VERSION ""

NS_ :

BS_:

BU_: Vector__XXX

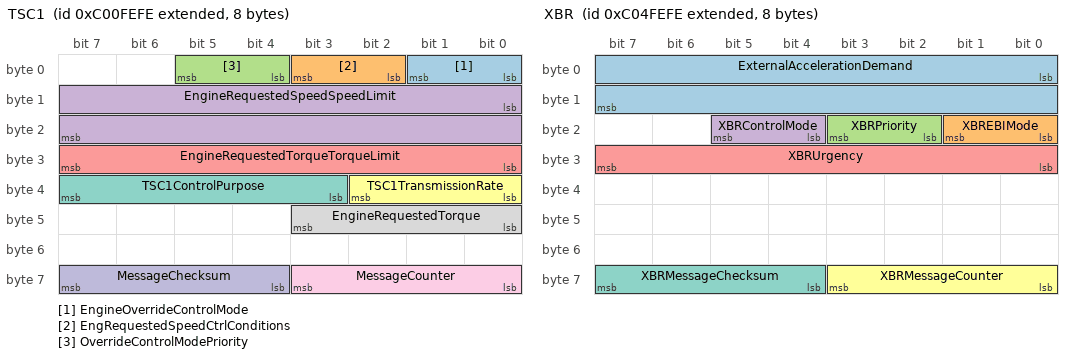
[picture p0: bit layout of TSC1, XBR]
BO_ 2348875518 TSC1: 8 Vector__XXX
SG_ EngineOverrideControlMode : 0|2@1+ (1,0) [0|3] "" Vector__XXX
SG_ EngRequestedSpeedCtrlConditions : 2|2@1+ (1,0) [0|3] "" Vector__XXX
SG_ OverrideControlModePriority : 4|2@1+ (1,0) [0|3] "" Vector__XXX
SG_ EngineRequestedSpeedSpeedLimit : 8|16@1+ (0.125,0) [0|8031.875] "rpm" Vector__XXX
SG_ EngineRequestedTorqueTorqueLimit : 24|8@1+ (1,-125) [-125|125] "%" Vector__XXX
SG_ TSC1TransmissionRate : 32|3@1+ (1,0) [0|7] "" Vector__XXX
SG_ TSC1ControlPurpose : 35|5@1+ (1,0) [0|31] "" Vector__XXX
SG_ EngineRequestedTorque : 40|4@1+ (0.125,0) [0|0.875] "%" Vector__XXX
SG_ MessageCounter : 56|4@1+ (1,0) [0|15] "" Vector__XXX
SG_ MessageChecksum : 60|4@1+ (1,0) [0|15] "" Vector__XXX

BO_ 2348941054 TC1: 8 Vector__XXX
SG_ TransmissionGearShiftInhbtRq : 0|2@1+ (1,0) [0|3] "" Vector__XXX
SG_ TrnsmTrqCnvLockupDisableRq : 2|2@1+ (1,0) [0|3] "" Vector__XXX
SG_ DisengageDrivelineRequest : 4|2@1+ (1,0) [0|3] "" Vector__XXX
SG_ TrnsmReverseGearShftInhbtRq : 6|2@1+ (1,0) [0|3] "" Vector__XXX
SG_ RequestedPercentClutchSlip : 8|8@1+ (0.4,0) [0|100] "%" Vector__XXX
SG_ TransmissionRequestedGear : 16|8@1+ (1,-125) [-125|125] "" Vector__XXX
SG_ DisengiffLockRequestFrontAxl1 : 24|2@1+ (1,0) [0|3] "" Vector__XXX
SG_ DisengiffLockRequestFrontAxl2 : 26|2@1+ (1,0) [0|3] "" Vector__XXX
SG_ DisengageDiffLockRequestRearAxl1 : 28|2@1+ (1,0) [0|3] "" Vector__XXX
SG_ DisengageDiffLockRequestRearAxl2 : 30|2@1+ (1,0) [0|3] "" Vector__XXX
SG_ DisengageDiffLockRequestCentral : 32|2@1+ (1,0) [0|3] "" Vector__XXX
SG_ DisengiffLockRequestCentralFront : 34|2@1+ (1,0) [0|3] "" Vector__XXX
SG_ DisengiffLockRequestCentralRear : 36|2@1+ (1,0) [0|3] "" Vector__XXX
SG_ TransmissionLoadRedInhbtRequest : 38|2@1+ (1,0) [0|3] "" Vector__XXX
SG_ TransmissionMode1 : 40|2@1+ (1,0) [0|3] "" Vector__XXX
SG_ TransmissionMode2 : 42|2@1+ (1,0) [0|3] "" Vector__XXX
SG_ TransmissionMode3 : 44|2@1+ (1,0) [0|3] "" Vector__XXX
SG_ TransmissionMode4 : 46|2@1+ (1,0) [0|3] "" Vector__XXX
SG_ TransmissionAutoNeutralRequest : 48|2@1+ (1,0) [0|3] "" Vector__XXX
SG_ TransmissionRequestedLaunchGear : 50|4@1+ (1,0) [0|15] "" Vector__XXX
SG_ TrnsmShftSlctorDisplayMdeSw : 54|2@1+ (1,0) [0|3] "" Vector__XXX
SG_ TransmissionMode5 : 56|2@1+ (1,0) [0|3] "" Vector__XXX
SG_ TransmissionMode6 : 58|2@1+ (1,0) [0|3] "" Vector__XXX
SG_ TransmissionMode7 : 60|2@1+ (1,0) [0|3] "" Vector__XXX
SG_ TransmissionMode8 : 62|2@1+ (1,0) [0|3] "" Vector__XXX

BO_ 2349137662 XBR: 8 Vector__XXX
SG_ ExternalAccelerationDemand : 0|16@1+ (0.00048828125,-15.687) [-15.687|15.687] "m/s^2" Vector__XXX
SG_ XBREBIMode : 16|2@1+ (1,0) [0|3] "" Vector__XXX
SG_ XBRPriority : 18|2@1+ (1,0) [0|3] "" Vector__XXX
SG_ XBRControlMode : 20|2@1+ (1,0) [0|3] "" Vector__XXX
SG_ XBRUrgency : 24|8@1+ (0.4,0) [0|100] "%" Vector__XXX
SG_ XBRMessageCounter : 56|4@1+ (1,0) [0|15] "" Vector__XXX
SG_ XBRMessageChecksum : 60|4@1+ (1,0) [0|15] "" Vector__XXX

BO_ 2550660862 GPV4: 8 Vector__XXX
SG_ ValveLoadSensePressure : 0|16@1+ (5,0) [0|321275] "kPa" Vector__XXX
SG_ ValvePilotPressure : 16|8@1+ (16,0) [0|4000] "kPa" Vector__XXX
SG_ ValveAssemblyLoadSensePressure : 24|16@1+ (5,0) [0|321275] "kPa" Vector__XXX
SG_ ValveAssemblySupplyPressure : 40|16@1+ (5,0) [0|321275] "kPa" Vector__XXX

BO_ 2349399806 AUXIO5: 8 Vector__XXX
SG_ AuxiliaryIOChannel6 : 0|16@1+ (1,0) [0|64255] "" Vector__XXX
SG_ AuxiliaryIOChannel5 : 16|16@1+ (1,0) [0|64255] "" Vector__XXX
SG_ AuxiliaryIOChannel4 : 32|16@1+ (1,0) [0|64255] "" Vector__XXX
SG_ AuxiliaryIOChannel3 : 48|16@1+ (1,0) [0|64255] "" Vector__XXX

BO_ 2349465342 SRASI: 8 Vector__XXX
SG_ StaticRollAngle : 0|8@1+ (1,-125) [-125|125] "deg" Vector__XXX
SG_ StaticRollAngleStatus : 8|3@1+ (1,0) [0|7] "" Vector__XXX

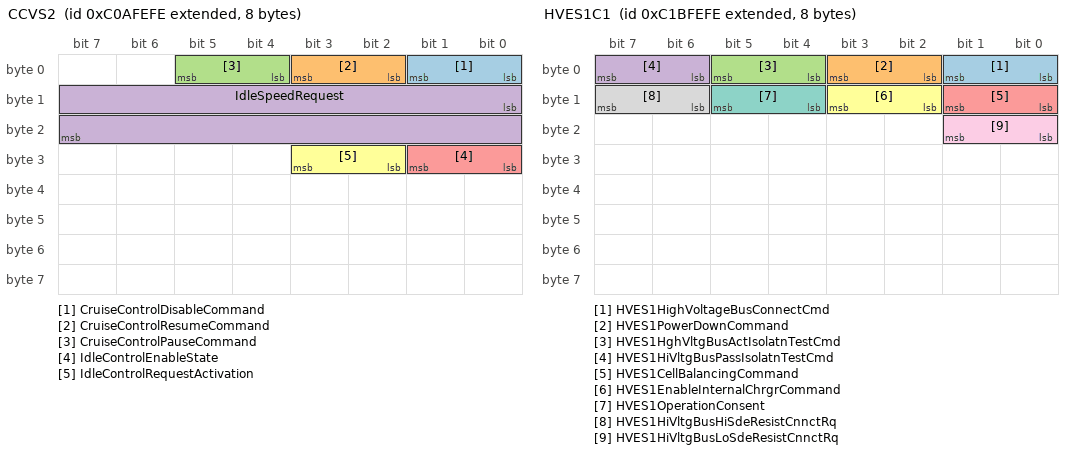
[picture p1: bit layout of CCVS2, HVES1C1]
BO_ 2349530878 CCVS2: 8 Vector__XXX
SG_ CruiseControlDisableCommand : 0|2@1+ (1,0) [0|3] "" Vector__XXX
SG_ CruiseControlResumeCommand : 2|2@1+ (1,0) [0|3] "" Vector__XXX
SG_ CruiseControlPauseCommand : 4|2@1+ (1,0) [0|3] "" Vector__XXX
SG_ IdleSpeedRequest : 8|16@1+ (0.125,0) [0|8031.875] "rpm" Vector__XXX
SG_ IdleControlEnableState : 24|2@1+ (1,0) [0|3] "" Vector__XXX
SG_ IdleControlRequestActivation : 26|2@1+ (1,0) [0|3] "" Vector__XXX

BO_ 2349596414 AEBS2: 8 Vector__XXX
SG_ DrvrActtnDmndAdvEmrgncyBrkngSys : 0|2@1+ (1,0) [0|3] "" Vector__XXX
SG_ AEBS2MessageCounter : 56|4@1+ (1,0) [0|15] "" Vector__XXX
SG_ AEBS2MessageChecksum : 60|4@1+ (1,0) [0|15] "" Vector__XXX

BO_ 2550988542 EEC16: 8 Vector__XXX
SG_ AcceleratorPedalPosition3 : 0|8@1+ (0.4,0) [0|100] "%" Vector__XXX
SG_ ReadyForClutchEngagementStatus : 8|2@1+ (1,0) [0|3] "" Vector__XXX
SG_ EngineClutchEngageRequestStatus : 10|2@1+ (1,0) [0|3] "" Vector__XXX

BO_ 2349727486 TC2: 8 Vector__XXX
SG_ TransmissionMode9 : 0|2@1+ (1,0) [0|3] "" Vector__XXX
SG_ TransmissionMode10 : 2|2@1+ (1,0) [0|3] "" Vector__XXX

BO_ 2350644990 HVES1C1: 8 Vector__XXX
SG_ HVES1HighVoltageBusConnectCmd : 0|2@1+ (1,0) [0|3] "" Vector__XXX
SG_ HVES1PowerDownCommand : 2|2@1+ (1,0) [0|3] "" Vector__XXX
SG_ HVES1HghVltgBusActIsolatnTestCmd : 4|2@1+ (1,0) [0|3] "" Vector__XXX
SG_ HVES1HiVltgBusPassIsolatnTestCmd : 6|2@1+ (1,0) [0|3] "" Vector__XXX
SG_ HVES1CellBalancingCommand : 8|2@1+ (1,0) [0|3] "" Vector__XXX
SG_ HVES1EnableInternalChrgrCommand : 10|2@1+ (1,0) [0|3] "" Vector__XXX
SG_ HVES1OperationConsent : 12|2@1+ (1,0) [0|3] "" Vector__XXX
SG_ HVES1HiVltgBusHiSdeResistCnnctRq : 14|2@1+ (1,0) [0|3] "" Vector__XXX
SG_ HVES1HiVltgBusLoSdeResistCnnctRq : 16|2@1+ (1,0) [0|3] "" Vector__XXX

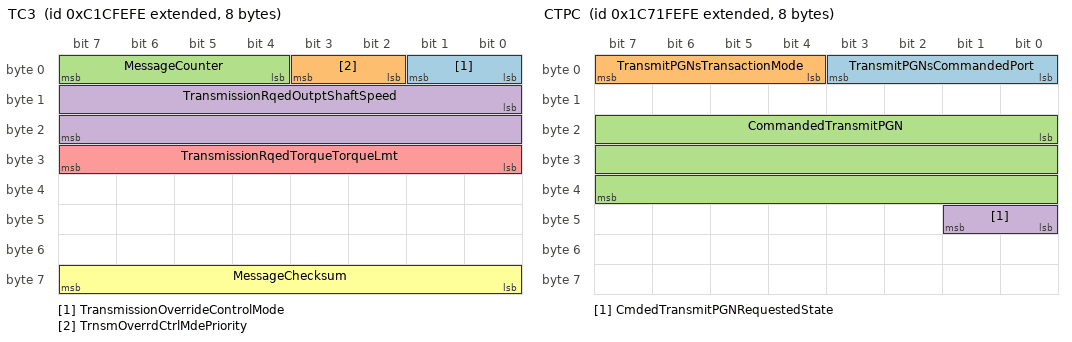
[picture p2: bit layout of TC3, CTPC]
BO_ 2350710526 TC3: 8 Vector__XXX
SG_ TransmissionOverrideControlMode : 0|2@1+ (1,0) [0|3] "" Vector__XXX
SG_ TrnsmOverrdCtrlMdePriority : 2|2@1+ (1,0) [0|3] "" Vector__XXX
SG_ MessageCounter : 4|4@1+ (1,0) [0|15] "" Vector__XXX
SG_ TransmissionRqedOutptShaftSpeed : 8|16@1+ (0.25,-8031.75) [-8031.75|8032] "rpm" Vector__XXX
SG_ TransmissionRqedTorqueTorqueLmt : 24|8@1+ (1,-125) [-125|125] "%" Vector__XXX
SG_ MessageChecksum : 56|8@1+ (1,0) [0|255] "" Vector__XXX

BO_ 2350776062 EIC: 8 Vector__XXX
SG_ EngineTimingAdvance : 0|16@1+ (0.0078125,-200) [-200|301.99] "deg" Vector__XXX

BO_ 2350841598 ALTC: 8 Vector__XXX
SG_ AlternatorSetpointVoltageCommand : 0|16@1+ (0.001,0) [0|64.255] "V" Vector__XXX
SG_ AltrntrExcitationMaximumCurrLmt : 16|8@1+ (0.25,0) [0|62.5] "A" Vector__XXX
SG_ AlternatorTorqueRampTimeCommand : 24|8@1+ (0.1,0) [0|25] "s" Vector__XXX
SG_ AltrntrTorqueRampMaximumSpeedCmd : 32|8@1+ (32,0) [0|8000] "rpm" Vector__XXX

BO_ 2557345534 WSPT1: 19 Vector__XXX
SG_ WellStimuPmpGearBxOilPrsLoTrshld : 0|16@1+ (0.1,0) [0|6425.5] "kPa" Vector__XXX
SG_ WellStimuPmpGearBxOilPrsHiTrshld : 16|16@1+ (0.1,0) [0|6425.5] "kPa" Vector__XXX
SG_ WellStimuPmpGearBxOilTmpLoTrshld : 32|8@1+ (1,-40) [-40|210] "deg C" Vector__XXX
SG_ WellStimuPmpGearBxOilTmpHiTrshld : 40|8@1+ (1,-40) [-40|210] "deg C" Vector__XXX
SG_ WellStimuPmpSuctionPrsLoTrshld : 48|16@1+ (0.1,-3212.7) [-3212.7|3212.8] "kPa" Vector__XXX
SG_ WellStimuPmpSuctionPrsHiTrshld : 64|16@1+ (0.1,-3212.7) [-3212.7|3212.8] "kPa" Vector__XXX
SG_ WellStimuPmpDisChrgPrsHiTrshld : 80|16@1+ (5,0) [0|321275] "kPa" Vector__XXX
SG_ WellStimultnPmpCrankSpdLowTrshld : 96|16@1+ (0.125,0) [0|8031.875] "rpm" Vector__XXX
SG_ WellStimultnPmpCrankSpdHghTrshld : 112|16@1+ (0.125,0) [0|8031.875] "rpm" Vector__XXX
SG_ WellStimultnPmpRodLoadHghTrshld : 128|16@1+ (5,0) [0|321275] "kN" Vector__XXX
SG_ WellStimuPmpPlungerFiringOrder : 144|4@1+ (1,0) [0|15] "" Vector__XXX

BO_ 2624519934 CRSC: 8 Vector__XXX
SG_ ReceiveSPNsCommandedPort : 0|4@1+ (1,0) [0|15] "" Vector__XXX
SG_ ReceiveSPNsTransactionMode : 4|4@1+ (1,0) [0|15] "" Vector__XXX
SG_ CommandedReceiveSPN : 16|19@1+ (1,0) [0|524287] "" Vector__XXX
SG_ CmdedReceiveSPNRequestedState : 32|2@1+ (1,0) [0|3] "" Vector__XXX
SG_ CommandedReceiveSPNSourceAddress : 40|8@1+ (1,0) [0|255] "" Vector__XXX

BO_ 2624716542 CTPC: 8 Vector__XXX
SG_ TransmitPGNsCommandedPort : 0|4@1+ (1,0) [0|15] "" Vector__XXX
SG_ TransmitPGNsTransactionMode : 4|4@1+ (1,0) [0|15] "" Vector__XXX
SG_ CommandedTransmitPGN : 16|24@1+ (1,0) [0|16777215] "" Vector__XXX
SG_ CmdedTransmitPGNRequestedState : 40|2@1+ (1,0) [0|3] "" Vector__XXX

BO_ 2557673214 ODMCC: 37 Vector__XXX
SG_ OilDebrisMontConfIdntfctionNo : 0|8@1+ (1,0) [0|250] "" Vector__XXX
SG_ OilDebrisMonitorFerrsBin1CntCmd : 8|24@1+ (1,0) [0|16449535] "" Vector__XXX
SG_ OilDebrisMonitorFerrsBin2CntCmd : 32|24@1+ (1,0) [0|16449535] "" Vector__XXX
SG_ OilDebrisMonitorFerrsBin3CntCmd : 56|24@1+ (1,0) [0|16449535] "" Vector__XXX
SG_ OilDebrisMonitorFerrsBin4CntCmd : 80|24@1+ (1,0) [0|16449535] "" Vector__XXX
SG_ OilDebrisMonitorFerrsBin5CntCmd : 104|24@1+ (1,0) [0|16449535] "" Vector__XXX
SG_ OilDebrisMonitorFerrsBin6CntCmd : 128|24@1+ (1,0) [0|16449535] "" Vector__XXX
SG_ OilDebrisMontNonFerrsBin1CntCmd : 152|24@1+ (1,0) [0|16449535] "" Vector__XXX
SG_ OilDebrisMontNonFerrsBin2CntCmd : 176|24@1+ (1,0) [0|16449535] "" Vector__XXX
SG_ OilDebrisMontNonFerrsBin3CntCmd : 200|24@1+ (1,0) [0|16449535] "" Vector__XXX
SG_ OilDebrisMontNonFerrsBin4CntCmd : 224|24@1+ (1,0) [0|16449535] "" Vector__XXX
SG_ OilDebrisMontNonFerrsBin5CntCmd : 248|24@1+ (1,0) [0|16449535] "" Vector__XXX
SG_ OilDebrisMontNonFerrsBin6CntCmd : 272|24@1+ (1,0) [0|16449535] "" Vector__XXX

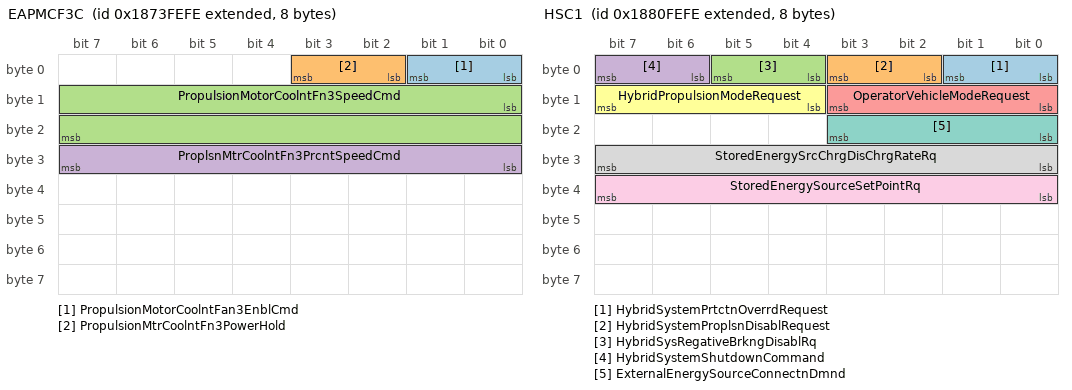
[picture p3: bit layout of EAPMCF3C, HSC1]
BO_ 2557738750 EAPMCF3C: 8 Vector__XXX
SG_ PropulsionMotorCoolntFan3EnblCmd : 0|2@1+ (1,0) [0|3] "" Vector__XXX
SG_ PropulsionMtrCoolntFn3PowerHold : 2|2@1+ (1,0) [0|3] "" Vector__XXX
SG_ PropulsionMotorCoolntFn3SpeedCmd : 8|16@1+ (0.5,0) [0|32127.5] "rpm" Vector__XXX
SG_ ProplsnMtrCoolntFn3PrcntSpeedCmd : 24|8@1+ (0.5,0) [0|125] "%" Vector__XXX

BO_ 2557804286 EAPMCF2C: 8 Vector__XXX
SG_ PropulsionMotorCoolntFan2EnblCmd : 0|2@1+ (1,0) [0|3] "" Vector__XXX
SG_ PropulsionMtrCoolntFn2PowerHold : 2|2@1+ (1,0) [0|3] "" Vector__XXX
SG_ PropulsionMotorCoolntFn2SpeedCmd : 8|16@1+ (0.5,0) [0|32127.5] "rpm" Vector__XXX
SG_ ProplsnMtrCoolntFn2PrcntSpeedCmd : 24|8@1+ (0.5,0) [0|125] "%" Vector__XXX

BO_ 2557869822 EAPMCF1C: 8 Vector__XXX
SG_ PropulsionMotorCoolntFan1EnblCmd : 0|2@1+ (1,0) [0|3] "" Vector__XXX
SG_ PropulsionMtrCoolntFn1PowerHold : 2|2@1+ (1,0) [0|3] "" Vector__XXX
SG_ PropulsionMotorCoolntFn1SpeedCmd : 8|16@1+ (0.5,0) [0|32127.5] "rpm" Vector__XXX
SG_ ProplsnMtrCoolntFn1PrcntSpeedCmd : 24|8@1+ (0.5,0) [0|125] "%" Vector__XXX

BO_ 2557935358 EAPECF3C: 8 Vector__XXX
SG_ PowerElctrncsCoolntFan3EnableCmd : 0|2@1+ (1,0) [0|3] "" Vector__XXX
SG_ PowerElctrncsCoolntFan3PowerHold : 2|2@1+ (1,0) [0|3] "" Vector__XXX
SG_ PowerElctrncsCoolntFan3SpeedCmd : 8|16@1+ (0.5,0) [0|32127.5] "rpm" Vector__XXX
SG_ PwrElctrncsCoolntFn3PrcntSpdCmd : 24|8@1+ (0.5,0) [0|125] "%" Vector__XXX

BO_ 2558000894 EAPECF2C: 8 Vector__XXX
SG_ PowerElctrncsCoolntFan2EnableCmd : 0|2@1+ (1,0) [0|3] "" Vector__XXX
SG_ PowerElctrncsCoolntFan2PowerHold : 2|2@1+ (1,0) [0|3] "" Vector__XXX
SG_ PowerElctrncsCoolntFan2SpeedCmd : 8|16@1+ (0.5,0) [0|32127.5] "rpm" Vector__XXX
SG_ PwrElctrncsCoolntFn2PrcntSpdCmd : 24|8@1+ (0.5,0) [0|125] "%" Vector__XXX

BO_ 2558066430 EAPECF1C: 8 Vector__XXX
SG_ PowerElctrncsCoolntFan1EnableCmd : 0|2@1+ (1,0) [0|3] "" Vector__XXX
SG_ PowerElctrncsCoolntFan1PowerHold : 2|2@1+ (1,0) [0|3] "" Vector__XXX
SG_ PowerElctrncsCoolntFan1SpeedCmd : 8|16@1+ (0.5,0) [0|32127.5] "rpm" Vector__XXX
SG_ PwrElctrncsCoolntFn1PrcntSpdCmd : 24|8@1+ (0.5,0) [0|125] "%" Vector__XXX

BO_ 2558131966 EAPMOPC: 8 Vector__XXX
SG_ PropulsionMotorOilPumpEnableCmd : 0|2@1+ (1,0) [0|3] "" Vector__XXX
SG_ PropulsionMotorOilPumpPowerHold : 2|2@1+ (1,0) [0|3] "" Vector__XXX
SG_ PropulsionMotorOilPumpSpeedCmd : 8|16@1+ (0.5,0) [0|32127.5] "rpm" Vector__XXX
SG_ ProplsnMtrOilPumpPrcntSpeedCmd : 24|8@1+ (0.5,0) [0|125] "%" Vector__XXX

BO_ 2558197502 EAPMCPC: 8 Vector__XXX
SG_ PropulsionMotorCoolntPumpEnblCmd : 0|2@1+ (1,0) [0|3] "" Vector__XXX
SG_ PropulsionMtrCoolntPumpPowerHold : 2|2@1+ (1,0) [0|3] "" Vector__XXX
SG_ PropulsionMtrCoolntPumpSpeedCmd : 8|16@1+ (0.5,0) [0|32127.5] "rpm" Vector__XXX
SG_ ProplsnMtrCoolntPmpPrcntSpeedCmd : 24|8@1+ (0.5,0) [0|125] "%" Vector__XXX

BO_ 2558263038 EAPECPC: 8 Vector__XXX
SG_ PowerElctrncsCoolntPumpEnableCmd : 0|2@1+ (1,0) [0|3] "" Vector__XXX
SG_ PowerElctrncsCoolntPumpPowerHold : 2|2@1+ (1,0) [0|3] "" Vector__XXX
SG_ PowerElctrncsCoolntPumpSpeedCmd : 8|16@1+ (0.5,0) [0|32127.5] "rpm" Vector__XXX
SG_ PwrElctrncsCoolntPmpPrcntSpdCmd : 24|8@1+ (0.5,0) [0|125] "%" Vector__XXX

BO_ 2558394110 EAMC: 8 Vector__XXX
SG_ ElectrifiedAccssryMotorEnableCmd : 0|2@1+ (1,0) [0|3] "" Vector__XXX
SG_ ElectrifiedAccssryMotorPowerHold : 2|2@1+ (1,0) [0|3] "" Vector__XXX
SG_ ElectrifiedAccssryMotorSpeedCmd : 8|16@1+ (0.5,0) [0|32127.5] "rpm" Vector__XXX
SG_ ElectrfdAccssryMtrPrcntSpeedCmd : 24|8@1+ (0.5,0) [0|125] "%" Vector__XXX
SG_ ElectrifiedAccssryMotorInstance1 : 32|1@1+ (1,0) [0|1] "" Vector__XXX
SG_ ElectrifiedAccssryMotorInstance2 : 33|1@1+ (1,0) [0|1] "" Vector__XXX
SG_ ElectrifiedAccssryMotorInstance3 : 34|1@1+ (1,0) [0|1] "" Vector__XXX
SG_ ElectrifiedAccssryMotorInstance4 : 35|1@1+ (1,0) [0|1] "" Vector__XXX
SG_ ElectrifiedAccssryMotorInstance5 : 36|1@1+ (1,0) [0|1] "" Vector__XXX
SG_ ElectrifiedAccssryMotorInstance6 : 37|1@1+ (1,0) [0|1] "" Vector__XXX
SG_ ElectrifiedAccssryMotorInstance7 : 38|1@1+ (1,0) [0|1] "" Vector__XXX
SG_ ElectrifiedAccssryMotorInstance8 : 39|1@1+ (1,0) [0|1] "" Vector__XXX
SG_ ElectrifiedAccssryMotorInstance9 : 40|1@1+ (1,0) [0|1] "" Vector__XXX
SG_ ElectrfdAccssryMotorInstance10 : 41|1@1+ (1,0) [0|1] "" Vector__XXX
SG_ ElectrfdAccssryMotorInstance11 : 42|1@1+ (1,0) [0|1] "" Vector__XXX
SG_ ElectrfdAccssryMotorInstance12 : 43|1@1+ (1,0) [0|1] "" Vector__XXX
SG_ ElectrfdAccssryMotorInstance13 : 44|1@1+ (1,0) [0|1] "" Vector__XXX
SG_ ElectrfdAccssryMotorInstance14 : 45|1@1+ (1,0) [0|1] "" Vector__XXX
SG_ ElectrfdAccssryMotorInstance15 : 46|1@1+ (1,0) [0|1] "" Vector__XXX

BO_ 2558459646 ESRRBR: 8 Vector__XXX
SG_ RequestedEngSpeedAccltnRateLimit : 0|16@1+ (1,0) [0|64255] "rpm/s" Vector__XXX
SG_ RqedEngSpeedDecelerationRateLmt : 16|16@1+ (1,0) [0|64255] "rpm/s" Vector__XXX

BO_ 2558525182 TSIC: 200 Vector__XXX
SG_ NumberOfTireSensors : 0|8@1+ (1,0) [0|250] "" Vector__XXX
SG_ TireNumber : 0|8@1+ (1,0) [0|250] "" Vector__XXX
SG_ TireLocation : 0|8@1+ (1,0) [0|255] "" Vector__XXX
SG_ TireSensorIdentificationNumber : 7|1600@0+ (1,0) [0|0] "ASCII" Vector__XXX

BO_ 2558590718 HSC1: 8 Vector__XXX
SG_ HybridSystemPrtctnOverrdRequest : 0|2@1+ (1,0) [0|3] "" Vector__XXX
SG_ HybridSystemProplsnDisablRequest : 2|2@1+ (1,0) [0|3] "" Vector__XXX
SG_ HybridSysRegativeBrkngDisablRq : 4|2@1+ (1,0) [0|3] "" Vector__XXX
SG_ HybridSystemShutdownCommand : 6|2@1+ (1,0) [0|3] "" Vector__XXX
SG_ OperatorVehicleModeRequest : 8|4@1+ (1,0) [0|15] "" Vector__XXX
SG_ HybridPropulsionModeRequest : 12|4@1+ (1,0) [0|15] "" Vector__XXX
SG_ ExternalEnergySourceConnectnDmnd : 16|4@1+ (1,0) [0|15] "" Vector__XXX
SG_ StoredEnergySrcChrgDisChrgRateRq : 24|8@1+ (0.4,0) [0|100] "%" Vector__XXX
SG_ StoredEnergySourceSetPointRq : 32|8@1+ (0.4,0) [0|100] "%" Vector__XXX

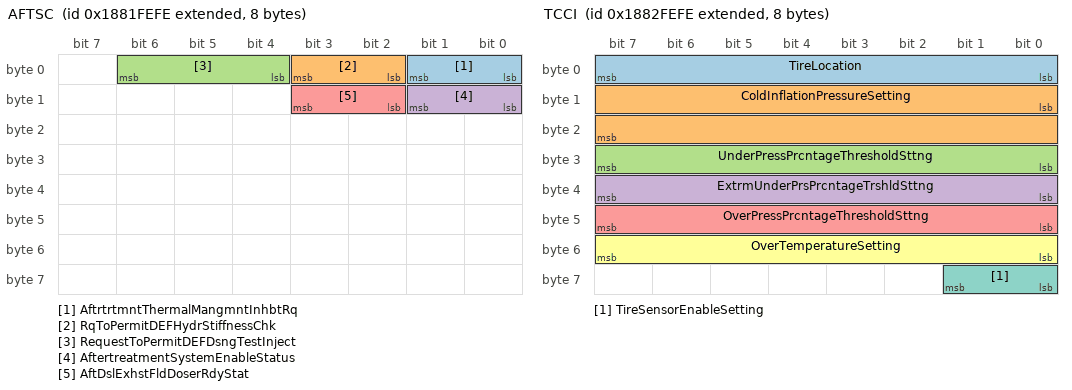
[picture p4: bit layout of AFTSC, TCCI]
BO_ 2558656254 AFTSC: 8 Vector__XXX
SG_ AftrtrtmntThermalMangmntInhbtRq : 0|2@1+ (1,0) [0|3] "" Vector__XXX
SG_ RqToPermitDEFHydrStiffnessChk : 2|2@1+ (1,0) [0|3] "" Vector__XXX
SG_ RequestToPermitDEFDsngTestInject : 4|3@1+ (1,0) [0|7] "" Vector__XXX
SG_ AftertreatmentSystemEnableStatus : 8|2@1+ (1,0) [0|3] "" Vector__XXX
SG_ AftDslExhstFldDoserRdyStat : 10|2@1+ (1,0) [0|3] "" Vector__XXX

BO_ 2558721790 TCCI: 8 Vector__XXX
SG_ TireLocation : 0|8@1+ (1,0) [0|255] "" Vector__XXX
SG_ ColdInflationPressureSetting : 8|16@1+ (1,0) [0|64255] "kPa" Vector__XXX
SG_ UnderPressPrcntageThresholdSttng : 24|8@1+ (0.5,0) [0|125] "%" Vector__XXX
SG_ ExtrmUnderPrsPrcntageTrshldSttng : 32|8@1+ (0.5,0) [0|125] "%" Vector__XXX
SG_ OverPressPrcntageThresholdSttng : 40|8@1+ (0.5,0) [0|125] "%" Vector__XXX
SG_ OverTemperatureSetting : 48|8@1+ (1,-40) [-40|210] "deg C" Vector__XXX
SG_ TireSensorEnableSetting : 56|2@1+ (1,0) [0|3] "" Vector__XXX

BO_ 2558787326 PCIC: 8 Vector__XXX
SG_ PayloadClbrtnSetPointCommand : 0|4@1+ (1,0) [0|15] "" Vector__XXX
SG_ PayloadClbrtnCommandedWeight : 8|16@1+ (2,0) [0|128510] "kg" Vector__XXX
SG_ PayloadCorrectionFactorCommand : 24|8@1+ (1,-125) [-125|125] "%" Vector__XXX

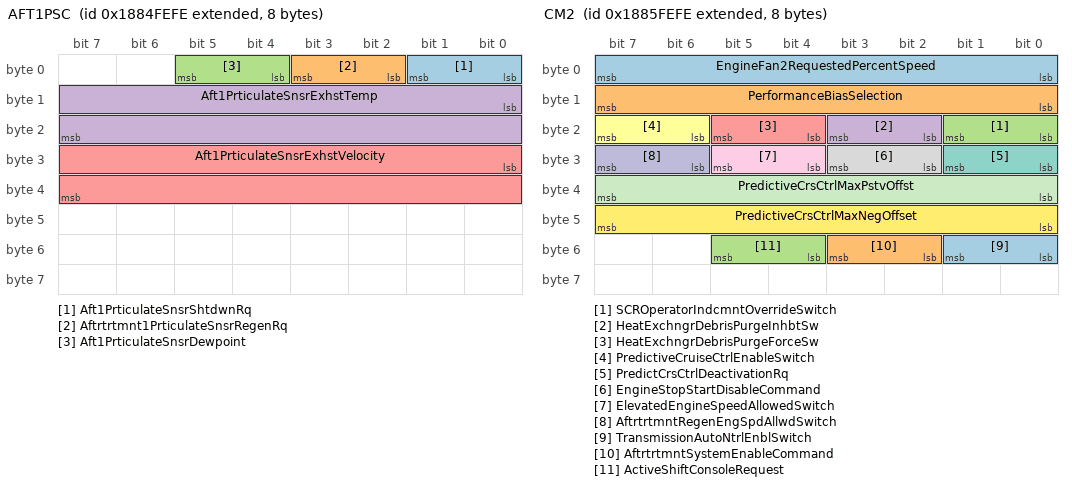
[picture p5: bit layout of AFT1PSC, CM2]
BO_ 2558852862 AFT1PSC: 8 Vector__XXX
SG_ Aft1PrticulateSnsrShtdwnRq : 0|2@1+ (1,0) [0|3] "" Vector__XXX
SG_ Aftrtrtmnt1PrticulateSnsrRegenRq : 2|2@1+ (1,0) [0|3] "" Vector__XXX
SG_ Aft1PrticulateSnsrDewpoint : 4|2@1+ (1,0) [0|3] "" Vector__XXX
SG_ Aft1PrticulateSnsrExhstTemp : 8|16@1+ (0.03125,-273) [-273|1734.96875] "deg C" Vector__XXX
SG_ Aft1PrticulateSnsrExhstVelocity : 24|16@1+ (0.00390625,0) [0|250.996] "km/h" Vector__XXX

BO_ 2558918398 CM2: 8 Vector__XXX
SG_ EngineFan2RequestedPercentSpeed : 0|8@1+ (0.4,0) [0|100] "%" Vector__XXX
SG_ PerformanceBiasSelection : 8|8@1+ (0.4,0) [0|100] "%" Vector__XXX
SG_ SCROperatorIndcmntOverrideSwitch : 16|2@1+ (1,0) [0|3] "" Vector__XXX
SG_ HeatExchngrDebrisPurgeInhbtSw : 18|2@1+ (1,0) [0|3] "" Vector__XXX
SG_ HeatExchngrDebrisPurgeForceSw : 20|2@1+ (1,0) [0|3] "" Vector__XXX
SG_ PredictiveCruiseCtrlEnableSwitch : 22|2@1+ (1,0) [0|3] "" Vector__XXX
SG_ PredictCrsCtrlDeactivationRq : 24|2@1+ (1,0) [0|3] "" Vector__XXX
SG_ EngineStopStartDisableCommand : 26|2@1+ (1,0) [0|3] "" Vector__XXX
SG_ ElevatedEngineSpeedAllowedSwitch : 28|2@1+ (1,0) [0|3] "" Vector__XXX
SG_ AftrtrtmntRegenEngSpdAllwdSwitch : 30|2@1+ (1,0) [0|3] "" Vector__XXX
SG_ PredictiveCrsCtrlMaxPstvOffst : 32|8@1+ (0.125,0) [0|31.25] "km/h" Vector__XXX
SG_ PredictiveCrsCtrlMaxNegOffset : 40|8@1+ (0.125,-31.25) [-31.25|0] "km/h" Vector__XXX
SG_ TransmissionAutoNtrlEnblSwitch : 48|2@1+ (1,0) [0|3] "" Vector__XXX
SG_ AftrtrtmntSystemEnableCommand : 50|2@1+ (1,0) [0|3] "" Vector__XXX
SG_ ActiveShiftConsoleRequest : 52|2@1+ (1,0) [0|3] "" Vector__XXX

BO_ 2558983934 SPOC: 8 Vector__XXX
SG_ SwitchedPowerOutput4Command : 0|2@1+ (1,0) [0|3] "" Vector__XXX
SG_ SwitchedPowerOutput3Command : 2|2@1+ (1,0) [0|3] "" Vector__XXX
SG_ SwitchedPowerOutput2Command : 4|2@1+ (1,0) [0|3] "" Vector__XXX
SG_ SwitchedPowerOutput1Command : 6|2@1+ (1,0) [0|3] "" Vector__XXX
SG_ SwitchedPowerOutput8Command : 8|2@1+ (1,0) [0|3] "" Vector__XXX
SG_ SwitchedPowerOutput7Command : 10|2@1+ (1,0) [0|3] "" Vector__XXX
SG_ SwitchedPowerOutput6Command : 12|2@1+ (1,0) [0|3] "" Vector__XXX
SG_ SwitchedPowerOutput5Command : 14|2@1+ (1,0) [0|3] "" Vector__XXX
SG_ SwitchedPowerOutput12Command : 16|2@1+ (1,0) [0|3] "" Vector__XXX
SG_ SwitchedPowerOutput11Command : 18|2@1+ (1,0) [0|3] "" Vector__XXX
SG_ SwitchedPowerOutput10Command : 20|2@1+ (1,0) [0|3] "" Vector__XXX
SG_ SwitchedPowerOutput9Command : 22|2@1+ (1,0) [0|3] "" Vector__XXX
SG_ SwitchedPowerOutput16Command : 24|2@1+ (1,0) [0|3] "" Vector__XXX
SG_ SwitchedPowerOutput15Command : 26|2@1+ (1,0) [0|3] "" Vector__XXX
SG_ SwitchedPowerOutput14Command : 28|2@1+ (1,0) [0|3] "" Vector__XXX
SG_ SwitchedPowerOutput13Command : 30|2@1+ (1,0) [0|3] "" Vector__XXX
SG_ SwitchedPowerOutput20Command : 32|2@1+ (1,0) [0|3] "" Vector__XXX
SG_ SwitchedPowerOutput19Command : 34|2@1+ (1,0) [0|3] "" Vector__XXX
SG_ SwitchedPowerOutput18Command : 36|2@1+ (1,0) [0|3] "" Vector__XXX
SG_ SwitchedPowerOutput17Command : 38|2@1+ (1,0) [0|3] "" Vector__XXX
SG_ SwitchedPowerOutput24Command : 40|2@1+ (1,0) [0|3] "" Vector__XXX
SG_ SwitchedPowerOutput23Command : 42|2@1+ (1,0) [0|3] "" Vector__XXX
SG_ SwitchedPowerOutput22Command : 44|2@1+ (1,0) [0|3] "" Vector__XXX
SG_ SwitchedPowerOutput21Command : 46|2@1+ (1,0) [0|3] "" Vector__XXX
SG_ SwitchedPowerOutput28Command : 48|2@1+ (1,0) [0|3] "" Vector__XXX
SG_ SwitchedPowerOutput27Command : 50|2@1+ (1,0) [0|3] "" Vector__XXX
SG_ SwitchedPowerOutput26Command : 52|2@1+ (1,0) [0|3] "" Vector__XXX
SG_ SwitchedPowerOutput25Command : 54|2@1+ (1,0) [0|3] "" Vector__XXX
SG_ SwitchedPowerOutput32Command : 56|2@1+ (1,0) [0|3] "" Vector__XXX
SG_ SwitchedPowerOutput31Command : 58|2@1+ (1,0) [0|3] "" Vector__XXX
SG_ SwitchedPowerOutput30Command : 60|2@1+ (1,0) [0|3] "" Vector__XXX
SG_ SwitchedPowerOutput29Command : 62|2@1+ (1,0) [0|3] "" Vector__XXX

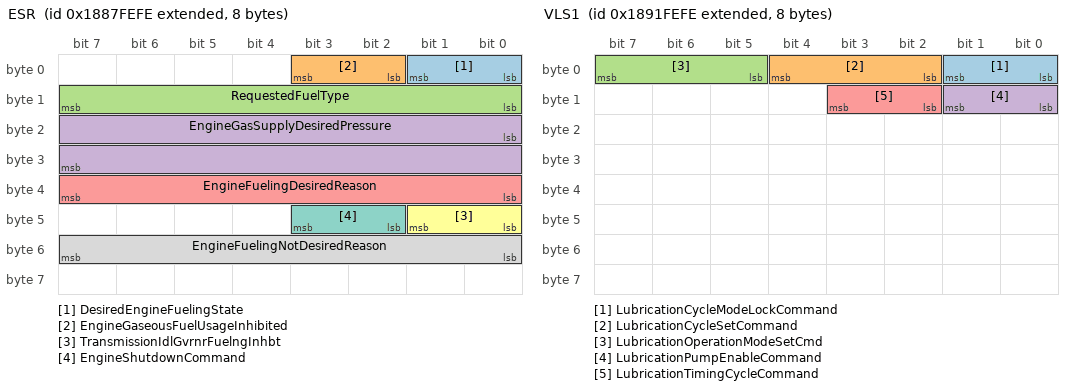
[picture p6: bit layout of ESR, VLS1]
BO_ 2559049470 ESR: 8 Vector__XXX
SG_ DesiredEngineFuelingState : 0|2@1+ (1,0) [0|3] "" Vector__XXX
SG_ EngineGaseousFuelUsageInhibited : 2|2@1+ (1,0) [0|3] "" Vector__XXX
SG_ RequestedFuelType : 8|8@1+ (1,0) [0|255] "" Vector__XXX
SG_ EngineGasSupplyDesiredPressure : 16|16@1+ (0.5,0) [0|32127.5] "kPa" Vector__XXX
SG_ EngineFuelingDesiredReason : 32|8@1+ (1,0) [0|255] "" Vector__XXX
SG_ TransmissionIdlGvrnrFuelngInhbt : 40|2@1+ (1,0) [0|3] "" Vector__XXX
SG_ EngineShutdownCommand : 42|2@1+ (1,0) [0|3] "" Vector__XXX
SG_ EngineFuelingNotDesiredReason : 48|8@1+ (1,0) [0|255] "" Vector__XXX

BO_ 2559115006 RBR: 8 Vector__XXX
SG_ UniqueBeaconMessageIdentifierNo : 0|16@1+ (1,0) [0|64255] "" Vector__XXX
SG_ RadioBeaconDirection : 22|2@1+ (1,0) [0|3] "" Vector__XXX
SG_ TransmitterID2 : 24|24@1+ (1,0) [0|16449635] "" Vector__XXX
SG_ WirelessSignalStrength2 : 48|8@1+ (0.5,-125) [-125|0] "dBm" Vector__XXX

BO_ 2559311614 CCP_DTO: 0 Vector__XXX

BO_ 2559377150 CCP_CRO: 0 Vector__XXX

BO_ 2559573758 ECC: 8 Vector__XXX
SG_ CoolntLvlEngPrtctnShtdwnOvrrdCmd : 0|2@1+ (1,0) [0|3] "" Vector__XXX

BO_ 2559639294 SFC: 8 Vector__XXX
SG_ SupplementalFanEnableCommand : 0|2@1+ (1,0) [0|3] "" Vector__XXX
SG_ SupplementalFanDirectionCommand : 2|2@1+ (1,0) [0|3] "" Vector__XXX
SG_ SupplementalFanSpeedCommand : 8|16@1+ (0.5,0) [0|32127.5] "rpm" Vector__XXX
SG_ SupplementalFanPowerHold : 24|2@1+ (1,0) [0|3] "" Vector__XXX

BO_ 2559704830 VLS1: 8 Vector__XXX
SG_ LubricationCycleModeLockCommand : 0|2@1+ (1,0) [0|3] "" Vector__XXX
SG_ LubricationCycleSetCommand : 2|3@1+ (1,0) [0|7] "" Vector__XXX
SG_ LubricationOperationModeSetCmd : 5|3@1+ (1,0) [0|7] "" Vector__XXX
SG_ LubricationPumpEnableCommand : 8|2@1+ (1,0) [0|3] "" Vector__XXX
SG_ LubricationTimingCycleCommand : 10|2@1+ (1,0) [0|3] "" Vector__XXX

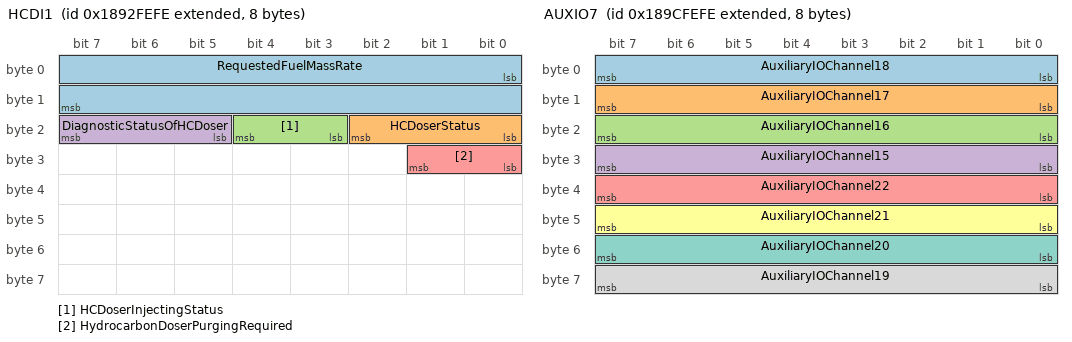
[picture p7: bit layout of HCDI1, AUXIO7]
BO_ 2559770366 HCDI1: 8 Vector__XXX
SG_ RequestedFuelMassRate : 0|16@1+ (0.05,0) [0|3212.75] "g/m" Vector__XXX
SG_ HCDoserStatus : 16|3@1+ (1,0) [0|7] "" Vector__XXX
SG_ HCDoserInjectingStatus : 19|2@1+ (1,0) [0|3] "" Vector__XXX
SG_ DiagnosticStatusOfHCDoser : 21|3@1+ (1,0) [0|7] "" Vector__XXX
SG_ HydrocarbonDoserPurgingRequired : 24|2@1+ (1,0) [0|3] "" Vector__XXX

BO_ 2559835902 NM: 8 Vector__XXX
SG_ NAMEChecksumErrorCode : 0|8@1+ (1,0) [0|255] "" Vector__XXX
SG_ ManufacturerCodeQualifierFlag : 8|1@1+ (1,0) [0|1] "" Vector__XXX
SG_ ECUInstanceQualifierFlag : 9|1@1+ (1,0) [0|1] "" Vector__XXX
SG_ FunctionInstanceQualifierFlag : 10|1@1+ (1,0) [0|1] "" Vector__XXX
SG_ FunctionQualifierFlag : 11|1@1+ (1,0) [0|1] "" Vector__XXX
SG_ VehicleSystemQualifierFlag : 12|1@1+ (1,0) [0|1] "" Vector__XXX
SG_ VehicleSystemInstanceQulfrFlg : 13|1@1+ (1,0) [0|1] "" Vector__XXX
SG_ IndustryGroupQualifierFlag : 14|1@1+ (1,0) [0|1] "" Vector__XXX
SG_ ArbtrryAddrCapableQualifierFlag : 15|1@1+ (1,0) [0|1] "" Vector__XXX
SG_ NMControlModeIndicator : 16|4@1+ (1,0) [0|15] "" Vector__XXX
SG_ CommandedManufacturerCode : 21|11@1+ (1,0) [0|2047] "" Vector__XXX
SG_ CommandedECUInstance : 32|3@1+ (1,0) [0|7] "" Vector__XXX
SG_ CommandedFunctionInstance : 35|5@1+ (1,0) [0|31] "" Vector__XXX
SG_ CommandedFunction : 40|8@1+ (1,0) [0|255] "" Vector__XXX
SG_ CommandedVehicleSystem : 49|7@1+ (1,0) [0|127] "" Vector__XXX
SG_ CommandedVehicleSystemInstance : 56|4@1+ (1,0) [0|15] "" Vector__XXX
SG_ CommandedIndustryGroup : 60|3@1+ (1,0) [0|7] "" Vector__XXX
SG_ CommandedArbitraryAddressCapable : 63|1@1+ (1,0) [0|1] "" Vector__XXX

BO_ 2559901438 AT1DPFSSC: 8 Vector__XXX
SG_ Aft1DslPFSootMeanClbrtnOffst : 0|16@1+ (0.0025,0) [0|160.6375] "%" Vector__XXX
SG_ Aft1DslPFSootStdDviatClbrtnOffst : 16|16@1+ (0.0025,0) [0|160.6375] "%" Vector__XXX

BO_ 2559966974 AT2DPFSSC: 8 Vector__XXX
SG_ Aft2DslPFSootMeanClbrtnOffst : 0|16@1+ (0.0025,0) [0|160.6375] "%" Vector__XXX
SG_ Aft2DslPFSootStdDviatClbrtnOffst : 16|16@1+ (0.0025,0) [0|160.6375] "%" Vector__XXX

BO_ 2560032510 LVDSOM: 8 Vector__XXX
SG_ LowVoltageDiscnnctDsrdOprtngMde : 0|4@1+ (1,0) [0|15] "" Vector__XXX

BO_ 2560098046 NCS: 8 Vector__XXX
SG_ CabNoiseControlStatus : 0|2@1+ (1,0) [0|3] "" Vector__XXX
SG_ CabNoiseControlTuningStatus : 2|4@1+ (1,0) [0|15] "" Vector__XXX

BO_ 2560163582 NC1: 8 Vector__XXX
SG_ CabNoiseControlCommand : 0|2@1+ (1,0) [0|3] "" Vector__XXX
SG_ CabNoiseControlTuningCommand : 2|3@1+ (1,0) [0|7] "" Vector__XXX

BO_ 2358902526 JLCM: 8 Vector__XXX
SG_ Joystick1Lamp1Command : 0|2@1+ (1,0) [0|3] "" Vector__XXX
SG_ Joystick1Lamp2Command : 2|2@1+ (1,0) [0|3] "" Vector__XXX
SG_ Joystick1Lamp3Command : 4|2@1+ (1,0) [0|3] "" Vector__XXX
SG_ Joystick1Lamp4Command : 6|2@1+ (1,0) [0|3] "" Vector__XXX
SG_ Joystick1Lamp5Command : 8|2@1+ (1,0) [0|3] "" Vector__XXX
SG_ Joystick1Lamp6Command : 10|2@1+ (1,0) [0|3] "" Vector__XXX
SG_ Joystick1Lamp7Command : 12|2@1+ (1,0) [0|3] "" Vector__XXX
SG_ Joystick1Lamp8Command : 14|2@1+ (1,0) [0|3] "" Vector__XXX
SG_ Joystick1Lamp9Command : 16|2@1+ (1,0) [0|3] "" Vector__XXX
SG_ Joystick1Lamp10Command : 18|2@1+ (1,0) [0|3] "" Vector__XXX
SG_ Joystick2Lamp1Command : 20|2@1+ (1,0) [0|3] "" Vector__XXX
SG_ Joystick2Lamp2Command : 22|2@1+ (1,0) [0|3] "" Vector__XXX
SG_ Joystick2Lamp3Command : 24|2@1+ (1,0) [0|3] "" Vector__XXX
SG_ Joystick2Lamp4Command : 26|2@1+ (1,0) [0|3] "" Vector__XXX
SG_ Joystick2Lamp5Command : 28|2@1+ (1,0) [0|3] "" Vector__XXX
SG_ Joystick2Lamp6Command : 30|2@1+ (1,0) [0|3] "" Vector__XXX
SG_ Joystick2Lamp7Command : 32|2@1+ (1,0) [0|3] "" Vector__XXX
SG_ Joystick2Lamp8Command : 34|2@1+ (1,0) [0|3] "" Vector__XXX
SG_ Joystick2Lamp9Command : 36|2@1+ (1,0) [0|3] "" Vector__XXX
SG_ Joystick2Lamp10Command : 38|2@1+ (1,0) [0|3] "" Vector__XXX
SG_ Joystick3Lamp1Command : 40|2@1+ (1,0) [0|3] "" Vector__XXX
SG_ Joystick3Lamp2Command : 42|2@1+ (1,0) [0|3] "" Vector__XXX
SG_ Joystick3Lamp3Command : 44|2@1+ (1,0) [0|3] "" Vector__XXX
SG_ Joystick3Lamp4Command : 46|2@1+ (1,0) [0|3] "" Vector__XXX
SG_ Joystick3Lamp5Command : 48|2@1+ (1,0) [0|3] "" Vector__XXX
SG_ Joystick3Lamp6Command : 50|2@1+ (1,0) [0|3] "" Vector__XXX
SG_ Joystick3Lamp7Command : 52|2@1+ (1,0) [0|3] "" Vector__XXX
SG_ Joystick3Lamp8Command : 54|2@1+ (1,0) [0|3] "" Vector__XXX
SG_ Joystick3Lamp9Command : 56|2@1+ (1,0) [0|3] "" Vector__XXX
SG_ Joystick3Lamp10Command : 58|2@1+ (1,0) [0|3] "" Vector__XXX

BO_ 2560360190 PMI: 8 Vector__XXX
SG_ DataDictionaryManufacturerCode : 0|11@1+ (1,0) [0|2047] "" Vector__XXX
SG_ DataDictionaryMethod : 11|21@1+ (1,0) [0|2097151] "" Vector__XXX

BO_ 2560425726 AUXIO7: 8 Vector__XXX
SG_ AuxiliaryIOChannel18 : 0|8@1+ (1,0) [0|250] "" Vector__XXX
SG_ AuxiliaryIOChannel17 : 8|8@1+ (1,0) [0|250] "" Vector__XXX
SG_ AuxiliaryIOChannel16 : 16|8@1+ (1,0) [0|250] "" Vector__XXX
SG_ AuxiliaryIOChannel15 : 24|8@1+ (1,0) [0|250] "" Vector__XXX
SG_ AuxiliaryIOChannel22 : 32|8@1+ (1,0) [0|250] "" Vector__XXX
SG_ AuxiliaryIOChannel21 : 40|8@1+ (1,0) [0|250] "" Vector__XXX
SG_ AuxiliaryIOChannel20 : 48|8@1+ (1,0) [0|250] "" Vector__XXX
SG_ AuxiliaryIOChannel19 : 56|8@1+ (1,0) [0|250] "" Vector__XXX

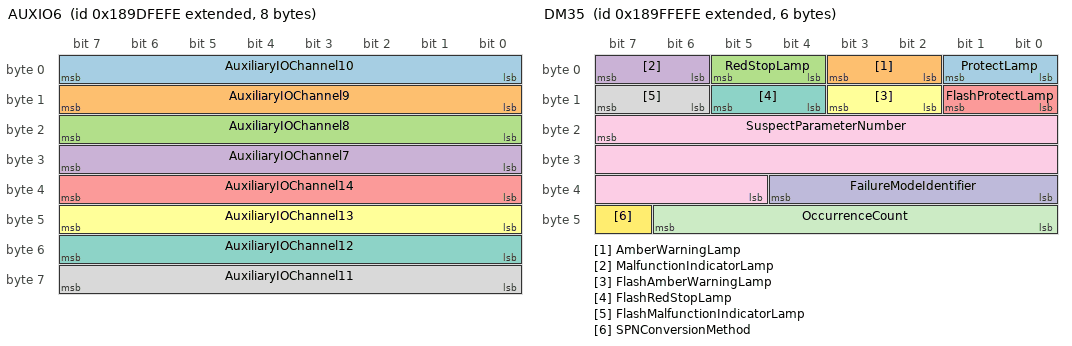
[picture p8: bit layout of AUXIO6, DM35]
BO_ 2560491262 AUXIO6: 8 Vector__XXX
SG_ AuxiliaryIOChannel10 : 0|8@1+ (1,0) [0|250] "" Vector__XXX
SG_ AuxiliaryIOChannel9 : 8|8@1+ (1,0) [0|250] "" Vector__XXX
SG_ AuxiliaryIOChannel8 : 16|8@1+ (1,0) [0|250] "" Vector__XXX
SG_ AuxiliaryIOChannel7 : 24|8@1+ (1,0) [0|250] "" Vector__XXX
SG_ AuxiliaryIOChannel14 : 32|8@1+ (1,0) [0|250] "" Vector__XXX
SG_ AuxiliaryIOChannel13 : 40|8@1+ (1,0) [0|250] "" Vector__XXX
SG_ AuxiliaryIOChannel12 : 48|8@1+ (1,0) [0|250] "" Vector__XXX
SG_ AuxiliaryIOChannel11 : 56|8@1+ (1,0) [0|250] "" Vector__XXX

BO_ 2560556798 DM29: 8 Vector__XXX
SG_ PendingDTCs : 0|8@1+ (1,0) [0|250] "" Vector__XXX
SG_ AllPendingDTCs : 8|8@1+ (1,0) [0|250] "" Vector__XXX
SG_ MILOnDTCs : 16|8@1+ (1,0) [0|250] "" Vector__XXX
SG_ PreviouslyMILOnDTCs : 24|8@1+ (1,0) [0|250] "" Vector__XXX
SG_ PermanentDTCs : 32|8@1+ (1,0) [0|250] "" Vector__XXX

BO_ 2560622334 DM35: 6 Vector__XXX
SG_ ProtectLamp : 0|2@1+ (1,0) [0|3] "" Vector__XXX
SG_ AmberWarningLamp : 2|2@1+ (1,0) [0|3] "" Vector__XXX
SG_ RedStopLamp : 4|2@1+ (1,0) [0|3] "" Vector__XXX
SG_ MalfunctionIndicatorLamp : 6|2@1+ (1,0) [0|3] "" Vector__XXX
SG_ FlashProtectLamp : 8|2@1+ (1,0) [0|3] "" Vector__XXX
SG_ FlashAmberWarningLamp : 10|2@1+ (1,0) [0|3] "" Vector__XXX
SG_ FlashRedStopLamp : 12|2@1+ (1,0) [0|3] "" Vector__XXX
SG_ FlashMalfunctionIndicatorLamp : 14|2@1+ (1,0) [0|3] "" Vector__XXX
SG_ SuspectParameterNumber : 23|19@0+ (1,0) [0|524287] "" Vector__XXX
SG_ FailureModeIdentifier : 32|5@1+ (1,0) [0|31] "" Vector__XXX
SG_ OccurrenceCount : 40|7@1+ (1,0) [0|127] "" Vector__XXX
SG_ SPNConversionMethod : 47|1@1+ (1,0) [0|1] "" Vector__XXX

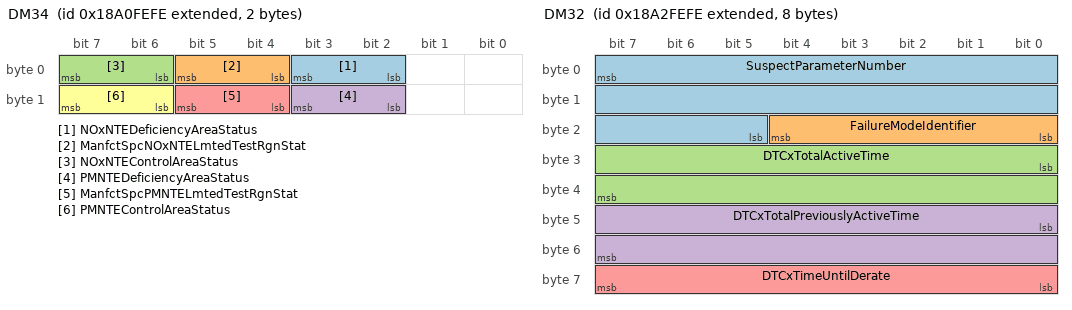
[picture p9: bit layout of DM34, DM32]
BO_ 2560687870 DM34: 2 Vector__XXX
SG_ NOxNTEDeficiencyAreaStatus : 2|2@1+ (1,0) [0|3] "" Vector__XXX
SG_ ManfctSpcNOxNTELmtedTestRgnStat : 4|2@1+ (1,0) [0|3] "" Vector__XXX
SG_ NOxNTEControlAreaStatus : 6|2@1+ (1,0) [0|3] "" Vector__XXX
SG_ PMNTEDeficiencyAreaStatus : 10|2@1+ (1,0) [0|3] "" Vector__XXX
SG_ ManfctSpcPMNTELmtedTestRgnStat : 12|2@1+ (1,0) [0|3] "" Vector__XXX
SG_ PMNTEControlAreaStatus : 14|2@1+ (1,0) [0|3] "" Vector__XXX

BO_ 2560753406 DM33: 9 Vector__XXX
SG_ EIAECDNumber : 0|8@1+ (1,0) [0|251] "" Vector__XXX
SG_ EIAECDEngineHoursTimer1 : 8|32@1+ (1,0) [0|4211081215] "" Vector__XXX
SG_ EIAECDEngineHoursTimer2 : 40|32@1+ (1,0) [0|4211081215] "" Vector__XXX

BO_ 2560818942 DM32: 8 Vector__XXX
SG_ SuspectParameterNumber : 7|19@0+ (1,0) [0|524287] "" Vector__XXX
SG_ FailureModeIdentifier : 16|5@1+ (1,0) [0|31] "" Vector__XXX
SG_ DTCxTotalActiveTime : 24|16@1+ (1,0) [0|12851] "" Vector__XXX
SG_ DTCxTotalPreviouslyActiveTime : 40|16@1+ (1,0) [0|12851] "" Vector__XXX
SG_ DTCxTimeUntilDerate : 56|8@1+ (1,0) [0|62.5] "" Vector__XXX

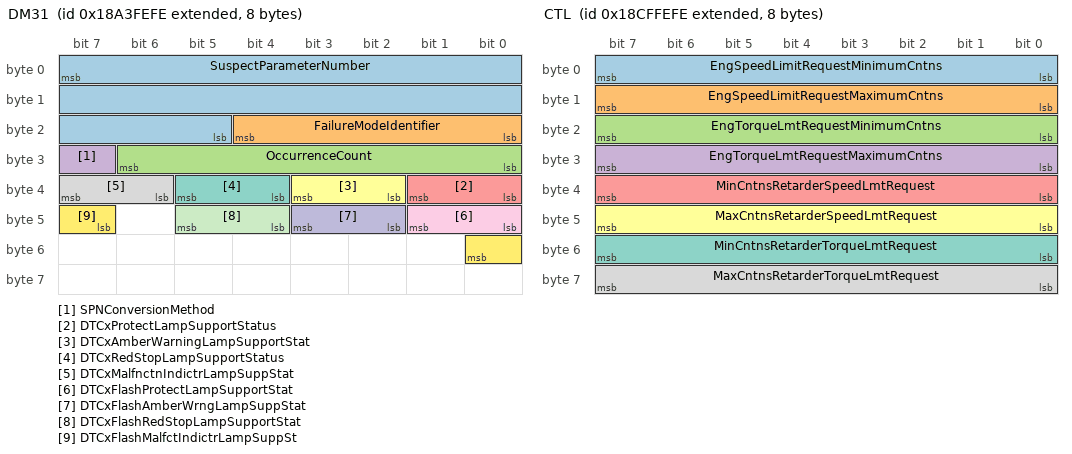
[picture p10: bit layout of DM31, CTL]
BO_ 2560884478 DM31: 8 Vector__XXX
SG_ SuspectParameterNumber : 7|19@0+ (1,0) [0|524287] "" Vector__XXX
SG_ FailureModeIdentifier : 16|5@1+ (1,0) [0|31] "" Vector__XXX
SG_ OccurrenceCount : 24|7@1+ (1,0) [0|127] "" Vector__XXX
SG_ SPNConversionMethod : 31|1@1+ (1,0) [0|1] "" Vector__XXX
SG_ DTCxProtectLampSupportStatus : 32|2@1+ (1,0) [0|3] "" Vector__XXX
SG_ DTCxAmberWarningLampSupportStat : 34|2@1+ (1,0) [0|3] "" Vector__XXX
SG_ DTCxRedStopLampSupportStatus : 36|2@1+ (1,0) [0|3] "" Vector__XXX
SG_ DTCxMalfnctnIndictrLampSuppStat : 38|2@1+ (1,0) [0|3] "" Vector__XXX
SG_ DTCxFlashProtectLampSupportStat : 40|2@1+ (1,0) [0|3] "" Vector__XXX
SG_ DTCxFlashAmberWrngLampSuppStat : 42|2@1+ (1,0) [0|3] "" Vector__XXX
SG_ DTCxFlashRedStopLampSupportStat : 44|2@1+ (1,0) [0|3] "" Vector__XXX
SG_ DTCxFlashMalfctIndictrLampSuppSt : 47|2@1+ (1,0) [0|3] "" Vector__XXX

BO_ 2560950014 DM30: 12 Vector__XXX
SG_ TestIdentifier : 0|8@1+ (1,0) [0|255] "" Vector__XXX
SG_ SuspectParameterNumber : 15|19@0+ (1,0) [0|524287] "" Vector__XXX
SG_ FailureModeIdentifier : 24|5@1+ (1,0) [0|31] "" Vector__XXX
SG_ SLOTIdentifier : 32|16@1+ (1,0) [0|64255] "" Vector__XXX
SG_ TestValue : 48|16@1+ (1,0) [0|64255] "" Vector__XXX
SG_ TestLimitMaximum : 64|16@1+ (1,0) [0|64255] "" Vector__XXX
SG_ TestLimitMinimum : 80|16@1+ (1,0) [0|64255] "" Vector__XXX

BO_ 2561015550 AUXIO4: 8 Vector__XXX
SG_ AuxiliaryIO84 : 0|2@1+ (1,0) [0|3] "" Vector__XXX
SG_ AuxiliaryIO83 : 2|2@1+ (1,0) [0|3] "" Vector__XXX
SG_ AuxiliaryIO82 : 4|2@1+ (1,0) [0|3] "" Vector__XXX
SG_ AuxiliaryIO81 : 6|2@1+ (1,0) [0|3] "" Vector__XXX
SG_ AuxiliaryIO88 : 8|2@1+ (1,0) [0|3] "" Vector__XXX
SG_ AuxiliaryIO87 : 10|2@1+ (1,0) [0|3] "" Vector__XXX
SG_ AuxiliaryIO86 : 12|2@1+ (1,0) [0|3] "" Vector__XXX
SG_ AuxiliaryIO85 : 14|2@1+ (1,0) [0|3] "" Vector__XXX
SG_ AuxiliaryIO92 : 16|2@1+ (1,0) [0|3] "" Vector__XXX
SG_ AuxiliaryIO91 : 18|2@1+ (1,0) [0|3] "" Vector__XXX
SG_ AuxiliaryIO90 : 20|2@1+ (1,0) [0|3] "" Vector__XXX
SG_ AuxiliaryIO89 : 22|2@1+ (1,0) [0|3] "" Vector__XXX
SG_ AuxiliaryIO96 : 24|2@1+ (1,0) [0|3] "" Vector__XXX
SG_ AuxiliaryIO95 : 26|2@1+ (1,0) [0|3] "" Vector__XXX
SG_ AuxiliaryIO94 : 28|2@1+ (1,0) [0|3] "" Vector__XXX
SG_ AuxiliaryIO93 : 30|2@1+ (1,0) [0|3] "" Vector__XXX
SG_ AuxiliaryIO100 : 32|2@1+ (1,0) [0|3] "" Vector__XXX
SG_ AuxiliaryIO99 : 34|2@1+ (1,0) [0|3] "" Vector__XXX
SG_ AuxiliaryIO98 : 36|2@1+ (1,0) [0|3] "" Vector__XXX
SG_ AuxiliaryIO97 : 38|2@1+ (1,0) [0|3] "" Vector__XXX
SG_ AuxiliaryIO104 : 40|2@1+ (1,0) [0|3] "" Vector__XXX
SG_ AuxiliaryIO103 : 42|2@1+ (1,0) [0|3] "" Vector__XXX
SG_ AuxiliaryIO102 : 44|2@1+ (1,0) [0|3] "" Vector__XXX
SG_ AuxiliaryIO101 : 46|2@1+ (1,0) [0|3] "" Vector__XXX
SG_ AuxiliaryIO108 : 48|2@1+ (1,0) [0|3] "" Vector__XXX
SG_ AuxiliaryIO107 : 50|2@1+ (1,0) [0|3] "" Vector__XXX
SG_ AuxiliaryIO106 : 52|2@1+ (1,0) [0|3] "" Vector__XXX
SG_ AuxiliaryIO105 : 54|2@1+ (1,0) [0|3] "" Vector__XXX
SG_ AuxiliaryIO112 : 56|2@1+ (1,0) [0|3] "" Vector__XXX
SG_ AuxiliaryIO111 : 58|2@1+ (1,0) [0|3] "" Vector__XXX
SG_ AuxiliaryIO110 : 60|2@1+ (1,0) [0|3] "" Vector__XXX
SG_ AuxiliaryIO109 : 62|2@1+ (1,0) [0|3] "" Vector__XXX

BO_ 2561081086 AUXIO3: 8 Vector__XXX
SG_ AuxiliaryIO52 : 0|2@1+ (1,0) [0|3] "" Vector__XXX
SG_ AuxiliaryIO51 : 2|2@1+ (1,0) [0|3] "" Vector__XXX
SG_ AuxiliaryIO50 : 4|2@1+ (1,0) [0|3] "" Vector__XXX
SG_ AuxiliaryIO49 : 6|2@1+ (1,0) [0|3] "" Vector__XXX
SG_ AuxiliaryIO56 : 8|2@1+ (1,0) [0|3] "" Vector__XXX
SG_ AuxiliaryIO55 : 10|2@1+ (1,0) [0|3] "" Vector__XXX
SG_ AuxiliaryIO54 : 12|2@1+ (1,0) [0|3] "" Vector__XXX
SG_ AuxiliaryIO53 : 14|2@1+ (1,0) [0|3] "" Vector__XXX
SG_ AuxiliaryIO60 : 16|2@1+ (1,0) [0|3] "" Vector__XXX
SG_ AuxiliaryIO59 : 18|2@1+ (1,0) [0|3] "" Vector__XXX
SG_ AuxiliaryIO58 : 20|2@1+ (1,0) [0|3] "" Vector__XXX
SG_ AuxiliaryIO57 : 22|2@1+ (1,0) [0|3] "" Vector__XXX
SG_ AuxiliaryIO64 : 24|2@1+ (1,0) [0|3] "" Vector__XXX
SG_ AuxiliaryIO63 : 26|2@1+ (1,0) [0|3] "" Vector__XXX
SG_ AuxiliaryIO62 : 28|2@1+ (1,0) [0|3] "" Vector__XXX
SG_ AuxiliaryIO61 : 30|2@1+ (1,0) [0|3] "" Vector__XXX
SG_ AuxiliaryIO68 : 32|2@1+ (1,0) [0|3] "" Vector__XXX
SG_ AuxiliaryIO67 : 34|2@1+ (1,0) [0|3] "" Vector__XXX
SG_ AuxiliaryIO66 : 36|2@1+ (1,0) [0|3] "" Vector__XXX
SG_ AuxiliaryIO65 : 38|2@1+ (1,0) [0|3] "" Vector__XXX
SG_ AuxiliaryIO72 : 40|2@1+ (1,0) [0|3] "" Vector__XXX
SG_ AuxiliaryIO71 : 42|2@1+ (1,0) [0|3] "" Vector__XXX
SG_ AuxiliaryIO70 : 44|2@1+ (1,0) [0|3] "" Vector__XXX
SG_ AuxiliaryIO69 : 46|2@1+ (1,0) [0|3] "" Vector__XXX
SG_ AuxiliaryIO76 : 48|2@1+ (1,0) [0|3] "" Vector__XXX
SG_ AuxiliaryIO75 : 50|2@1+ (1,0) [0|3] "" Vector__XXX
SG_ AuxiliaryIO74 : 52|2@1+ (1,0) [0|3] "" Vector__XXX
SG_ AuxiliaryIO73 : 54|2@1+ (1,0) [0|3] "" Vector__XXX
SG_ AuxiliaryIO80 : 56|2@1+ (1,0) [0|3] "" Vector__XXX
SG_ AuxiliaryIO79 : 58|2@1+ (1,0) [0|3] "" Vector__XXX
SG_ AuxiliaryIO78 : 60|2@1+ (1,0) [0|3] "" Vector__XXX
SG_ AuxiliaryIO77 : 62|2@1+ (1,0) [0|3] "" Vector__XXX

BO_ 2561146622 AUXIO2: 8 Vector__XXX
SG_ AuxiliaryIO20 : 0|2@1+ (1,0) [0|3] "" Vector__XXX
SG_ AuxiliaryIO19 : 2|2@1+ (1,0) [0|3] "" Vector__XXX
SG_ AuxiliaryIO18 : 4|2@1+ (1,0) [0|3] "" Vector__XXX
SG_ AuxiliaryIO17 : 6|2@1+ (1,0) [0|3] "" Vector__XXX
SG_ AuxiliaryIO24 : 8|2@1+ (1,0) [0|3] "" Vector__XXX
SG_ AuxiliaryIO23 : 10|2@1+ (1,0) [0|3] "" Vector__XXX
SG_ AuxiliaryIO22 : 12|2@1+ (1,0) [0|3] "" Vector__XXX
SG_ AuxiliaryIO21 : 14|2@1+ (1,0) [0|3] "" Vector__XXX
SG_ AuxiliaryIO28 : 16|2@1+ (1,0) [0|3] "" Vector__XXX
SG_ AuxiliaryIO27 : 18|2@1+ (1,0) [0|3] "" Vector__XXX
SG_ AuxiliaryIO26 : 20|2@1+ (1,0) [0|3] "" Vector__XXX
SG_ AuxiliaryIO25 : 22|2@1+ (1,0) [0|3] "" Vector__XXX
SG_ AuxiliaryIO32 : 24|2@1+ (1,0) [0|3] "" Vector__XXX
SG_ AuxiliaryIO31 : 26|2@1+ (1,0) [0|3] "" Vector__XXX
SG_ AuxiliaryIO30 : 28|2@1+ (1,0) [0|3] "" Vector__XXX
SG_ AuxiliaryIO29 : 30|2@1+ (1,0) [0|3] "" Vector__XXX
SG_ AuxiliaryIO36 : 32|2@1+ (1,0) [0|3] "" Vector__XXX
SG_ AuxiliaryIO35 : 34|2@1+ (1,0) [0|3] "" Vector__XXX
SG_ AuxiliaryIO34 : 36|2@1+ (1,0) [0|3] "" Vector__XXX
SG_ AuxiliaryIO33 : 38|2@1+ (1,0) [0|3] "" Vector__XXX
SG_ AuxiliaryIO40 : 40|2@1+ (1,0) [0|3] "" Vector__XXX
SG_ AuxiliaryIO39 : 42|2@1+ (1,0) [0|3] "" Vector__XXX
SG_ AuxiliaryIO38 : 44|2@1+ (1,0) [0|3] "" Vector__XXX
SG_ AuxiliaryIO37 : 46|2@1+ (1,0) [0|3] "" Vector__XXX
SG_ AuxiliaryIO44 : 48|2@1+ (1,0) [0|3] "" Vector__XXX
SG_ AuxiliaryIO43 : 50|2@1+ (1,0) [0|3] "" Vector__XXX
SG_ AuxiliaryIO42 : 52|2@1+ (1,0) [0|3] "" Vector__XXX
SG_ AuxiliaryIO41 : 54|2@1+ (1,0) [0|3] "" Vector__XXX
SG_ AuxiliaryIO48 : 56|2@1+ (1,0) [0|3] "" Vector__XXX
SG_ AuxiliaryIO47 : 58|2@1+ (1,0) [0|3] "" Vector__XXX
SG_ AuxiliaryIO46 : 60|2@1+ (1,0) [0|3] "" Vector__XXX
SG_ AuxiliaryIO45 : 62|2@1+ (1,0) [0|3] "" Vector__XXX

BO_ 2561212158 DISP1: 203 Vector__XXX
SG_ TextDisplayInstructions : 0|4@1+ (1,0) [0|15] "" Vector__XXX
SG_ TextDisplayIndex : 16|8@1+ (1,0) [0|250] "" Vector__XXX
SG_ TextDisplayCharacter : 31|1600@0+ (1,0) [0|0] "ASCII" Vector__XXX

BO_ 2561277694 FLIC: 8 Vector__XXX
SG_ LaneDepartureWarningEnableCmd : 0|2@1+ (1,0) [0|3] "" Vector__XXX
SG_ CurrentRegion : 15|16@0+ (1,0) [0|0] "ASCII" Vector__XXX
SG_ CurrentSubRegion : 31|24@0+ (1,0) [0|0] "ASCII" Vector__XXX

BO_ 2561408766 FSC: 0 Vector__XXX

BO_ 2561605374 TPRS: 8 Vector__XXX
SG_ TireLocation : 0|8@1+ (1,0) [0|255] "" Vector__XXX
SG_ ReferenceTirePressureSetting : 8|8@1+ (8,0) [0|2000] "kPa" Vector__XXX

BO_ 2561670910 PLM: 0 Vector__XXX

BO_ 2561736446 CIM: 0 Vector__XXX

BO_ 2561801982 PCM1: 0 Vector__XXX

BO_ 2561867518 PCM2: 0 Vector__XXX

BO_ 2561933054 PCM3: 0 Vector__XXX

BO_ 2561998590 PCM4: 0 Vector__XXX

BO_ 2562064126 PCM5: 0 Vector__XXX

BO_ 2562129662 PCM6: 0 Vector__XXX

BO_ 2562195198 PCM7: 0 Vector__XXX

BO_ 2562260734 PCM8: 0 Vector__XXX

BO_ 2562326270 PCM9: 0 Vector__XXX

BO_ 2562391806 PCM10: 0 Vector__XXX

BO_ 2562457342 PCM11: 0 Vector__XXX

BO_ 2562522878 PCM12: 0 Vector__XXX

BO_ 2562588414 PCM13: 0 Vector__XXX

BO_ 2562653950 PCM14: 0 Vector__XXX

BO_ 2562719486 PCM15: 0 Vector__XXX

BO_ 2562785022 PCM16: 0 Vector__XXX

BO_ 2562850558 DM21: 8 Vector__XXX
SG_ DistTravelledWhileMILIsActvtd : 0|16@1+ (1,0) [0|64255] "km" Vector__XXX
SG_ DistSinceDiagTroubleCodesClred : 16|16@1+ (1,0) [0|64255] "km" Vector__XXX
SG_ MinutesAccmltdWhileMILActivated : 32|16@1+ (1,0) [0|64255] "min" Vector__XXX
SG_ TimeSinceDiagTroubleCodesClred : 48|16@1+ (1,0) [0|64255] "min" Vector__XXX

BO_ 2562916094 DM20: 11 Vector__XXX
SG_ EngineIgnitionCycleCounter : 0|16@1+ (1,0) [0|65535] "" Vector__XXX
SG_ OBDMonitoringConditionsEnCntred : 16|16@1+ (1,0) [0|65535] "" Vector__XXX
SG_ SPNOfApplicableSystemMonitor : 39|19@0+ (1,0) [0|524287] "" Vector__XXX
SG_ ApplicableSystemMonitorNumerator : 56|16@1+ (1,0) [0|65535] "" Vector__XXX
SG_ ApplicableSysMonitorDenominator : 72|16@1+ (1,0) [0|65535] "" Vector__XXX

BO_ 2562981630 DM22: 8 Vector__XXX
SG_ DM22CtrlBytIndivDTCClrRstCtrlByt : 0|8@1+ (1,0) [0|255] "" Vector__XXX
SG_ DM22CtrlBytSpcIndictrIndivDTCClr : 8|8@1+ (1,0) [0|255] "" Vector__XXX
SG_ DM22SPN : 47|19@0+ (1,0) [0|524287] "" Vector__XXX
SG_ DM22FMI : 56|5@1+ (1,0) [0|31] "" Vector__XXX

BO_ 2563374846 RQST2: 8 Vector__XXX
SG_ ParameterGroupNumber : 0|24@1+ (1,0) [0|16777215] "" Vector__XXX
SG_ UseTransferMode : 24|2@1+ (1,0) [0|3] "" Vector__XXX

BO_ 2563440382 XFER: 1785 Vector__XXX
SG_ PGNOfRequestedInformation : 0|24@1+ (1,0) [0|16777215] "" Vector__XXX
SG_ LengthOfDataForTheReportedPGN : 24|8@1+ (1,0) [0|255] "" Vector__XXX
SG_ ControllerApplicationIdentity : 32|32@1+ (1,0) [0|4294967295] "" Vector__XXX

BO_ 2563636990 KWP4: 0 Vector__XXX

BO_ 2563702526 KWP3: 0 Vector__XXX

BO_ 2563768062 CTL: 8 Vector__XXX
SG_ EngSpeedLimitRequestMinimumCntns : 0|8@1+ (32,0) [0|8000] "rpm" Vector__XXX
SG_ EngSpeedLimitRequestMaximumCntns : 8|8@1+ (32,0) [0|8000] "rpm" Vector__XXX
SG_ EngTorqueLmtRequestMinimumCntns : 16|8@1+ (1,-125) [-125|125] "%" Vector__XXX
SG_ EngTorqueLmtRequestMaximumCntns : 24|8@1+ (1,-125) [-125|125] "%" Vector__XXX
SG_ MinCntnsRetarderSpeedLmtRequest : 32|8@1+ (32,0) [0|8000] "rpm" Vector__XXX
SG_ MaxCntnsRetarderSpeedLmtRequest : 40|8@1+ (32,0) [0|8000] "rpm" Vector__XXX
SG_ MinCntnsRetarderTorqueLmtRequest : 48|8@1+ (1,-125) [-125|125] "%" Vector__XXX
SG_ MaxCntnsRetarderTorqueLmtRequest : 56|8@1+ (1,-125) [-125|125] "%" Vector__XXX

BO_ 2563833598 CL: 8 Vector__XXX
SG_ IlluminationBrightnessPercent : 0|8@1+ (0.4,0) [0|100] "%" Vector__XXX
SG_ SwBcklghtIllmntnBRghtnessPrcnt : 8|8@1+ (0.4,0) [0|100] "%" Vector__XXX
SG_ SwIndiIllmntnBRghtnessPrcnt : 16|8@1+ (0.4,0) [0|100] "%" Vector__XXX

BO_ 2362572542 ASC6: 8 Vector__XXX
SG_ LevelPresetFrontAxleLeft : 0|16@1+ (0.1,-3200) [-3200|3225.5] "mm" Vector__XXX
SG_ LevelPresetFrontAxleRight : 16|16@1+ (0.1,-3200) [-3200|3225.5] "mm" Vector__XXX
SG_ LevelPresetRearAxleLeft : 32|16@1+ (0.1,-3200) [-3200|3225.5] "mm" Vector__XXX
SG_ LevelPresetRearAxleRight : 48|16@1+ (0.1,-3200) [-3200|3225.5] "mm" Vector__XXX

BO_ 2362638078 ASC2: 8 Vector__XXX
SG_ AutomaticTractionHelp : 0|2@1+ (1,0) [0|3] "" Vector__XXX
SG_ KneelingRequestLeftSide : 2|2@1+ (1,0) [0|3] "" Vector__XXX
SG_ KneelingRequestRightSide : 4|2@1+ (1,0) [0|3] "" Vector__XXX
SG_ KneelingControlModeRequest : 6|2@1+ (1,0) [0|3] "" Vector__XXX
SG_ NominalLevelRequestFrontAxle : 8|4@1+ (1,0) [0|15] "" Vector__XXX
SG_ NominalLevelRequestRearAxle : 12|4@1+ (1,0) [0|15] "" Vector__XXX
SG_ LevelControlModeRequest : 16|4@1+ (1,0) [0|15] "" Vector__XXX
SG_ LiftAxle1PositionCommand : 20|2@1+ (1,0) [0|3] "" Vector__XXX
SG_ LiftAxle2PositionCommand : 22|2@1+ (1,0) [0|3] "" Vector__XXX
SG_ DamperStiffnessRequestFrontAxle : 24|8@1+ (0.4,0) [0|100] "%" Vector__XXX
SG_ DamperStiffnessRequestRearAxle : 32|8@1+ (0.4,0) [0|100] "%" Vector__XXX
SG_ DamperStiffnessRequestLiftTagAxl : 40|8@1+ (0.4,0) [0|100] "%" Vector__XXX
SG_ KneelingCommandFrontAxle : 48|2@1+ (1,0) [0|3] "" Vector__XXX
SG_ KneelingCommandRearAxle : 50|2@1+ (1,0) [0|3] "" Vector__XXX
SG_ ProhibitAirSuspensionControl : 52|2@1+ (1,0) [0|3] "" Vector__XXX
SG_ AllowLevelControlDuringBrkngCmd : 54|2@1+ (1,0) [0|3] "" Vector__XXX
SG_ SpeedDependentLevelCtrlRequest : 56|2@1+ (1,0) [0|3] "" Vector__XXX
SG_ ProhibitAutoAirSuspensionControl : 58|2@1+ (1,0) [0|3] "" Vector__XXX
SG_ MemoryLevelRequest : 60|4@1+ (1,0) [0|15] "" Vector__XXX

BO_ 2564030206 DM19: 20 Vector__XXX
SG_ CalibrationVerificationNumber : 0|32@1+ (1,0) [0|4294967295] "" Vector__XXX
SG_ CalibrationIdentification : 39|128@0+ (1,0) [0|0] "ASCII" Vector__XXX

BO_ 2564095742 DM18: 3 Vector__XXX
SG_ SecurityEntityLength : 7|12@0+ (1,0) [0|4095] "" Vector__XXX
SG_ SecurityEntityType : 8|4@1+ (1,0) [0|15] "" Vector__XXX
SG_ DataSecurityParameter : 16|8@1+ (1,0) [0|255] "" Vector__XXX

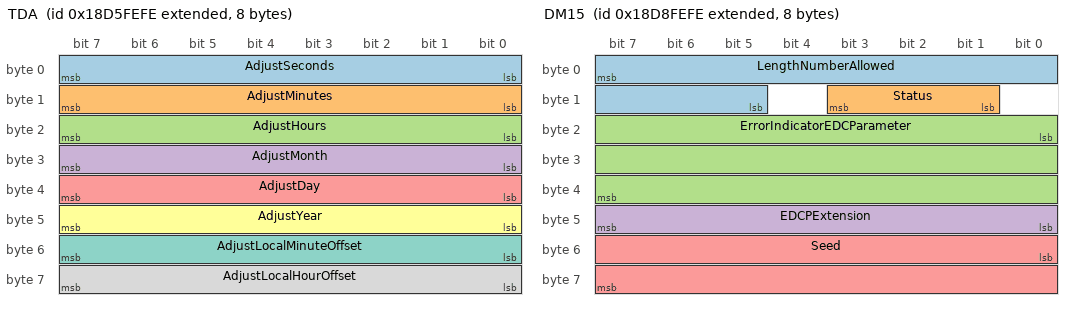
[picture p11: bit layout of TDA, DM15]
BO_ 2564161278 TDA: 8 Vector__XXX
SG_ AdjustSeconds : 0|8@1+ (0.25,0) [0|62.5] "s" Vector__XXX
SG_ AdjustMinutes : 8|8@1+ (1,0) [0|250] "min" Vector__XXX
SG_ AdjustHours : 16|8@1+ (1,0) [0|250] "h" Vector__XXX
SG_ AdjustMonth : 24|8@1+ (1,0) [0|250] "Months" Vector__XXX
SG_ AdjustDay : 32|8@1+ (0.25,0) [0|62.5] "Days" Vector__XXX
SG_ AdjustYear : 40|8@1+ (1,1985) [1985|2235] "Years" Vector__XXX
SG_ AdjustLocalMinuteOffset : 48|8@1+ (1,-125) [-125|125] "min" Vector__XXX
SG_ AdjustLocalHourOffset : 56|8@1+ (1,-125) [-125|125] "h" Vector__XXX

BO_ 2564226814 DM17: 1785 Vector__XXX

BO_ 2564292350 DM16: 1785 Vector__XXX
SG_ NoOfOccurrencesOfRawBinaryDat : 0|8@1+ (1,0) [0|255] "" Vector__XXX

BO_ 2564357886 DM15: 8 Vector__XXX
SG_ LengthNumberAllowed : 7|11@0+ (1,0) [0|2047] "" Vector__XXX
SG_ Status : 9|3@1+ (1,0) [0|7] "" Vector__XXX
SG_ ErrorIndicatorEDCParameter : 16|24@1+ (1,0) [0|16777215] "" Vector__XXX
SG_ EDCPExtension : 40|8@1+ (1,0) [0|255] "" Vector__XXX
SG_ Seed : 48|16@1+ (1,0) [0|65535] "" Vector__XXX

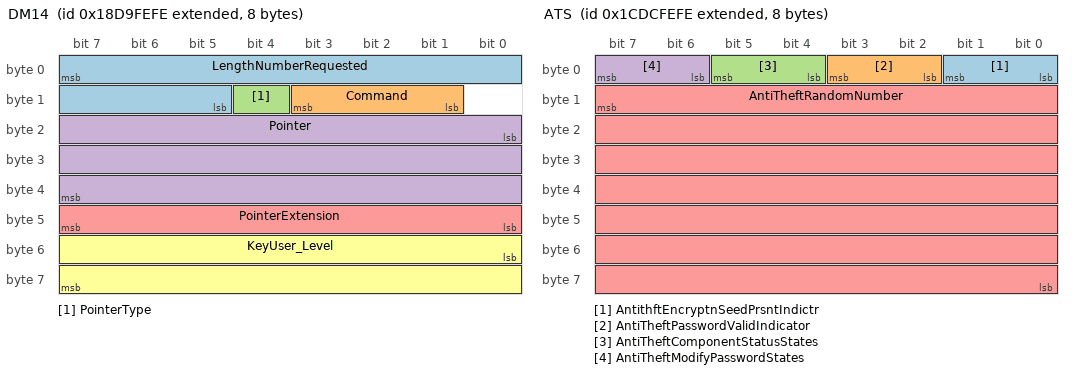
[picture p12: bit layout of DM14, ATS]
BO_ 2564423422 DM14: 8 Vector__XXX
SG_ LengthNumberRequested : 7|11@0+ (1,0) [0|2047] "" Vector__XXX
SG_ Command : 9|3@1+ (1,0) [0|7] "" Vector__XXX
SG_ PointerType : 12|1@1+ (1,0) [0|1] "" Vector__XXX
SG_ Pointer : 16|24@1+ (1,0) [0|16777215] "" Vector__XXX
SG_ PointerExtension : 40|8@1+ (1,0) [0|255] "" Vector__XXX
SG_ KeyUser_Level : 48|16@1+ (1,0) [0|65535] "" Vector__XXX

BO_ 2564488958 KWP2: 0 Vector__XXX

BO_ 2564554494 KWP1: 0 Vector__XXX

BO_ 2631728894 ATS: 8 Vector__XXX
SG_ AntithftEncryptnSeedPrsntIndictr : 0|2@1+ (1,0) [0|3] "" Vector__XXX
SG_ AntiTheftPasswordValidIndicator : 2|2@1+ (1,0) [0|3] "" Vector__XXX
SG_ AntiTheftComponentStatusStates : 4|2@1+ (1,0) [0|3] "" Vector__XXX
SG_ AntiTheftModifyPasswordStates : 6|2@1+ (1,0) [0|3] "" Vector__XXX
SG_ AntiTheftRandomNumber : 15|56@0+ (1,0) [0|0] "ASCII" Vector__XXX

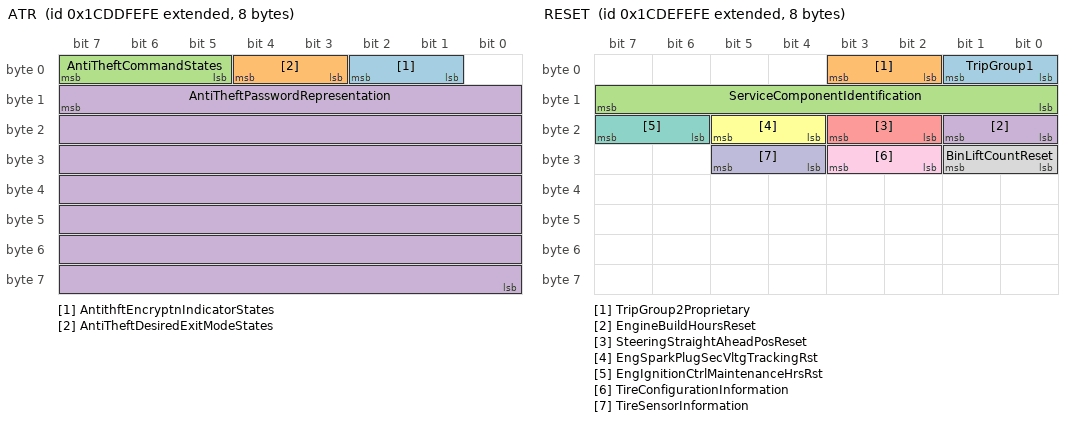
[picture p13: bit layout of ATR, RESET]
BO_ 2631794430 ATR: 8 Vector__XXX
SG_ AntithftEncryptnIndicatorStates : 1|2@1+ (1,0) [0|3] "" Vector__XXX
SG_ AntiTheftDesiredExitModeStates : 3|2@1+ (1,0) [0|3] "" Vector__XXX
SG_ AntiTheftCommandStates : 5|3@1+ (1,0) [0|7] "" Vector__XXX
SG_ AntiTheftPasswordRepresentation : 15|56@0+ (1,0) [0|0] "ASCII" Vector__XXX

BO_ 2631859966 RESET: 8 Vector__XXX
SG_ TripGroup1 : 0|2@1+ (1,0) [0|3] "" Vector__XXX
SG_ TripGroup2Proprietary : 2|2@1+ (1,0) [0|3] "" Vector__XXX
SG_ ServiceComponentIdentification : 8|8@1+ (1,0) [0|250] "" Vector__XXX
SG_ EngineBuildHoursReset : 16|2@1+ (1,0) [0|3] "" Vector__XXX
SG_ SteeringStraightAheadPosReset : 18|2@1+ (1,0) [0|3] "" Vector__XXX
SG_ EngSparkPlugSecVltgTrackingRst : 20|2@1+ (1,0) [0|3] "" Vector__XXX
SG_ EngIgnitionCtrlMaintenanceHrsRst : 22|2@1+ (1,0) [0|3] "" Vector__XXX
SG_ BinLiftCountReset : 24|2@1+ (1,0) [0|3] "" Vector__XXX
SG_ TireConfigurationInformation : 26|2@1+ (1,0) [0|3] "" Vector__XXX
SG_ TireSensorInformation : 28|2@1+ (1,0) [0|3] "" Vector__XXX

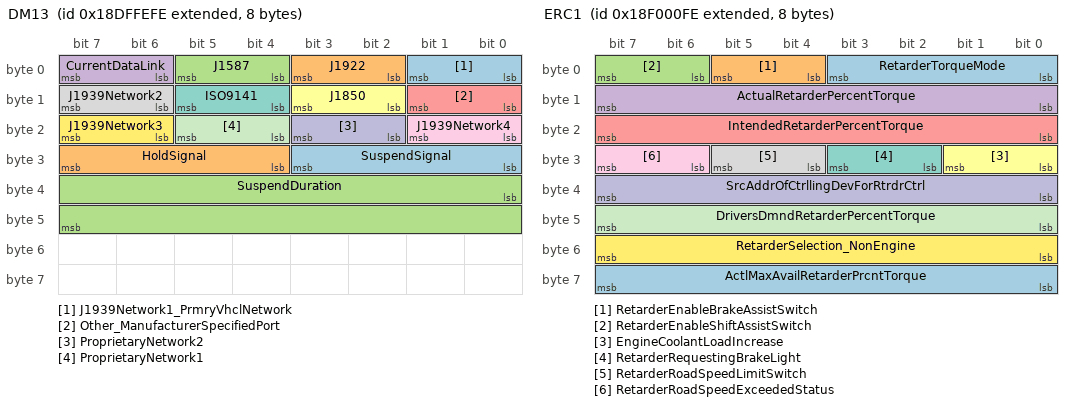
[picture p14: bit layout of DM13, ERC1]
BO_ 2564816638 DM13: 8 Vector__XXX
SG_ J1939Network1_PrmryVhclNetwork : 0|2@1+ (1,0) [0|3] "" Vector__XXX
SG_ J1922 : 2|2@1+ (1,0) [0|3] "" Vector__XXX
SG_ J1587 : 4|2@1+ (1,0) [0|3] "" Vector__XXX
SG_ CurrentDataLink : 6|2@1+ (1,0) [0|3] "" Vector__XXX
SG_ Other_ManufacturerSpecifiedPort : 8|2@1+ (1,0) [0|3] "" Vector__XXX
SG_ J1850 : 10|2@1+ (1,0) [0|3] "" Vector__XXX
SG_ ISO9141 : 12|2@1+ (1,0) [0|3] "" Vector__XXX
SG_ J1939Network2 : 14|2@1+ (1,0) [0|3] "" Vector__XXX
SG_ J1939Network4 : 16|2@1+ (1,0) [0|3] "" Vector__XXX
SG_ ProprietaryNetwork2 : 18|2@1+ (1,0) [0|3] "" Vector__XXX
SG_ ProprietaryNetwork1 : 20|2@1+ (1,0) [0|3] "" Vector__XXX
SG_ J1939Network3 : 22|2@1+ (1,0) [0|3] "" Vector__XXX
SG_ SuspendSignal : 24|4@1+ (1,0) [0|15] "" Vector__XXX
SG_ HoldSignal : 28|4@1+ (1,0) [0|15] "" Vector__XXX
SG_ SuspendDuration : 32|16@1+ (1,0) [0|64255] "s" Vector__XXX

BO_ 2564882174 CM1: 8 Vector__XXX
SG_ EngineFan1RequestedPercentSpeed : 0|8@1+ (0.4,0) [0|100] "%" Vector__XXX
SG_ CabInteriorTemperatureCommand : 8|16@1+ (0.03125,-273) [-273|1734.96875] "deg C" Vector__XXX
SG_ AuxHeaterCoolantPumpRequest : 24|2@1+ (1,0) [0|3] "" Vector__XXX
SG_ BatteryMainSwitchHoldRequest : 26|2@1+ (1,0) [0|3] "" Vector__XXX
SG_ OperatorSeatDirectionSwitch : 28|2@1+ (1,0) [0|3] "" Vector__XXX
SG_ SeatBeltSwitch : 30|2@1+ (1,0) [0|3] "" Vector__XXX
SG_ ParkBrakeCommand : 32|2@1+ (1,0) [0|3] "" Vector__XXX
SG_ VehicleLmtngSpdGvrnrDecrementSw : 34|2@1+ (1,0) [0|3] "" Vector__XXX
SG_ VehicleLmtngSpdGvrnrIncrementSw : 36|2@1+ (1,0) [0|3] "" Vector__XXX
SG_ VehicleLmtngSpeedGvrnrEnblSwitch : 38|2@1+ (1,0) [0|3] "" Vector__XXX
SG_ AftrtrtmntRegenInhbtSwitch : 40|2@1+ (1,0) [0|3] "" Vector__XXX
SG_ AftrtrtmntRegenForceSwitch : 42|2@1+ (1,0) [0|3] "" Vector__XXX
SG_ AutoGearShiftingEnableSwitch : 44|2@1+ (1,0) [0|3] "" Vector__XXX
SG_ EngineAutomaticStartEnableSwitch : 46|2@1+ (1,0) [0|3] "" Vector__XXX
SG_ AuxiliaryHeaterModeRequest : 48|4@1+ (1,0) [0|15] "" Vector__XXX
SG_ RequestEngineZoneHeating : 52|2@1+ (1,0) [0|3] "" Vector__XXX
SG_ RequestCabZoneHeating : 54|2@1+ (1,0) [0|3] "" Vector__XXX
SG_ SelectedMaximumVehicleSpeedLimit : 56|8@1+ (1,0) [0|250] "" Vector__XXX

BO_ 2565078782 DM07: 8 Vector__XXX
SG_ TestIdentifier : 0|8@1+ (1,0) [0|255] "" Vector__XXX
SG_ SPNIdentifyingComponentSystem : 15|19@0+ (1,0) [0|524287] "" Vector__XXX
SG_ FMIIdentifyingComponentSyspcTest : 24|5@1+ (1,0) [0|31] "" Vector__XXX

BO_ 2565406462 ACKM: 8 Vector__XXX
SG_ ACKM_Mux M : 0|8@1+ (1,0) [0|0] "" Vector__XXX
SG_ GroupFunctionValue0 m0 : 8|8@1+ (1,0) [0|255] "" Vector__XXX
SG_ ParameterGroupNumber0 m0 : 40|24@1+ (1,0) [0|16777215] "" Vector__XXX
SG_ GroupFunctionValue1 m1 : 8|8@1+ (1,0) [0|255] "" Vector__XXX
SG_ ParameterGroupNumber1 m1 : 40|24@1+ (1,0) [0|16777215] "" Vector__XXX
SG_ GroupFunctionValue2 m2 : 8|8@1+ (1,0) [0|255] "" Vector__XXX
SG_ ParameterGroupNumber2 m2 : 40|24@1+ (1,0) [0|16777215] "" Vector__XXX
SG_ GroupFunctionValue3 m3 : 8|8@1+ (1,0) [0|255] "" Vector__XXX
SG_ ParameterGroupNumber3 m3 : 40|24@1+ (1,0) [0|16777215] "" Vector__XXX

BO_ 2565537534 RQST: 3 Vector__XXX
SG_ ParameterGroupNumber : 0|24@1+ (1,0) [0|16777215] "" Vector__XXX

BO_ 2565603070 TPDT: 8 Vector__XXX
SG_ SequenceNumber : 0|8@1+ (1,0) [0|255] "" Vector__XXX
SG_ PacketizedData : 8|56@1+ (1,0) [0|0] "" Vector__XXX

BO_ 2565668606 TPCM: 8 Vector__XXX
SG_ TPCM_Mux M : 0|8@1+ (1,0) [0|0] "" Vector__XXX
SG_ TotalMessageSize16 m16 : 8|16@1+ (1,0) [0|64255] "" Vector__XXX
SG_ TotalNumberOfPackets16 m16 : 24|8@1+ (1,0) [0|255] "" Vector__XXX
SG_ MaximumNumberOfPackets m16 : 32|8@1+ (1,0) [0|255] "" Vector__XXX
SG_ PGNOfThePacketedMessage16 m16 : 40|24@1+ (1,0) [0|16777215] "" Vector__XXX
SG_ NumberOfPacketsThatCanBeSent m17 : 8|8@1+ (1,0) [0|255] "" Vector__XXX
SG_ NextPacketNumberToBeSent m17 : 16|8@1+ (1,0) [0|255] "" Vector__XXX
SG_ PGNOfThePacketedMessage17 m17 : 40|24@1+ (1,0) [0|16777215] "" Vector__XXX
SG_ TotalMessageSize19 m19 : 8|16@1+ (1,0) [0|64255] "" Vector__XXX
SG_ TotalNumberOfPackets19 m19 : 24|8@1+ (1,0) [0|255] "" Vector__XXX
SG_ PGNOfThePacketedMessage19 m19 : 40|24@1+ (1,0) [0|16777215] "" Vector__XXX
SG_ TotalMessageSize32 m32 : 8|16@1+ (1,0) [0|64255] "" Vector__XXX
SG_ TotalNumberOfPackets32 m32 : 24|8@1+ (1,0) [0|255] "" Vector__XXX
SG_ PGNOfThePacketedMessage32 m32 : 40|24@1+ (1,0) [0|16777215] "" Vector__XXX
SG_ ConnectionAbortReason m255 : 8|8@1+ (1,0) [0|255] "" Vector__XXX
SG_ ParameterGrpNoOfPacketedMessage m255 : 40|24@1+ (1,0) [0|16777215] "" Vector__XXX

BO_ 2565734142 Nxx: 0 Vector__XXX

BO_ 2565799678 ACM: 8 Vector__XXX
SG_ NAMEOfControllerApplication : 0|64@1+ (1,0) [0|1.84467440737096E019] "" Vector__XXX

BO_ 2565865214 PropA: 1785 Vector__XXX

BO_ 2565865726 ERC1: 8 Vector__XXX
SG_ RetarderTorqueMode : 0|4@1+ (1,0) [0|15] "" Vector__XXX
SG_ RetarderEnableBrakeAssistSwitch : 4|2@1+ (1,0) [0|3] "" Vector__XXX
SG_ RetarderEnableShiftAssistSwitch : 6|2@1+ (1,0) [0|3] "" Vector__XXX
SG_ ActualRetarderPercentTorque : 8|8@1+ (1,-125) [-125|125] "%" Vector__XXX
SG_ IntendedRetarderPercentTorque : 16|8@1+ (1,-125) [-125|125] "%" Vector__XXX
SG_ EngineCoolantLoadIncrease : 24|2@1+ (1,0) [0|3] "" Vector__XXX
SG_ RetarderRequestingBrakeLight : 26|2@1+ (1,0) [0|3] "" Vector__XXX
SG_ RetarderRoadSpeedLimitSwitch : 28|2@1+ (1,0) [0|3] "" Vector__XXX
SG_ RetarderRoadSpeedExceededStatus : 30|2@1+ (1,0) [0|3] "" Vector__XXX
SG_ SrcAddrOfCtrllingDevForRtrdrCtrl : 32|8@1+ (1,0) [0|255] "" Vector__XXX
SG_ DriversDmndRetarderPercentTorque : 40|8@1+ (1,-125) [-125|125] "%" Vector__XXX
SG_ RetarderSelection_NonEngine : 48|8@1+ (0.4,0) [0|100] "%" Vector__XXX
SG_ ActlMaxAvailRetarderPrcntTorque : 56|8@1+ (1,-125) [-125|125] "%" Vector__XXX

BO_ 2565865982 EBC1: 8 Vector__XXX
SG_ ASREngineControlActive : 0|2@1+ (1,0) [0|3] "" Vector__XXX
SG_ ASRBrakeControlActive : 2|2@1+ (1,0) [0|3] "" Vector__XXX
SG_ AntiLockBrakingActive : 4|2@1+ (1,0) [0|3] "" Vector__XXX
SG_ EBSBrakeSwitch : 6|2@1+ (1,0) [0|3] "" Vector__XXX
SG_ BrakePedalPosition : 8|8@1+ (0.4,0) [0|100] "%" Vector__XXX
SG_ ABSOffRoadSwitch : 16|2@1+ (1,0) [0|3] "" Vector__XXX
SG_ ASROffRoadSwitch : 18|2@1+ (1,0) [0|3] "" Vector__XXX
SG_ ASRHillHolderSwitch : 20|2@1+ (1,0) [0|3] "" Vector__XXX
SG_ TractionControlOverrideSwitch : 22|2@1+ (1,0) [0|3] "" Vector__XXX
SG_ AcceleratorInterlockSwitch : 24|2@1+ (1,0) [0|3] "" Vector__XXX
SG_ EngineDerateSwitch : 26|2@1+ (1,0) [0|3] "" Vector__XXX
SG_ EngineAuxiliaryShutdownSwitch : 28|2@1+ (1,0) [0|3] "" Vector__XXX
SG_ RemoteAcceleratorEnableSwitch : 30|2@1+ (1,0) [0|3] "" Vector__XXX
SG_ EngineRetarderSelection : 32|8@1+ (0.4,0) [0|100] "%" Vector__XXX
SG_ ABSFullyOperational : 40|2@1+ (1,0) [0|3] "" Vector__XXX
SG_ EBSRedWarningSignal : 42|2@1+ (1,0) [0|3] "" Vector__XXX
SG_ ABSEBSAmberWarningSignal : 44|2@1+ (1,0) [0|3] "" Vector__XXX
SG_ ATCASRInformationSignal : 46|2@1+ (1,0) [0|3] "" Vector__XXX
SG_ SrcAddrOfCtrllingDevForBrkCtrl : 48|8@1+ (1,0) [0|255] "" Vector__XXX
SG_ RailroadModeSwitch : 56|2@1+ (1,0) [0|3] "" Vector__XXX
SG_ HaltBrakeSwitch : 58|2@1+ (1,0) [0|3] "" Vector__XXX
SG_ TrailerABSStatus : 60|2@1+ (1,0) [0|3] "" Vector__XXX
SG_ TractorMntdTrailerABSWarningSig : 62|2@1+ (1,0) [0|3] "" Vector__XXX

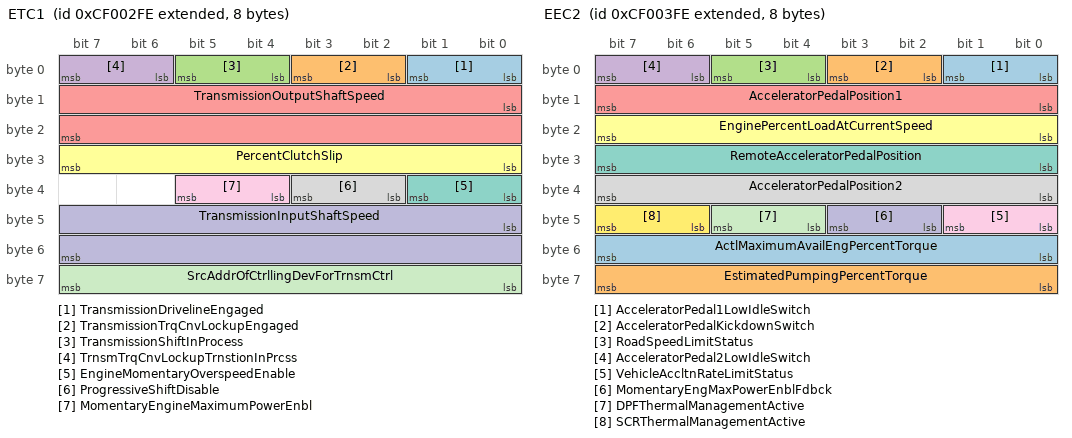
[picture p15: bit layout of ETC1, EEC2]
BO_ 2364539646 ETC1: 8 Vector__XXX
SG_ TransmissionDrivelineEngaged : 0|2@1+ (1,0) [0|3] "" Vector__XXX
SG_ TransmissionTrqCnvLockupEngaged : 2|2@1+ (1,0) [0|3] "" Vector__XXX
SG_ TransmissionShiftInProcess : 4|2@1+ (1,0) [0|3] "" Vector__XXX
SG_ TrnsmTrqCnvLockupTrnstionInPrcss : 6|2@1+ (1,0) [0|3] "" Vector__XXX
SG_ TransmissionOutputShaftSpeed : 8|16@1+ (0.125,0) [0|8031.875] "rpm" Vector__XXX
SG_ PercentClutchSlip : 24|8@1+ (0.4,0) [0|100] "%" Vector__XXX
SG_ EngineMomentaryOverspeedEnable : 32|2@1+ (1,0) [0|3] "" Vector__XXX
SG_ ProgressiveShiftDisable : 34|2@1+ (1,0) [0|3] "" Vector__XXX
SG_ MomentaryEngineMaximumPowerEnbl : 36|2@1+ (1,0) [0|3] "" Vector__XXX
SG_ TransmissionInputShaftSpeed : 40|16@1+ (0.125,0) [0|8031.875] "rpm" Vector__XXX
SG_ SrcAddrOfCtrllingDevForTrnsmCtrl : 56|8@1+ (1,0) [0|255] "" Vector__XXX

BO_ 2364539902 EEC2: 8 Vector__XXX
SG_ AcceleratorPedal1LowIdleSwitch : 0|2@1+ (1,0) [0|3] "" Vector__XXX
SG_ AcceleratorPedalKickdownSwitch : 2|2@1+ (1,0) [0|3] "" Vector__XXX
SG_ RoadSpeedLimitStatus : 4|2@1+ (1,0) [0|3] "" Vector__XXX
SG_ AcceleratorPedal2LowIdleSwitch : 6|2@1+ (1,0) [0|3] "" Vector__XXX
SG_ AcceleratorPedalPosition1 : 8|8@1+ (0.4,0) [0|100] "%" Vector__XXX
SG_ EnginePercentLoadAtCurrentSpeed : 16|8@1+ (1,0) [0|250] "%" Vector__XXX
SG_ RemoteAcceleratorPedalPosition : 24|8@1+ (0.4,0) [0|100] "%" Vector__XXX
SG_ AcceleratorPedalPosition2 : 32|8@1+ (0.4,0) [0|100] "%" Vector__XXX
SG_ VehicleAccltnRateLimitStatus : 40|2@1+ (1,0) [0|3] "" Vector__XXX
SG_ MomentaryEngMaxPowerEnblFdbck : 42|2@1+ (1,0) [0|3] "" Vector__XXX
SG_ DPFThermalManagementActive : 44|2@1+ (1,0) [0|3] "" Vector__XXX
SG_ SCRThermalManagementActive : 46|2@1+ (1,0) [0|3] "" Vector__XXX
SG_ ActlMaximumAvailEngPercentTorque : 48|8@1+ (0.4,0) [0|100] "%" Vector__XXX
SG_ EstimatedPumpingPercentTorque : 56|8@1+ (1,-125) [-125|125] "%" Vector__XXX

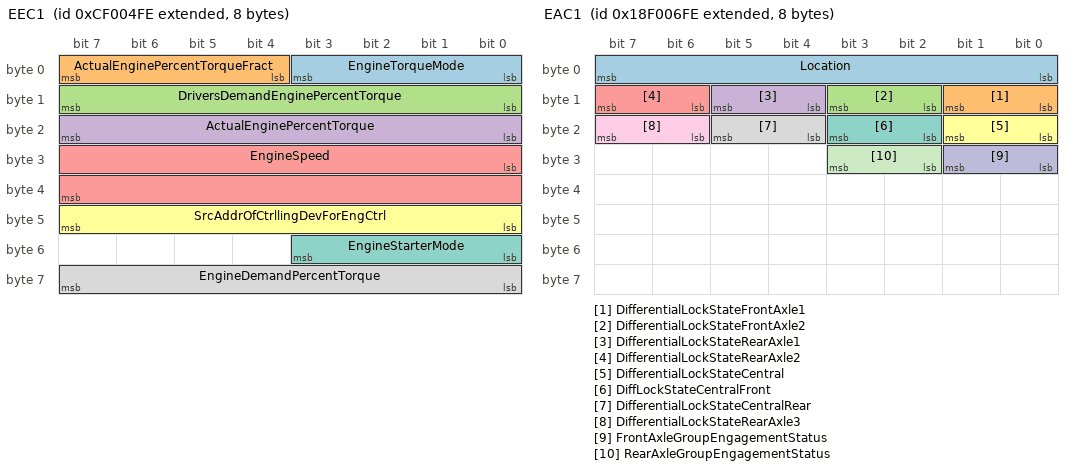
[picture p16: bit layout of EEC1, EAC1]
BO_ 2364540158 EEC1: 8 Vector__XXX
SG_ EngineTorqueMode : 0|4@1+ (1,0) [0|15] "" Vector__XXX
SG_ ActualEnginePercentTorqueFract : 4|4@1+ (0.125,0) [0|0.875] "%" Vector__XXX
SG_ DriversDemandEnginePercentTorque : 8|8@1+ (1,-125) [-125|125] "%" Vector__XXX
SG_ ActualEnginePercentTorque : 16|8@1+ (1,-125) [-125|125] "%" Vector__XXX
SG_ EngineSpeed : 24|16@1+ (0.125,0) [0|8031.875] "rpm" Vector__XXX
SG_ SrcAddrOfCtrllingDevForEngCtrl : 40|8@1+ (1,0) [0|255] "" Vector__XXX
SG_ EngineStarterMode : 48|4@1+ (1,0) [0|15] "" Vector__XXX
SG_ EngineDemandPercentTorque : 56|8@1+ (1,-125) [-125|125] "%" Vector__XXX

BO_ 2565867006 ETC2: 8 Vector__XXX
SG_ TransmissionSelectedGear : 0|8@1+ (1,-125) [-125|125] "" Vector__XXX
SG_ TransmissionActualGearRatio : 8|16@1+ (0.001,0) [0|64.255] "" Vector__XXX
SG_ TransmissionCurrentGear : 24|8@1+ (1,-125) [-125|125] "" Vector__XXX
SG_ TransmissionRequestedRange : 39|16@0+ (1,0) [0|0] "ASCII" Vector__XXX
SG_ TransmissionCurrentRange : 55|16@0+ (1,0) [0|0] "ASCII" Vector__XXX

BO_ 2565867262 EAC1: 8 Vector__XXX
SG_ Location : 0|8@1+ (1,0) [0|255] "" Vector__XXX
SG_ DifferentialLockStateFrontAxle1 : 8|2@1+ (1,0) [0|3] "" Vector__XXX
SG_ DifferentialLockStateFrontAxle2 : 10|2@1+ (1,0) [0|3] "" Vector__XXX
SG_ DifferentialLockStateRearAxle1 : 12|2@1+ (1,0) [0|3] "" Vector__XXX
SG_ DifferentialLockStateRearAxle2 : 14|2@1+ (1,0) [0|3] "" Vector__XXX
SG_ DifferentialLockStateCentral : 16|2@1+ (1,0) [0|3] "" Vector__XXX
SG_ DiffLockStateCentralFront : 18|2@1+ (1,0) [0|3] "" Vector__XXX
SG_ DifferentialLockStateCentralRear : 20|2@1+ (1,0) [0|3] "" Vector__XXX
SG_ DifferentialLockStateRearAxle3 : 22|2@1+ (1,0) [0|3] "" Vector__XXX
SG_ FrontAxleGroupEngagementStatus : 24|2@1+ (1,0) [0|3] "" Vector__XXX
SG_ RearAxleGroupEngagementStatus : 26|2@1+ (1,0) [0|3] "" Vector__XXX

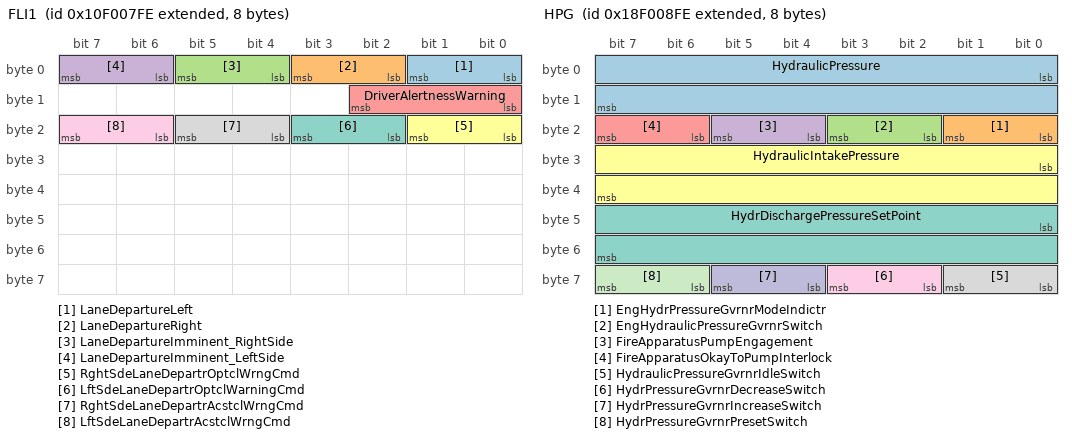
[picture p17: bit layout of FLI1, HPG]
BO_ 2431649790 FLI1: 8 Vector__XXX
SG_ LaneDepartureLeft : 0|2@1+ (1,0) [0|3] "" Vector__XXX
SG_ LaneDepartureRight : 2|2@1+ (1,0) [0|3] "" Vector__XXX
SG_ LaneDepartureImminent_RightSide : 4|2@1+ (1,0) [0|3] "" Vector__XXX
SG_ LaneDepartureImminent_LeftSide : 6|2@1+ (1,0) [0|3] "" Vector__XXX
SG_ DriverAlertnessWarning : 8|3@1+ (1,0) [0|7] "" Vector__XXX
SG_ RghtSdeLaneDepartrOptclWrngCmd : 16|2@1+ (1,0) [0|3] "" Vector__XXX
SG_ LftSdeLaneDepartrOptclWarningCmd : 18|2@1+ (1,0) [0|3] "" Vector__XXX
SG_ RghtSdeLaneDepartrAcstclWrngCmd : 20|2@1+ (1,0) [0|3] "" Vector__XXX
SG_ LftSdeLaneDepartrAcstclWrngCmd : 22|2@1+ (1,0) [0|3] "" Vector__XXX

BO_ 2565867774 HPG: 8 Vector__XXX
SG_ HydraulicPressure : 0|16@1+ (2,0) [0|128510] "kPa" Vector__XXX
SG_ EngHydrPressureGvrnrModeIndictr : 16|2@1+ (1,0) [0|3] "" Vector__XXX
SG_ EngHydraulicPressureGvrnrSwitch : 18|2@1+ (1,0) [0|3] "" Vector__XXX
SG_ FireApparatusPumpEngagement : 20|2@1+ (1,0) [0|3] "" Vector__XXX
SG_ FireApparatusOkayToPumpInterlock : 22|2@1+ (1,0) [0|3] "" Vector__XXX
SG_ HydraulicIntakePressure : 24|16@1+ (0.0001220703125,-1) [-1|6.84362793] "MPa" Vector__XXX
SG_ HydrDischargePressureSetPoint : 40|16@1+ (2,0) [0|128510] "kPa" Vector__XXX
SG_ HydraulicPressureGvrnrIdleSwitch : 56|2@1+ (1,0) [0|3] "" Vector__XXX
SG_ HydrPressureGvrnrDecreaseSwitch : 58|2@1+ (1,0) [0|3] "" Vector__XXX
SG_ HydrPressureGvrnrIncreaseSwitch : 60|2@1+ (1,0) [0|3] "" Vector__XXX
SG_ HydrPressureGvrnrPresetSwitch : 62|2@1+ (1,0) [0|3] "" Vector__XXX

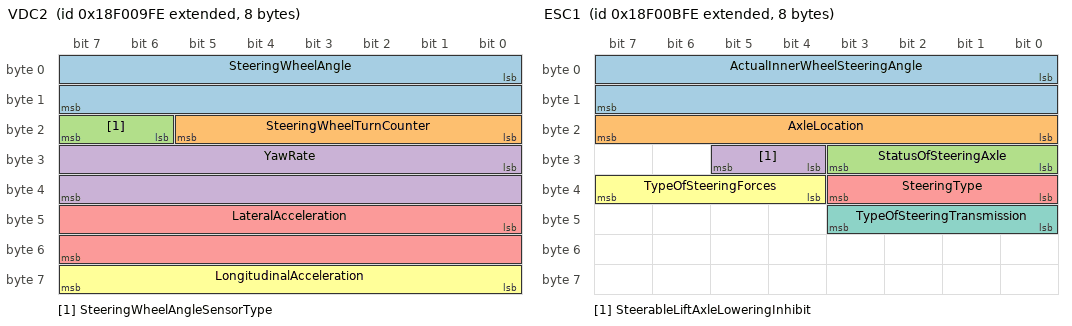
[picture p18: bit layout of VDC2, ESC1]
BO_ 2565868030 VDC2: 8 Vector__XXX
SG_ SteeringWheelAngle : 0|16@1+ (0.0009765625,-31.374) [-31.374|31.374] "rad" Vector__XXX
SG_ SteeringWheelTurnCounter : 16|6@1+ (1,-32) [-32|29] "" Vector__XXX
SG_ SteeringWheelAngleSensorType : 22|2@1+ (1,0) [0|3] "" Vector__XXX
SG_ YawRate : 24|16@1+ (0.0001220703125,-3.92) [-3.92|3.92] "rad/s" Vector__XXX
SG_ LateralAcceleration : 40|16@1+ (0.00048828125,-15.687) [-15.687|15.687] "m/s^2" Vector__XXX
SG_ LongitudinalAcceleration : 56|8@1+ (0.1,-12.5) [-12.5|12.5] "m/s^2" Vector__XXX

BO_ 2364541694 EGF1: 8 Vector__XXX
SG_ EngExhstGasRecirc1MassFlwRate : 0|16@1+ (0.05,0) [0|3212.75] "kg/h" Vector__XXX
SG_ EngineIntakeAirMassFlowRate : 16|16@1+ (0.05,0) [0|3212.75] "kg/h" Vector__XXX
SG_ EngExhstGasRecirc2MassFlwRate : 32|16@1+ (0.05,0) [0|3212.75] "kg/h" Vector__XXX

BO_ 2565868542 ESC1: 8 Vector__XXX
SG_ ActualInnerWheelSteeringAngle : 0|16@1+ (0.00390625,-125) [-125|125] "deg" Vector__XXX
SG_ AxleLocation : 16|8@1+ (1,0) [0|255] "" Vector__XXX
SG_ StatusOfSteeringAxle : 24|4@1+ (1,0) [0|15] "" Vector__XXX
SG_ SteerableLiftAxleLoweringInhibit : 28|2@1+ (1,0) [0|3] "" Vector__XXX
SG_ SteeringType : 32|4@1+ (1,0) [0|15] "" Vector__XXX
SG_ TypeOfSteeringForces : 36|4@1+ (1,0) [0|15] "" Vector__XXX
SG_ TypeOfSteeringTransmission : 40|4@1+ (1,0) [0|15] "" Vector__XXX

BO_ 2364542206 ETC8: 8 Vector__XXX
SG_ TransmissionTorqueConverterRatio : 0|16@1+ (0.001,0) [0|64.255] "" Vector__XXX
SG_ TransmissionCltchCnvInputSpeed : 16|16@1+ (0.125,0) [0|8031.875] "rpm" Vector__XXX

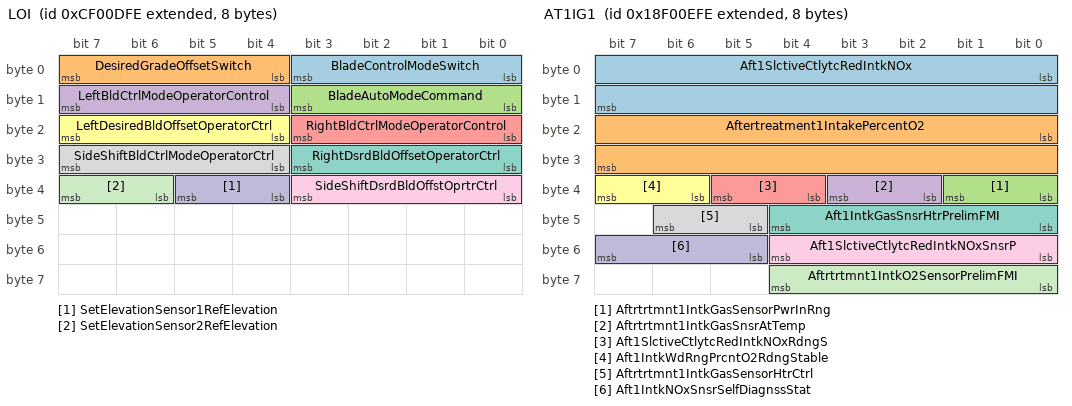
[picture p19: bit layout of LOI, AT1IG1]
BO_ 2364542462 LOI: 8 Vector__XXX
SG_ BladeControlModeSwitch : 0|4@1+ (1,0) [0|15] "" Vector__XXX
SG_ DesiredGradeOffsetSwitch : 4|4@1+ (1,0) [0|15] "" Vector__XXX
SG_ BladeAutoModeCommand : 8|4@1+ (1,0) [0|15] "" Vector__XXX
SG_ LeftBldCtrlModeOperatorControl : 12|4@1+ (1,0) [0|15] "" Vector__XXX
SG_ RightBldCtrlModeOperatorControl : 16|4@1+ (1,0) [0|15] "" Vector__XXX
SG_ LeftDesiredBldOffsetOperatorCtrl : 20|4@1+ (1,0) [0|15] "" Vector__XXX
SG_ RightDsrdBldOffsetOperatorCtrl : 24|4@1+ (1,0) [0|15] "" Vector__XXX
SG_ SideShiftBldCtrlModeOperatorCtrl : 28|4@1+ (1,0) [0|15] "" Vector__XXX
SG_ SideShiftDsrdBldOffstOprtrCtrl : 32|4@1+ (1,0) [0|15] "" Vector__XXX
SG_ SetElevationSensor1RefElevation : 36|2@1+ (1,0) [0|3] "" Vector__XXX
SG_ SetElevationSensor2RefElevation : 38|2@1+ (1,0) [0|3] "" Vector__XXX

BO_ 2565869310 AT1IG1: 8 Vector__XXX
SG_ Aft1SlctiveCtlytcRedIntkNOx : 0|16@1+ (0.05,-200) [-200|3012.75] "ppm" Vector__XXX
SG_ Aftertreatment1IntakePercentO2 : 16|16@1+ (0.000514,-12) [-12|21.02707] "%" Vector__XXX
SG_ Aftrtrtmnt1IntkGasSensorPwrInRng : 32|2@1+ (1,0) [0|3] "" Vector__XXX
SG_ Aftrtrtmnt1IntkGasSnsrAtTemp : 34|2@1+ (1,0) [0|3] "" Vector__XXX
SG_ Aft1SlctiveCtlytcRedIntkNOxRdngS : 36|2@1+ (1,0) [0|3] "" Vector__XXX
SG_ Aft1IntkWdRngPrcntO2RdngStable : 38|2@1+ (1,0) [0|3] "" Vector__XXX
SG_ Aft1IntkGasSnsrHtrPrelimFMI : 40|5@1+ (1,0) [0|31] "" Vector__XXX
SG_ Aftrtrtmnt1IntkGasSensorHtrCtrl : 45|2@1+ (1,0) [0|3] "" Vector__XXX
SG_ Aft1SlctiveCtlytcRedIntkNOxSnsrP : 48|5@1+ (1,0) [0|31] "" Vector__XXX
SG_ Aft1IntkNOxSnsrSelfDiagnssStat : 53|3@1+ (1,0) [0|7] "" Vector__XXX
SG_ Aftrtrtmnt1IntkO2SensorPrelimFMI : 56|5@1+ (1,0) [0|31] "" Vector__XXX

CM_ BO_ 2348875518 "Torque/Speed Control 1";
CM_ BO_ 2348941054 "Transmission Control 1";
CM_ BO_ 2349137662 "External Brake Request";
CM_ BO_ 2550660862 "General Purpose Valve Pressure";
CM_ BO_ 2349399806 "Auxiliary Input/Output Status 5";
CM_ BO_ 2349465342 "Static Roll Angle Sensor Information";
CM_ BO_ 2349530878 "Cruise Control / Vehicle Speed 2";
CM_ BO_ 2349596414 "Advanced Emergency Braking System 2";
CM_ BO_ 2550988542 "Electronic Engine Controller 16";
CM_ BO_ 2349727486 "Transmission Control 2";
CM_ BO_ 2350644990 "High Voltage Energy Storage 1 Control 1";
CM_ BO_ 2350710526 "Transmission Control 3";
CM_ BO_ 2350776062 "Engine Ignition Controller";
CM_ BO_ 2350841598 "Alternator Control";
CM_ BO_ 2557345534 "Well Stimulation Pump System Configuration Command";
CM_ BO_ 2624519934 "Configurable Receive SPNs Command";
CM_ BO_ 2624716542 "Configurable Transmit PGNs Command";
CM_ BO_ 2557673214 "Oil Debris Monitor Configuration Command";
CM_ BO_ 2557738750 "Electrified Accessory Propulsion Motor Coolant Fan 3 Command";
CM_ BO_ 2557804286 "Electrified Accessory Propulsion Motor Coolant Fan 2 Command";
CM_ BO_ 2557869822 "Electrified Accessory Propulsion Motor Coolant Fan 1 Command";
CM_ BO_ 2557935358 "Electrified Accessory Power Electronics Coolant Fan 3 Command";
CM_ BO_ 2558000894 "Electrified Accessory Power Electronics Coolant Fan 2 Command";
CM_ BO_ 2558066430 "Electrified Accessory Power Electronics Coolant Fan 1 Command";
CM_ BO_ 2558131966 "Electrified Accessory Propulsion Motor Oil Pump Command";
CM_ BO_ 2558197502 "Electrified Accessory Propulsion Motor Coolant Pump Command";
CM_ BO_ 2558263038 "Electrified Accessory Power Electronics Coolant Pump Command";
CM_ BO_ 2558394110 "Electrified Accessory Motor Command";
CM_ BO_ 2558459646 "Engine Speed Ramp Rate Boundary Request";
CM_ BO_ 2558525182 "Tire Sensor Identification Command";
CM_ BO_ 2558590718 "Hybrid System Control 1";
CM_ BO_ 2558656254 "Aftertreatment System Control";
CM_ BO_ 2558721790 "Tire Configuration Command Information";
CM_ BO_ 2558787326 "Payload Calibration Information Command";
CM_ BO_ 2558852862 "Aftertreatment 1 Particulate Sensor Control";
CM_ BO_ 2558918398 "Cab Message 2";
CM_ BO_ 2558983934 "Switched Power Outputs Command";
CM_ BO_ 2559049470 "Engine State Requests";
CM_ BO_ 2559115006 "Radio Beacon Request";
CM_ BO_ 2559311614 "CCP Data Transmission Object";
CM_ BO_ 2559377150 "CCP Command Receive Object";
CM_ BO_ 2559573758 "Engine Configuration Commands";
CM_ BO_ 2559639294 "Supplemental Fan Command";
CM_ BO_ 2559704830 "Vehicle/Chassis Lubrication System 1";
CM_ BO_ 2559770366 "Aftertreatment 1 Hydrocarbon Doser Information 1";
CM_ BO_ 2559835902 "NAME Management Message";
CM_ BO_ 2559901438 "Aftertreatment 1 Diesel Particulate Filter Soot Sensor Calibration";
CM_ BO_ 2559966974 "Aftertreatment 2 Diesel Particulate Filter Soot Sensor Calibration";
CM_ BO_ 2560032510 "Low Voltage Disconnect Set Operating Mode";
CM_ BO_ 2560098046 "Noise Control Status";
CM_ BO_ 2560163582 "Noise Control 1";
CM_ BO_ 2358902526 "Joystick Lamp Command Message";
CM_ BO_ 2560360190 "Proprietary Method Identification";
CM_ BO_ 2560425726 "Auxiliary Input/Output Status 7";
CM_ BO_ 2560491262 "Auxiliary Input/Output Status 6";
CM_ BO_ 2560556798 "DTC Counts";
CM_ BO_ 2560622334 "Immediate Fault Status";
CM_ BO_ 2560687870 "NTE Status";
CM_ BO_ 2560753406 "Emission Increasing Auxiliary Emission Control Device Active Time";
CM_ BO_ 2560818942 "Regulated Exhaust Emission Level Exceedance";
CM_ BO_ 2560884478 "DTC To Lamp Association";
CM_ BO_ 2560950014 "Scaled Test Results";
CM_ BO_ 2561015550 "Auxiliary Input/Output Status 4";
CM_ BO_ 2561081086 "Auxiliary Input/Output Status 3";
CM_ BO_ 2561146622 "Auxiliary Input/Output Status 2";
CM_ BO_ 2561212158 "Text Display";
CM_ BO_ 2561277694 "Forward Lane Image Command";
CM_ BO_ 2561408766 "File Server to Client (ECU) message";
CM_ BO_ 2561605374 "Tire Pressure Reference Setting";
CM_ BO_ 2561670910 "Parameter Locate Message";
CM_ BO_ 2561736446 "Configuration Identification Message";
CM_ BO_ 2561801982 "Proprietarily Configurable Message #1";
CM_ BO_ 2561867518 "Proprietarily Configurable Message #2";
CM_ BO_ 2561933054 "Proprietarily Configurable Message #3";
CM_ BO_ 2561998590 "Proprietarily Configurable Message #4";
CM_ BO_ 2562064126 "Proprietarily Configurable Message #5";
CM_ BO_ 2562129662 "Proprietarily Configurable Message #6";
CM_ BO_ 2562195198 "Proprietarily Configurable Message #7";
CM_ BO_ 2562260734 "Proprietarily Configurable Message #8";
CM_ BO_ 2562326270 "Proprietarily Configurable Message #9";
CM_ BO_ 2562391806 "Proprietarily Configurable Message #10";
CM_ BO_ 2562457342 "Proprietarily Configurable Message #11";
CM_ BO_ 2562522878 "Proprietarily Configurable Message #12";
CM_ BO_ 2562588414 "Proprietarily Configurable Message #13";
CM_ BO_ 2562653950 "Proprietarily Configurable Message #14";
CM_ BO_ 2562719486 "Proprietarily Configurable Message #15";
CM_ BO_ 2562785022 "Proprietarily Configurable Message #16";
CM_ BO_ 2562850558 "Diagnostic Readiness 2";
CM_ BO_ 2562916094 "Monitor Performance Ratio";
CM_ BO_ 2562981630 "Individual Clear/Reset Of Active And Previously Active DTC";
CM_ BO_ 2563374846 "Request 2";
CM_ BO_ 2563440382 "Transfer";
CM_ BO_ 2563636990 "Reserved for ISO 15765";
CM_ BO_ 2563702526 "Reserved for ISO 15765";
CM_ BO_ 2563768062 "Continuous Torque & Speed Limit Request";
CM_ BO_ 2563833598 "Cab Illumination Message";
CM_ BO_ 2362572542 "Air Suspension Control 6";
CM_ BO_ 2362638078 "Air Suspension Control 2";
CM_ BO_ 2564030206 "Calibration Information";
CM_ BO_ 2564095742 "Data Security";
CM_ BO_ 2564161278 "Time/Date Adjust";
CM_ BO_ 2564226814 "Boot Load Data";
CM_ BO_ 2564292350 "Binary Data Transfer";
CM_ BO_ 2564357886 "Memory Access Response";
CM_ BO_ 2564423422 "Memory Access Request";
CM_ BO_ 2564488958 "Reserved for ISO 15765";
CM_ BO_ 2564554494 "Reserved for ISO 15765";
CM_ BO_ 2631728894 "Anti-theft Status";
CM_ BO_ 2631794430 "Anti-theft Request";
CM_ BO_ 2631859966 "Reset";
CM_ BO_ 2564816638 "Stop Start Broadcast";
CM_ BO_ 2564882174 "Cab Message 1";
CM_ BO_ 2565078782 "Command Non-continuously Monitored Test";
CM_ BO_ 2565406462 "Acknowledgment Message";
CM_ SG_ 2565406462 ACKM_Mux "Positive Acknowledgement";
CM_ BO_ 2565537534 "Request";
CM_ BO_ 2565603070 "Transport Protocol - Data Transfer";
CM_ BO_ 2565668606 "Transport Protocol - Connection Management";
CM_ SG_ 2565668606 TPCM_Mux "Request to Send";
CM_ BO_ 2565734142 "Network Layer";
CM_ BO_ 2565799678 "Address Claimed";
CM_ BO_ 2565865214 "Proprietary A";
CM_ BO_ 2565865726 "Electronic Retarder Controller 1";
CM_ BO_ 2565865982 "Electronic Brake Controller 1";
CM_ BO_ 2364539646 "Electronic Transmission Controller 1";
CM_ BO_ 2364539902 "Electronic Engine Controller 2";
CM_ BO_ 2364540158 "Electronic Engine Controller 1";
CM_ BO_ 2565867006 "Electronic Transmission Controller 2";
CM_ BO_ 2565867262 "Electronic Axle Controller 1";
CM_ BO_ 2431649790 "Forward Lane Image 1";
CM_ BO_ 2565867774 "Hydraulic Pressure Governor Info";
CM_ BO_ 2565868030 "Vehicle Dynamic Stability Control 2";
CM_ BO_ 2364541694 "Engine Gas Flow Rate";
CM_ BO_ 2565868542 "Electronic Steering Control";
CM_ BO_ 2364542206 "Electronic Transmission Controller #8";
CM_ BO_ 2364542462 "Land Leveling System Operational Information";
CM_ BO_ 2565869310 "Aftertreatment 1 Intake Gas 1";

BA_DEF_  "BusType" STRING ;
BA_DEF_  "ProtocolType" STRING ;
BA_DEF_ BO_  "VFrameFormat" ENUM  "StandardCAN","ExtendedCAN","reserved","J1939PG";
BA_DEF_ BO_  "GenMsgCycleTime" INT 0 65535;
BA_DEF_ SG_  "GenSigStartValue" FLOAT -3.4E+038 3.4E+038;
BA_DEF_ SG_  "SPN" INT ;
BA_DEF_ SG_  "SigType" ENUM "Default","Range","RangeSigned","ASCII","Discrete","Control","ReferencePGN","DTC","StringDelimiter","StringLength","StringLengthControl","MessageCounter","MessageChecksum";

BA_DEF_DEF_  "BusType" "CAN";
BA_DEF_DEF_  "ProtocolType" "J1939";
BA_DEF_DEF_  "VFrameFormat" "J1939PG";
BA_DEF_DEF_  "GenMsgCycleTime" 0;
BA_DEF_DEF_  "GenSigStartValue" 0;
BA_DEF_DEF_  "SPN" 0;
BA_DEF_DEF_  "SigType" "Default";

BA_ "GenMsgCycleTime" BO_ 2348875518 10;
BA_ "GenMsgCycleTime" BO_ 2348941054 50;
BA_ "GenMsgCycleTime" BO_ 2349137662 200;
BA_ "GenMsgCycleTime" BO_ 2550660862 100;
BA_ "GenMsgCycleTime" BO_ 2349399806 20;
BA_ "GenMsgCycleTime" BO_ 2349465342 100;
BA_ "GenMsgCycleTime" BO_ 2349530878 100;
BA_ "GenMsgCycleTime" BO_ 2349596414 50;
BA_ "GenMsgCycleTime" BO_ 2550988542 50;
BA_ "GenMsgCycleTime" BO_ 2349727486 50;
BA_ "GenMsgCycleTime" BO_ 2350644990 20;
BA_ "GenMsgCycleTime" BO_ 2350710526 100;
BA_ "GenMsgCycleTime" BO_ 2350841598 200;
BA_ "GenMsgCycleTime" BO_ 2557738750 1000;
BA_ "GenMsgCycleTime" BO_ 2557804286 1000;
BA_ "GenMsgCycleTime" BO_ 2557869822 1000;
BA_ "GenMsgCycleTime" BO_ 2557935358 1000;
BA_ "GenMsgCycleTime" BO_ 2558000894 1000;
BA_ "GenMsgCycleTime" BO_ 2558066430 1000;
BA_ "GenMsgCycleTime" BO_ 2558131966 1000;
BA_ "GenMsgCycleTime" BO_ 2558197502 1000;
BA_ "GenMsgCycleTime" BO_ 2558263038 1000;
BA_ "GenMsgCycleTime" BO_ 2558394110 1000;
BA_ "GenMsgCycleTime" BO_ 2558459646 10000;
BA_ "GenMsgCycleTime" BO_ 2558590718 1000;
BA_ "GenMsgCycleTime" BO_ 2558656254 1000;
BA_ "GenMsgCycleTime" BO_ 2558852862 200;
BA_ "GenMsgCycleTime" BO_ 2558918398 1000;
BA_ "GenMsgCycleTime" BO_ 2559049470 1000;
BA_ "GenMsgCycleTime" BO_ 2559573758 10000;
BA_ "GenMsgCycleTime" BO_ 2559639294 1000;
BA_ "GenMsgCycleTime" BO_ 2559770366 100;
BA_ "GenMsgCycleTime" BO_ 2560032510 500;
BA_ "GenMsgCycleTime" BO_ 2560098046 10000;
BA_ "GenMsgCycleTime" BO_ 2560163582 10000;
BA_ "GenMsgCycleTime" BO_ 2358902526 100;
BA_ "GenMsgCycleTime" BO_ 2560425726 100;
BA_ "GenMsgCycleTime" BO_ 2560491262 100;
BA_ "GenMsgCycleTime" BO_ 2561015550 100;
BA_ "GenMsgCycleTime" BO_ 2561081086 100;
BA_ "GenMsgCycleTime" BO_ 2561146622 100;
BA_ "GenMsgCycleTime" BO_ 2563768062 5000;
BA_ "GenMsgCycleTime" BO_ 2563833598 5000;
BA_ "GenMsgCycleTime" BO_ 2362572542 100;
BA_ "GenMsgCycleTime" BO_ 2362638078 100;
BA_ "GenMsgCycleTime" BO_ 2564882174 1000;
BA_ "GenMsgCycleTime" BO_ 2565865726 100;
BA_ "GenMsgCycleTime" BO_ 2565865982 100;
BA_ "GenMsgCycleTime" BO_ 2364539646 10;
BA_ "GenMsgCycleTime" BO_ 2364539902 50;
BA_ "GenMsgCycleTime" BO_ 2364540158 50;
BA_ "GenMsgCycleTime" BO_ 2565867006 100;
BA_ "GenMsgCycleTime" BO_ 2565867262 500;
BA_ "GenMsgCycleTime" BO_ 2431649790 50;
BA_ "GenMsgCycleTime" BO_ 2565867774 50;
BA_ "GenMsgCycleTime" BO_ 2565868030 10;
BA_ "GenMsgCycleTime" BO_ 2364541694 50;
BA_ "GenMsgCycleTime" BO_ 2565868542 20;
BA_ "GenMsgCycleTime" BO_ 2364542206 20;
BA_ "GenMsgCycleTime" BO_ 2364542462 100;
BA_ "GenMsgCycleTime" BO_ 2565869310 50;

BA_ "GenSigStartValue" SG_ 2564161278 AdjustYear 1985;

BA_ "SPN" SG_ 2348875518 EngineOverrideControlMode 695;
BA_ "SPN" SG_ 2348875518 EngRequestedSpeedCtrlConditions 696;
BA_ "SPN" SG_ 2348875518 OverrideControlModePriority 897;
BA_ "SPN" SG_ 2348875518 EngineRequestedSpeedSpeedLimit 898;
BA_ "SPN" SG_ 2348875518 EngineRequestedTorqueTorqueLimit 518;
BA_ "SPN" SG_ 2348875518 TSC1TransmissionRate 3349;
BA_ "SPN" SG_ 2348875518 TSC1ControlPurpose 3350;
BA_ "SPN" SG_ 2348875518 EngineRequestedTorque 4191;
BA_ "SPN" SG_ 2348875518 MessageCounter 4206;
BA_ "SPN" SG_ 2348875518 MessageChecksum 4207;
BA_ "SPN" SG_ 2348941054 TransmissionGearShiftInhbtRq 681;
BA_ "SPN" SG_ 2348941054 TrnsmTrqCnvLockupDisableRq 682;
BA_ "SPN" SG_ 2348941054 DisengageDrivelineRequest 683;
BA_ "SPN" SG_ 2348941054 TrnsmReverseGearShftInhbtRq 4242;
BA_ "SPN" SG_ 2348941054 RequestedPercentClutchSlip 684;
BA_ "SPN" SG_ 2348941054 TransmissionRequestedGear 525;
BA_ "SPN" SG_ 2348941054 DisengiffLockRequestFrontAxl1 685;
BA_ "SPN" SG_ 2348941054 DisengiffLockRequestFrontAxl2 686;
BA_ "SPN" SG_ 2348941054 DisengageDiffLockRequestRearAxl1 687;
BA_ "SPN" SG_ 2348941054 DisengageDiffLockRequestRearAxl2 688;
BA_ "SPN" SG_ 2348941054 DisengageDiffLockRequestCentral 689;
BA_ "SPN" SG_ 2348941054 DisengiffLockRequestCentralFront 690;
BA_ "SPN" SG_ 2348941054 DisengiffLockRequestCentralRear 691;
BA_ "SPN" SG_ 2348941054 TransmissionLoadRedInhbtRequest 5762;
BA_ "SPN" SG_ 2348941054 TransmissionMode1 1852;
BA_ "SPN" SG_ 2348941054 TransmissionMode2 1853;
BA_ "SPN" SG_ 2348941054 TransmissionMode3 1854;
BA_ "SPN" SG_ 2348941054 TransmissionMode4 1855;
BA_ "SPN" SG_ 2348941054 TransmissionAutoNeutralRequest 7695;
BA_ "SPN" SG_ 2348941054 TransmissionRequestedLaunchGear 4255;
BA_ "SPN" SG_ 2348941054 TrnsmShftSlctorDisplayMdeSw 2985;
BA_ "SPN" SG_ 2348941054 TransmissionMode5 4246;
BA_ "SPN" SG_ 2348941054 TransmissionMode6 4247;
BA_ "SPN" SG_ 2348941054 TransmissionMode7 4248;
BA_ "SPN" SG_ 2348941054 TransmissionMode8 4249;
BA_ "SPN" SG_ 2349137662 ExternalAccelerationDemand 2920;
BA_ "SPN" SG_ 2349137662 XBREBIMode 2914;
BA_ "SPN" SG_ 2349137662 XBRPriority 2915;
BA_ "SPN" SG_ 2349137662 XBRControlMode 2916;
BA_ "SPN" SG_ 2349137662 XBRUrgency 4099;
BA_ "SPN" SG_ 2349137662 XBRMessageCounter 3189;
BA_ "SPN" SG_ 2349137662 XBRMessageChecksum 3188;
BA_ "SPN" SG_ 2550660862 ValveLoadSensePressure 4086;
BA_ "SPN" SG_ 2550660862 ValvePilotPressure 4087;
BA_ "SPN" SG_ 2550660862 ValveAssemblyLoadSensePressure 4088;
BA_ "SPN" SG_ 2550660862 ValveAssemblySupplyPressure 4089;
BA_ "SPN" SG_ 2349399806 AuxiliaryIOChannel6 4155;
BA_ "SPN" SG_ 2349399806 AuxiliaryIOChannel5 4156;
BA_ "SPN" SG_ 2349399806 AuxiliaryIOChannel4 4157;
BA_ "SPN" SG_ 2349399806 AuxiliaryIOChannel3 4158;
BA_ "SPN" SG_ 2349465342 StaticRollAngle 5582;
BA_ "SPN" SG_ 2349465342 StaticRollAngleStatus 5583;
BA_ "SPN" SG_ 2349530878 CruiseControlDisableCommand 5603;
BA_ "SPN" SG_ 2349530878 CruiseControlResumeCommand 5604;
BA_ "SPN" SG_ 2349530878 CruiseControlPauseCommand 5605;
BA_ "SPN" SG_ 2349530878 IdleSpeedRequest 8438;
BA_ "SPN" SG_ 2349530878 IdleControlEnableState 8439;
BA_ "SPN" SG_ 2349530878 IdleControlRequestActivation 8440;
BA_ "SPN" SG_ 2349596414 DrvrActtnDmndAdvEmrgncyBrkngSys 5681;
BA_ "SPN" SG_ 2349596414 AEBS2MessageCounter 5682;
BA_ "SPN" SG_ 2349596414 AEBS2MessageChecksum 5683;
BA_ "SPN" SG_ 2550988542 AcceleratorPedalPosition3 28;
BA_ "SPN" SG_ 2550988542 ReadyForClutchEngagementStatus 7847;
BA_ "SPN" SG_ 2550988542 EngineClutchEngageRequestStatus 7844;
BA_ "SPN" SG_ 2349727486 TransmissionMode9 6569;
BA_ "SPN" SG_ 2349727486 TransmissionMode10 6570;
BA_ "SPN" SG_ 2350644990 HVES1HighVoltageBusConnectCmd 8123;
BA_ "SPN" SG_ 2350644990 HVES1PowerDownCommand 8124;
BA_ "SPN" SG_ 2350644990 HVES1HghVltgBusActIsolatnTestCmd 8125;
BA_ "SPN" SG_ 2350644990 HVES1HiVltgBusPassIsolatnTestCmd 8126;
BA_ "SPN" SG_ 2350644990 HVES1CellBalancingCommand 8127;
BA_ "SPN" SG_ 2350644990 HVES1EnableInternalChrgrCommand 8213;
BA_ "SPN" SG_ 2350644990 HVES1OperationConsent 8412;
BA_ "SPN" SG_ 2350644990 HVES1HiVltgBusHiSdeResistCnnctRq 8433;
BA_ "SPN" SG_ 2350644990 HVES1HiVltgBusLoSdeResistCnnctRq 8434;
BA_ "SPN" SG_ 2350710526 TransmissionOverrideControlMode 7037;
BA_ "SPN" SG_ 2350710526 TrnsmOverrdCtrlMdePriority 7038;
BA_ "SPN" SG_ 2350710526 MessageCounter 7041;
BA_ "SPN" SG_ 2350710526 TransmissionRqedOutptShaftSpeed 7039;
BA_ "SPN" SG_ 2350710526 TransmissionRqedTorqueTorqueLmt 7040;
BA_ "SPN" SG_ 2350710526 MessageChecksum 7042;
BA_ "SPN" SG_ 2350776062 EngineTimingAdvance 7355;
BA_ "SPN" SG_ 2350841598 AlternatorSetpointVoltageCommand 7589;
BA_ "SPN" SG_ 2350841598 AltrntrExcitationMaximumCurrLmt 7590;
BA_ "SPN" SG_ 2350841598 AlternatorTorqueRampTimeCommand 7591;
BA_ "SPN" SG_ 2350841598 AltrntrTorqueRampMaximumSpeedCmd 7592;
BA_ "SPN" SG_ 2557345534 WellStimuPmpGearBxOilPrsLoTrshld 8860;
BA_ "SPN" SG_ 2557345534 WellStimuPmpGearBxOilPrsHiTrshld 8861;
BA_ "SPN" SG_ 2557345534 WellStimuPmpGearBxOilTmpLoTrshld 8862;
BA_ "SPN" SG_ 2557345534 WellStimuPmpGearBxOilTmpHiTrshld 8863;
BA_ "SPN" SG_ 2557345534 WellStimuPmpSuctionPrsLoTrshld 8864;
BA_ "SPN" SG_ 2557345534 WellStimuPmpSuctionPrsHiTrshld 8865;
BA_ "SPN" SG_ 2557345534 WellStimuPmpDisChrgPrsHiTrshld 8866;
BA_ "SPN" SG_ 2557345534 WellStimultnPmpCrankSpdLowTrshld 8867;
BA_ "SPN" SG_ 2557345534 WellStimultnPmpCrankSpdHghTrshld 8868;
BA_ "SPN" SG_ 2557345534 WellStimultnPmpRodLoadHghTrshld 8869;
BA_ "SPN" SG_ 2557345534 WellStimuPmpPlungerFiringOrder 8870;
BA_ "SPN" SG_ 2624519934 ReceiveSPNsCommandedPort 8837;
BA_ "SPN" SG_ 2624519934 ReceiveSPNsTransactionMode 8838;
BA_ "SPN" SG_ 2624519934 CommandedReceiveSPN 8839;
BA_ "SPN" SG_ 2624519934 CmdedReceiveSPNRequestedState 8840;
BA_ "SPN" SG_ 2624519934 CommandedReceiveSPNSourceAddress 8841;
BA_ "SPN" SG_ 2624716542 TransmitPGNsCommandedPort 8595;
BA_ "SPN" SG_ 2624716542 TransmitPGNsTransactionMode 8596;
BA_ "SPN" SG_ 2624716542 CommandedTransmitPGN 8597;
BA_ "SPN" SG_ 2624716542 CmdedTransmitPGNRequestedState 8598;
BA_ "SPN" SG_ 2557673214 OilDebrisMontConfIdntfctionNo 8191;
BA_ "SPN" SG_ 2557673214 OilDebrisMonitorFerrsBin1CntCmd 8192;
BA_ "SPN" SG_ 2557673214 OilDebrisMonitorFerrsBin2CntCmd 8193;
BA_ "SPN" SG_ 2557673214 OilDebrisMonitorFerrsBin3CntCmd 8194;
BA_ "SPN" SG_ 2557673214 OilDebrisMonitorFerrsBin4CntCmd 8195;
BA_ "SPN" SG_ 2557673214 OilDebrisMonitorFerrsBin5CntCmd 8196;
BA_ "SPN" SG_ 2557673214 OilDebrisMonitorFerrsBin6CntCmd 8197;
BA_ "SPN" SG_ 2557673214 OilDebrisMontNonFerrsBin1CntCmd 8198;
BA_ "SPN" SG_ 2557673214 OilDebrisMontNonFerrsBin2CntCmd 8199;
BA_ "SPN" SG_ 2557673214 OilDebrisMontNonFerrsBin3CntCmd 8200;
BA_ "SPN" SG_ 2557673214 OilDebrisMontNonFerrsBin4CntCmd 8201;
BA_ "SPN" SG_ 2557673214 OilDebrisMontNonFerrsBin5CntCmd 8202;
BA_ "SPN" SG_ 2557673214 OilDebrisMontNonFerrsBin6CntCmd 8203;
BA_ "SPN" SG_ 2557738750 PropulsionMotorCoolntFan3EnblCmd 8063;
BA_ "SPN" SG_ 2557738750 PropulsionMtrCoolntFn3PowerHold 8064;
BA_ "SPN" SG_ 2557738750 PropulsionMotorCoolntFn3SpeedCmd 8065;
BA_ "SPN" SG_ 2557738750 ProplsnMtrCoolntFn3PrcntSpeedCmd 8066;
BA_ "SPN" SG_ 2557804286 PropulsionMotorCoolntFan2EnblCmd 8051;
BA_ "SPN" SG_ 2557804286 PropulsionMtrCoolntFn2PowerHold 8052;
BA_ "SPN" SG_ 2557804286 PropulsionMotorCoolntFn2SpeedCmd 8053;
BA_ "SPN" SG_ 2557804286 ProplsnMtrCoolntFn2PrcntSpeedCmd 8054;
BA_ "SPN" SG_ 2557869822 PropulsionMotorCoolntFan1EnblCmd 8039;
BA_ "SPN" SG_ 2557869822 PropulsionMtrCoolntFn1PowerHold 8040;
BA_ "SPN" SG_ 2557869822 PropulsionMotorCoolntFn1SpeedCmd 8041;
BA_ "SPN" SG_ 2557869822 ProplsnMtrCoolntFn1PrcntSpeedCmd 8042;
BA_ "SPN" SG_ 2557935358 PowerElctrncsCoolntFan3EnableCmd 8027;
BA_ "SPN" SG_ 2557935358 PowerElctrncsCoolntFan3PowerHold 8028;
BA_ "SPN" SG_ 2557935358 PowerElctrncsCoolntFan3SpeedCmd 8029;
BA_ "SPN" SG_ 2557935358 PwrElctrncsCoolntFn3PrcntSpdCmd 8030;
BA_ "SPN" SG_ 2558000894 PowerElctrncsCoolntFan2EnableCmd 8015;
BA_ "SPN" SG_ 2558000894 PowerElctrncsCoolntFan2PowerHold 8016;
BA_ "SPN" SG_ 2558000894 PowerElctrncsCoolntFan2SpeedCmd 8017;
BA_ "SPN" SG_ 2558000894 PwrElctrncsCoolntFn2PrcntSpdCmd 8018;
BA_ "SPN" SG_ 2558066430 PowerElctrncsCoolntFan1EnableCmd 8003;
BA_ "SPN" SG_ 2558066430 PowerElctrncsCoolntFan1PowerHold 8004;
BA_ "SPN" SG_ 2558066430 PowerElctrncsCoolntFan1SpeedCmd 8005;
BA_ "SPN" SG_ 2558066430 PwrElctrncsCoolntFn1PrcntSpdCmd 8006;
BA_ "SPN" SG_ 2558131966 PropulsionMotorOilPumpEnableCmd 7991;
BA_ "SPN" SG_ 2558131966 PropulsionMotorOilPumpPowerHold 7992;
BA_ "SPN" SG_ 2558131966 PropulsionMotorOilPumpSpeedCmd 7993;
BA_ "SPN" SG_ 2558131966 ProplsnMtrOilPumpPrcntSpeedCmd 7994;
BA_ "SPN" SG_ 2558197502 PropulsionMotorCoolntPumpEnblCmd 7979;
BA_ "SPN" SG_ 2558197502 PropulsionMtrCoolntPumpPowerHold 7980;
BA_ "SPN" SG_ 2558197502 PropulsionMtrCoolntPumpSpeedCmd 7981;
BA_ "SPN" SG_ 2558197502 ProplsnMtrCoolntPmpPrcntSpeedCmd 7982;
BA_ "SPN" SG_ 2558263038 PowerElctrncsCoolntPumpEnableCmd 7967;
BA_ "SPN" SG_ 2558263038 PowerElctrncsCoolntPumpPowerHold 7968;
BA_ "SPN" SG_ 2558263038 PowerElctrncsCoolntPumpSpeedCmd 7969;
BA_ "SPN" SG_ 2558263038 PwrElctrncsCoolntPmpPrcntSpdCmd 7970;
BA_ "SPN" SG_ 2558394110 ElectrifiedAccssryMotorEnableCmd 7943;
BA_ "SPN" SG_ 2558394110 ElectrifiedAccssryMotorPowerHold 7944;
BA_ "SPN" SG_ 2558394110 ElectrifiedAccssryMotorSpeedCmd 7945;
BA_ "SPN" SG_ 2558394110 ElectrfdAccssryMtrPrcntSpeedCmd 7946;
BA_ "SPN" SG_ 2558394110 ElectrifiedAccssryMotorInstance1 8292;
BA_ "SPN" SG_ 2558394110 ElectrifiedAccssryMotorInstance2 8293;
BA_ "SPN" SG_ 2558394110 ElectrifiedAccssryMotorInstance3 8294;
BA_ "SPN" SG_ 2558394110 ElectrifiedAccssryMotorInstance4 8295;
BA_ "SPN" SG_ 2558394110 ElectrifiedAccssryMotorInstance5 8296;
BA_ "SPN" SG_ 2558394110 ElectrifiedAccssryMotorInstance6 8297;
BA_ "SPN" SG_ 2558394110 ElectrifiedAccssryMotorInstance7 8298;
BA_ "SPN" SG_ 2558394110 ElectrifiedAccssryMotorInstance8 8299;
BA_ "SPN" SG_ 2558394110 ElectrifiedAccssryMotorInstance9 8300;
BA_ "SPN" SG_ 2558394110 ElectrfdAccssryMotorInstance10 8301;
BA_ "SPN" SG_ 2558394110 ElectrfdAccssryMotorInstance11 8302;
BA_ "SPN" SG_ 2558394110 ElectrfdAccssryMotorInstance12 8303;
BA_ "SPN" SG_ 2558394110 ElectrfdAccssryMotorInstance13 8304;
BA_ "SPN" SG_ 2558394110 ElectrfdAccssryMotorInstance14 8305;
BA_ "SPN" SG_ 2558394110 ElectrfdAccssryMotorInstance15 8306;
BA_ "SPN" SG_ 2558459646 RequestedEngSpeedAccltnRateLimit 7760;
BA_ "SPN" SG_ 2558459646 RqedEngSpeedDecelerationRateLmt 7761;
BA_ "SPN" SG_ 2558525182 NumberOfTireSensors 7583;
BA_ "SPN" SG_ 2558525182 TireNumber 7584;
BA_ "SPN" SG_ 2558525182 TireLocation 7585;
BA_ "SPN" SG_ 2558525182 TireSensorIdentificationNumber 7586;
BA_ "SPN" SG_ 2558590718 HybridSystemPrtctnOverrdRequest 7557;
BA_ "SPN" SG_ 2558590718 HybridSystemProplsnDisablRequest 7558;
BA_ "SPN" SG_ 2558590718 HybridSysRegativeBrkngDisablRq 7559;
BA_ "SPN" SG_ 2558590718 HybridSystemShutdownCommand 7560;
BA_ "SPN" SG_ 2558590718 OperatorVehicleModeRequest 7888;
BA_ "SPN" SG_ 2558590718 HybridPropulsionModeRequest 7889;
BA_ "SPN" SG_ 2558590718 ExternalEnergySourceConnectnDmnd 7890;
BA_ "SPN" SG_ 2558590718 StoredEnergySrcChrgDisChrgRateRq 7891;
BA_ "SPN" SG_ 2558590718 StoredEnergySourceSetPointRq 7892;
BA_ "SPN" SG_ 2558656254 AftrtrtmntThermalMangmntInhbtRq 7331;
BA_ "SPN" SG_ 2558656254 RqToPermitDEFHydrStiffnessChk 7515;
BA_ "SPN" SG_ 2558656254 RequestToPermitDEFDsngTestInject 7516;
BA_ "SPN" SG_ 2558656254 AftertreatmentSystemEnableStatus 7851;
BA_ "SPN" SG_ 2558656254 AftDslExhstFldDoserRdyStat 8149;
BA_ "SPN" SG_ 2558721790 TireLocation 6973;
BA_ "SPN" SG_ 2558721790 ColdInflationPressureSetting 6974;
BA_ "SPN" SG_ 2558721790 UnderPressPrcntageThresholdSttng 6975;
BA_ "SPN" SG_ 2558721790 ExtrmUnderPrsPrcntageTrshldSttng 6976;
BA_ "SPN" SG_ 2558721790 OverPressPrcntageThresholdSttng 6977;
BA_ "SPN" SG_ 2558721790 OverTemperatureSetting 6978;
BA_ "SPN" SG_ 2558721790 TireSensorEnableSetting 7587;
BA_ "SPN" SG_ 2558787326 PayloadClbrtnSetPointCommand 6871;
BA_ "SPN" SG_ 2558787326 PayloadClbrtnCommandedWeight 6872;
BA_ "SPN" SG_ 2558787326 PayloadCorrectionFactorCommand 6873;
BA_ "SPN" SG_ 2558852862 Aft1PrticulateSnsrShtdwnRq 6782;
BA_ "SPN" SG_ 2558852862 Aftrtrtmnt1PrticulateSnsrRegenRq 6783;
BA_ "SPN" SG_ 2558852862 Aft1PrticulateSnsrDewpoint 6784;
BA_ "SPN" SG_ 2558852862 Aft1PrticulateSnsrExhstTemp 6785;
BA_ "SPN" SG_ 2558852862 Aft1PrticulateSnsrExhstVelocity 6829;
BA_ "SPN" SG_ 2558918398 EngineFan2RequestedPercentSpeed 6730;
BA_ "SPN" SG_ 2558918398 PerformanceBiasSelection 6874;
BA_ "SPN" SG_ 2558918398 SCROperatorIndcmntOverrideSwitch 6881;
BA_ "SPN" SG_ 2558918398 HeatExchngrDebrisPurgeInhbtSw 7033;
BA_ "SPN" SG_ 2558918398 HeatExchngrDebrisPurgeForceSw 7034;
BA_ "SPN" SG_ 2558918398 PredictiveCruiseCtrlEnableSwitch 7436;
BA_ "SPN" SG_ 2558918398 PredictCrsCtrlDeactivationRq 7437;
BA_ "SPN" SG_ 2558918398 EngineStopStartDisableCommand 7759;
BA_ "SPN" SG_ 2558918398 ElevatedEngineSpeedAllowedSwitch 7579;
BA_ "SPN" SG_ 2558918398 AftrtrtmntRegenEngSpdAllwdSwitch 7580;
BA_ "SPN" SG_ 2558918398 PredictiveCrsCtrlMaxPstvOffst 7438;
BA_ "SPN" SG_ 2558918398 PredictiveCrsCtrlMaxNegOffset 7439;
BA_ "SPN" SG_ 2558918398 TransmissionAutoNtrlEnblSwitch 7694;
BA_ "SPN" SG_ 2558918398 AftrtrtmntSystemEnableCommand 8148;
BA_ "SPN" SG_ 2558918398 ActiveShiftConsoleRequest 8855;
BA_ "SPN" SG_ 2558983934 SwitchedPowerOutput4Command 5984;
BA_ "SPN" SG_ 2558983934 SwitchedPowerOutput3Command 5985;
BA_ "SPN" SG_ 2558983934 SwitchedPowerOutput2Command 5986;
BA_ "SPN" SG_ 2558983934 SwitchedPowerOutput1Command 5987;
BA_ "SPN" SG_ 2558983934 SwitchedPowerOutput8Command 5988;
BA_ "SPN" SG_ 2558983934 SwitchedPowerOutput7Command 5989;
BA_ "SPN" SG_ 2558983934 SwitchedPowerOutput6Command 5990;
BA_ "SPN" SG_ 2558983934 SwitchedPowerOutput5Command 5991;
BA_ "SPN" SG_ 2558983934 SwitchedPowerOutput12Command 5992;
BA_ "SPN" SG_ 2558983934 SwitchedPowerOutput11Command 5993;
BA_ "SPN" SG_ 2558983934 SwitchedPowerOutput10Command 5994;
BA_ "SPN" SG_ 2558983934 SwitchedPowerOutput9Command 5995;
BA_ "SPN" SG_ 2558983934 SwitchedPowerOutput16Command 5996;
BA_ "SPN" SG_ 2558983934 SwitchedPowerOutput15Command 5997;
BA_ "SPN" SG_ 2558983934 SwitchedPowerOutput14Command 5998;
BA_ "SPN" SG_ 2558983934 SwitchedPowerOutput13Command 5999;
BA_ "SPN" SG_ 2558983934 SwitchedPowerOutput20Command 6000;
BA_ "SPN" SG_ 2558983934 SwitchedPowerOutput19Command 6001;
BA_ "SPN" SG_ 2558983934 SwitchedPowerOutput18Command 6002;
BA_ "SPN" SG_ 2558983934 SwitchedPowerOutput17Command 6003;
BA_ "SPN" SG_ 2558983934 SwitchedPowerOutput24Command 6004;
BA_ "SPN" SG_ 2558983934 SwitchedPowerOutput23Command 6005;
BA_ "SPN" SG_ 2558983934 SwitchedPowerOutput22Command 6006;
BA_ "SPN" SG_ 2558983934 SwitchedPowerOutput21Command 6007;
BA_ "SPN" SG_ 2558983934 SwitchedPowerOutput28Command 6008;
BA_ "SPN" SG_ 2558983934 SwitchedPowerOutput27Command 6009;
BA_ "SPN" SG_ 2558983934 SwitchedPowerOutput26Command 6010;
BA_ "SPN" SG_ 2558983934 SwitchedPowerOutput25Command 6011;
BA_ "SPN" SG_ 2558983934 SwitchedPowerOutput32Command 6012;
BA_ "SPN" SG_ 2558983934 SwitchedPowerOutput31Command 6013;
BA_ "SPN" SG_ 2558983934 SwitchedPowerOutput30Command 6014;
BA_ "SPN" SG_ 2558983934 SwitchedPowerOutput29Command 6015;
BA_ "SPN" SG_ 2559049470 DesiredEngineFuelingState 5793;
BA_ "SPN" SG_ 2559049470 EngineGaseousFuelUsageInhibited 6833;
BA_ "SPN" SG_ 2559049470 RequestedFuelType 6317;
BA_ "SPN" SG_ 2559049470 EngineGasSupplyDesiredPressure 6715;
BA_ "SPN" SG_ 2559049470 EngineFuelingDesiredReason 7789;
BA_ "SPN" SG_ 2559049470 TransmissionIdlGvrnrFuelngInhbt 7829;
BA_ "SPN" SG_ 2559049470 EngineShutdownCommand 8614;
BA_ "SPN" SG_ 2559049470 EngineFuelingNotDesiredReason 7855;
BA_ "SPN" SG_ 2559115006 UniqueBeaconMessageIdentifierNo 5754;
BA_ "SPN" SG_ 2559115006 RadioBeaconDirection 5755;
BA_ "SPN" SG_ 2559115006 TransmitterID2 5756;
BA_ "SPN" SG_ 2559115006 WirelessSignalStrength2 5757;
BA_ "SPN" SG_ 2559573758 CoolntLvlEngPrtctnShtdwnOvrrdCmd 5565;
BA_ "SPN" SG_ 2559639294 SupplementalFanEnableCommand 5552;
BA_ "SPN" SG_ 2559639294 SupplementalFanDirectionCommand 5553;
BA_ "SPN" SG_ 2559639294 SupplementalFanSpeedCommand 5554;
BA_ "SPN" SG_ 2559639294 SupplementalFanPowerHold 5555;
BA_ "SPN" SG_ 2559704830 LubricationCycleModeLockCommand 5510;
BA_ "SPN" SG_ 2559704830 LubricationCycleSetCommand 5511;
BA_ "SPN" SG_ 2559704830 LubricationOperationModeSetCmd 5512;
BA_ "SPN" SG_ 2559704830 LubricationPumpEnableCommand 5513;
BA_ "SPN" SG_ 2559704830 LubricationTimingCycleCommand 5514;
BA_ "SPN" SG_ 2559770366 RequestedFuelMassRate 5505;
BA_ "SPN" SG_ 2559770366 HCDoserStatus 5506;
BA_ "SPN" SG_ 2559770366 HCDoserInjectingStatus 5507;
BA_ "SPN" SG_ 2559770366 DiagnosticStatusOfHCDoser 5508;
BA_ "SPN" SG_ 2559770366 HydrocarbonDoserPurgingRequired 5509;
BA_ "SPN" SG_ 2559835902 NAMEChecksumErrorCode 5657;
BA_ "SPN" SG_ 2559835902 ManufacturerCodeQualifierFlag 5658;
BA_ "SPN" SG_ 2559835902 ECUInstanceQualifierFlag 5659;
BA_ "SPN" SG_ 2559835902 FunctionInstanceQualifierFlag 5660;
BA_ "SPN" SG_ 2559835902 FunctionQualifierFlag 5661;
BA_ "SPN" SG_ 2559835902 VehicleSystemQualifierFlag 5662;
BA_ "SPN" SG_ 2559835902 VehicleSystemInstanceQulfrFlg 5663;
BA_ "SPN" SG_ 2559835902 IndustryGroupQualifierFlag 5664;
BA_ "SPN" SG_ 2559835902 ArbtrryAddrCapableQualifierFlag 5665;
BA_ "SPN" SG_ 2559835902 NMControlModeIndicator 5666;
BA_ "SPN" SG_ 2559835902 CommandedManufacturerCode 5667;
BA_ "SPN" SG_ 2559835902 CommandedECUInstance 5668;
BA_ "SPN" SG_ 2559835902 CommandedFunctionInstance 5669;
BA_ "SPN" SG_ 2559835902 CommandedFunction 5670;
BA_ "SPN" SG_ 2559835902 CommandedVehicleSystem 5671;
BA_ "SPN" SG_ 2559835902 CommandedVehicleSystemInstance 5672;
BA_ "SPN" SG_ 2559835902 CommandedIndustryGroup 5673;
BA_ "SPN" SG_ 2559835902 CommandedArbitraryAddressCapable 5674;
BA_ "SPN" SG_ 2559901438 Aft1DslPFSootMeanClbrtnOffst 5495;
BA_ "SPN" SG_ 2559901438 Aft1DslPFSootStdDviatClbrtnOffst 5496;
BA_ "SPN" SG_ 2559966974 Aft2DslPFSootMeanClbrtnOffst 5497;
BA_ "SPN" SG_ 2559966974 Aft2DslPFSootStdDviatClbrtnOffst 5498;
BA_ "SPN" SG_ 2560032510 LowVoltageDiscnnctDsrdOprtngMde 5149;
BA_ "SPN" SG_ 2560098046 CabNoiseControlStatus 5059;
BA_ "SPN" SG_ 2560098046 CabNoiseControlTuningStatus 5060;
BA_ "SPN" SG_ 2560163582 CabNoiseControlCommand 5057;
BA_ "SPN" SG_ 2560163582 CabNoiseControlTuningCommand 5058;
BA_ "SPN" SG_ 2358902526 Joystick1Lamp1Command 4460;
BA_ "SPN" SG_ 2358902526 Joystick1Lamp2Command 4461;
BA_ "SPN" SG_ 2358902526 Joystick1Lamp3Command 4462;
BA_ "SPN" SG_ 2358902526 Joystick1Lamp4Command 4463;
BA_ "SPN" SG_ 2358902526 Joystick1Lamp5Command 4464;
BA_ "SPN" SG_ 2358902526 Joystick1Lamp6Command 4465;
BA_ "SPN" SG_ 2358902526 Joystick1Lamp7Command 4466;
BA_ "SPN" SG_ 2358902526 Joystick1Lamp8Command 4467;
BA_ "SPN" SG_ 2358902526 Joystick1Lamp9Command 4468;
BA_ "SPN" SG_ 2358902526 Joystick1Lamp10Command 4469;
BA_ "SPN" SG_ 2358902526 Joystick2Lamp1Command 4470;
BA_ "SPN" SG_ 2358902526 Joystick2Lamp2Command 4471;
BA_ "SPN" SG_ 2358902526 Joystick2Lamp3Command 4472;
BA_ "SPN" SG_ 2358902526 Joystick2Lamp4Command 4473;
BA_ "SPN" SG_ 2358902526 Joystick2Lamp5Command 4474;
BA_ "SPN" SG_ 2358902526 Joystick2Lamp6Command 4475;
BA_ "SPN" SG_ 2358902526 Joystick2Lamp7Command 4476;
BA_ "SPN" SG_ 2358902526 Joystick2Lamp8Command 4477;
BA_ "SPN" SG_ 2358902526 Joystick2Lamp9Command 4478;
BA_ "SPN" SG_ 2358902526 Joystick2Lamp10Command 4479;
BA_ "SPN" SG_ 2358902526 Joystick3Lamp1Command 4480;
BA_ "SPN" SG_ 2358902526 Joystick3Lamp2Command 4481;
BA_ "SPN" SG_ 2358902526 Joystick3Lamp3Command 4482;
BA_ "SPN" SG_ 2358902526 Joystick3Lamp4Command 4483;
BA_ "SPN" SG_ 2358902526 Joystick3Lamp5Command 4484;
BA_ "SPN" SG_ 2358902526 Joystick3Lamp6Command 4485;
BA_ "SPN" SG_ 2358902526 Joystick3Lamp7Command 4486;
BA_ "SPN" SG_ 2358902526 Joystick3Lamp8Command 4487;
BA_ "SPN" SG_ 2358902526 Joystick3Lamp9Command 4488;
BA_ "SPN" SG_ 2358902526 Joystick3Lamp10Command 4489;
BA_ "SPN" SG_ 2560360190 DataDictionaryManufacturerCode 4180;
BA_ "SPN" SG_ 2560360190 DataDictionaryMethod 4181;
BA_ "SPN" SG_ 2560425726 AuxiliaryIOChannel18 4167;
BA_ "SPN" SG_ 2560425726 AuxiliaryIOChannel17 4168;
BA_ "SPN" SG_ 2560425726 AuxiliaryIOChannel16 4169;
BA_ "SPN" SG_ 2560425726 AuxiliaryIOChannel15 4170;
BA_ "SPN" SG_ 2560425726 AuxiliaryIOChannel22 4171;
BA_ "SPN" SG_ 2560425726 AuxiliaryIOChannel21 4172;
BA_ "SPN" SG_ 2560425726 AuxiliaryIOChannel20 4173;
BA_ "SPN" SG_ 2560425726 AuxiliaryIOChannel19 4174;
BA_ "SPN" SG_ 2560491262 AuxiliaryIOChannel10 4159;
BA_ "SPN" SG_ 2560491262 AuxiliaryIOChannel9 4160;
BA_ "SPN" SG_ 2560491262 AuxiliaryIOChannel8 4161;
BA_ "SPN" SG_ 2560491262 AuxiliaryIOChannel7 4162;
BA_ "SPN" SG_ 2560491262 AuxiliaryIOChannel14 4163;
BA_ "SPN" SG_ 2560491262 AuxiliaryIOChannel13 4164;
BA_ "SPN" SG_ 2560491262 AuxiliaryIOChannel12 4165;
BA_ "SPN" SG_ 2560491262 AuxiliaryIOChannel11 4166;
BA_ "SPN" SG_ 2560556798 PendingDTCs 4104;
BA_ "SPN" SG_ 2560556798 AllPendingDTCs 4105;
BA_ "SPN" SG_ 2560556798 MILOnDTCs 4106;
BA_ "SPN" SG_ 2560556798 PreviouslyMILOnDTCs 4107;
BA_ "SPN" SG_ 2560556798 PermanentDTCs 4108;
BA_ "SPN" SG_ 2560622334 ProtectLamp 987;
BA_ "SPN" SG_ 2560622334 AmberWarningLamp 624;
BA_ "SPN" SG_ 2560622334 RedStopLamp 623;
BA_ "SPN" SG_ 2560622334 MalfunctionIndicatorLamp 1213;
BA_ "SPN" SG_ 2560622334 FlashProtectLamp 3041;
BA_ "SPN" SG_ 2560622334 FlashAmberWarningLamp 3040;
BA_ "SPN" SG_ 2560622334 FlashRedStopLamp 3039;
BA_ "SPN" SG_ 2560622334 FlashMalfunctionIndicatorLamp 3038;
BA_ "SPN" SG_ 2560622334 SuspectParameterNumber 1214;
BA_ "SPN" SG_ 2560622334 FailureModeIdentifier 1215;
BA_ "SPN" SG_ 2560622334 OccurrenceCount 1216;
BA_ "SPN" SG_ 2560622334 SPNConversionMethod 1706;
BA_ "SPN" SG_ 2560687870 NOxNTEDeficiencyAreaStatus 4129;
BA_ "SPN" SG_ 2560687870 ManfctSpcNOxNTELmtedTestRgnStat 4128;
BA_ "SPN" SG_ 2560687870 NOxNTEControlAreaStatus 4127;
BA_ "SPN" SG_ 2560687870 PMNTEDeficiencyAreaStatus 4132;
BA_ "SPN" SG_ 2560687870 ManfctSpcPMNTELmtedTestRgnStat 4131;
BA_ "SPN" SG_ 2560687870 PMNTEControlAreaStatus 4130;
BA_ "SPN" SG_ 2560753406 EIAECDNumber 4124;
BA_ "SPN" SG_ 2560753406 EIAECDEngineHoursTimer1 4125;
BA_ "SPN" SG_ 2560753406 EIAECDEngineHoursTimer2 4126;
BA_ "SPN" SG_ 2560818942 SuspectParameterNumber 1214;
BA_ "SPN" SG_ 2560818942 FailureModeIdentifier 1215;
BA_ "SPN" SG_ 2560818942 DTCxTotalActiveTime 4121;
BA_ "SPN" SG_ 2560818942 DTCxTotalPreviouslyActiveTime 4122;
BA_ "SPN" SG_ 2560818942 DTCxTimeUntilDerate 4123;
BA_ "SPN" SG_ 2560884478 SuspectParameterNumber 1214;
BA_ "SPN" SG_ 2560884478 FailureModeIdentifier 1215;
BA_ "SPN" SG_ 2560884478 OccurrenceCount 1216;
BA_ "SPN" SG_ 2560884478 SPNConversionMethod 1706;
BA_ "SPN" SG_ 2560884478 DTCxProtectLampSupportStatus 4116;
BA_ "SPN" SG_ 2560884478 DTCxAmberWarningLampSupportStat 4115;
BA_ "SPN" SG_ 2560884478 DTCxRedStopLampSupportStatus 4114;
BA_ "SPN" SG_ 2560884478 DTCxMalfnctnIndictrLampSuppStat 4113;
BA_ "SPN" SG_ 2560884478 DTCxFlashProtectLampSupportStat 4120;
BA_ "SPN" SG_ 2560884478 DTCxFlashAmberWrngLampSuppStat 4119;
BA_ "SPN" SG_ 2560884478 DTCxFlashRedStopLampSupportStat 4118;
BA_ "SPN" SG_ 2560884478 DTCxFlashMalfctIndictrLampSuppSt 4117;
BA_ "SPN" SG_ 2560950014 TestIdentifier 1224;
BA_ "SPN" SG_ 2560950014 SuspectParameterNumber 1214;
BA_ "SPN" SG_ 2560950014 FailureModeIdentifier 1215;
BA_ "SPN" SG_ 2560950014 SLOTIdentifier 4109;
BA_ "SPN" SG_ 2560950014 TestValue 4110;
BA_ "SPN" SG_ 2560950014 TestLimitMaximum 4111;
BA_ "SPN" SG_ 2560950014 TestLimitMinimum 4112;
BA_ "SPN" SG_ 2561015550 AuxiliaryIO84 3907;
BA_ "SPN" SG_ 2561015550 AuxiliaryIO83 3906;
BA_ "SPN" SG_ 2561015550 AuxiliaryIO82 3905;
BA_ "SPN" SG_ 2561015550 AuxiliaryIO81 3904;
BA_ "SPN" SG_ 2561015550 AuxiliaryIO88 3911;
BA_ "SPN" SG_ 2561015550 AuxiliaryIO87 3910;
BA_ "SPN" SG_ 2561015550 AuxiliaryIO86 3909;
BA_ "SPN" SG_ 2561015550 AuxiliaryIO85 3908;
BA_ "SPN" SG_ 2561015550 AuxiliaryIO92 3915;
BA_ "SPN" SG_ 2561015550 AuxiliaryIO91 3914;
BA_ "SPN" SG_ 2561015550 AuxiliaryIO90 3913;
BA_ "SPN" SG_ 2561015550 AuxiliaryIO89 3912;
BA_ "SPN" SG_ 2561015550 AuxiliaryIO96 3919;
BA_ "SPN" SG_ 2561015550 AuxiliaryIO95 3918;
BA_ "SPN" SG_ 2561015550 AuxiliaryIO94 3917;
BA_ "SPN" SG_ 2561015550 AuxiliaryIO93 3916;
BA_ "SPN" SG_ 2561015550 AuxiliaryIO100 3923;
BA_ "SPN" SG_ 2561015550 AuxiliaryIO99 3922;
BA_ "SPN" SG_ 2561015550 AuxiliaryIO98 3921;
BA_ "SPN" SG_ 2561015550 AuxiliaryIO97 3920;
BA_ "SPN" SG_ 2561015550 AuxiliaryIO104 3927;
BA_ "SPN" SG_ 2561015550 AuxiliaryIO103 3926;
BA_ "SPN" SG_ 2561015550 AuxiliaryIO102 3925;
BA_ "SPN" SG_ 2561015550 AuxiliaryIO101 3924;
BA_ "SPN" SG_ 2561015550 AuxiliaryIO108 3931;
BA_ "SPN" SG_ 2561015550 AuxiliaryIO107 3930;
BA_ "SPN" SG_ 2561015550 AuxiliaryIO106 3929;
BA_ "SPN" SG_ 2561015550 AuxiliaryIO105 3928;
BA_ "SPN" SG_ 2561015550 AuxiliaryIO112 3935;
BA_ "SPN" SG_ 2561015550 AuxiliaryIO111 3934;
BA_ "SPN" SG_ 2561015550 AuxiliaryIO110 3933;
BA_ "SPN" SG_ 2561015550 AuxiliaryIO109 3932;
BA_ "SPN" SG_ 2561081086 AuxiliaryIO52 3875;
BA_ "SPN" SG_ 2561081086 AuxiliaryIO51 3874;
BA_ "SPN" SG_ 2561081086 AuxiliaryIO50 3873;
BA_ "SPN" SG_ 2561081086 AuxiliaryIO49 3872;
BA_ "SPN" SG_ 2561081086 AuxiliaryIO56 3879;
BA_ "SPN" SG_ 2561081086 AuxiliaryIO55 3878;
BA_ "SPN" SG_ 2561081086 AuxiliaryIO54 3877;
BA_ "SPN" SG_ 2561081086 AuxiliaryIO53 3876;
BA_ "SPN" SG_ 2561081086 AuxiliaryIO60 3883;
BA_ "SPN" SG_ 2561081086 AuxiliaryIO59 3882;
BA_ "SPN" SG_ 2561081086 AuxiliaryIO58 3881;
BA_ "SPN" SG_ 2561081086 AuxiliaryIO57 3880;
BA_ "SPN" SG_ 2561081086 AuxiliaryIO64 3887;
BA_ "SPN" SG_ 2561081086 AuxiliaryIO63 3886;
BA_ "SPN" SG_ 2561081086 AuxiliaryIO62 3885;
BA_ "SPN" SG_ 2561081086 AuxiliaryIO61 3884;
BA_ "SPN" SG_ 2561081086 AuxiliaryIO68 3891;
BA_ "SPN" SG_ 2561081086 AuxiliaryIO67 3890;
BA_ "SPN" SG_ 2561081086 AuxiliaryIO66 3889;
BA_ "SPN" SG_ 2561081086 AuxiliaryIO65 3888;
BA_ "SPN" SG_ 2561081086 AuxiliaryIO72 3895;
BA_ "SPN" SG_ 2561081086 AuxiliaryIO71 3894;
BA_ "SPN" SG_ 2561081086 AuxiliaryIO70 3893;
BA_ "SPN" SG_ 2561081086 AuxiliaryIO69 3892;
BA_ "SPN" SG_ 2561081086 AuxiliaryIO76 3899;
BA_ "SPN" SG_ 2561081086 AuxiliaryIO75 3898;
BA_ "SPN" SG_ 2561081086 AuxiliaryIO74 3897;
BA_ "SPN" SG_ 2561081086 AuxiliaryIO73 3896;
BA_ "SPN" SG_ 2561081086 AuxiliaryIO80 3903;
BA_ "SPN" SG_ 2561081086 AuxiliaryIO79 3902;
BA_ "SPN" SG_ 2561081086 AuxiliaryIO78 3901;
BA_ "SPN" SG_ 2561081086 AuxiliaryIO77 3900;
BA_ "SPN" SG_ 2561146622 AuxiliaryIO20 3843;
BA_ "SPN" SG_ 2561146622 AuxiliaryIO19 3842;
BA_ "SPN" SG_ 2561146622 AuxiliaryIO18 3841;
BA_ "SPN" SG_ 2561146622 AuxiliaryIO17 3840;
BA_ "SPN" SG_ 2561146622 AuxiliaryIO24 3847;
BA_ "SPN" SG_ 2561146622 AuxiliaryIO23 3846;
BA_ "SPN" SG_ 2561146622 AuxiliaryIO22 3845;
BA_ "SPN" SG_ 2561146622 AuxiliaryIO21 3844;
BA_ "SPN" SG_ 2561146622 AuxiliaryIO28 3851;
BA_ "SPN" SG_ 2561146622 AuxiliaryIO27 3850;
BA_ "SPN" SG_ 2561146622 AuxiliaryIO26 3849;
BA_ "SPN" SG_ 2561146622 AuxiliaryIO25 3848;
BA_ "SPN" SG_ 2561146622 AuxiliaryIO32 3855;
BA_ "SPN" SG_ 2561146622 AuxiliaryIO31 3854;
BA_ "SPN" SG_ 2561146622 AuxiliaryIO30 3853;
BA_ "SPN" SG_ 2561146622 AuxiliaryIO29 3852;
BA_ "SPN" SG_ 2561146622 AuxiliaryIO36 3859;
BA_ "SPN" SG_ 2561146622 AuxiliaryIO35 3858;
BA_ "SPN" SG_ 2561146622 AuxiliaryIO34 3857;
BA_ "SPN" SG_ 2561146622 AuxiliaryIO33 3856;
BA_ "SPN" SG_ 2561146622 AuxiliaryIO40 3863;
BA_ "SPN" SG_ 2561146622 AuxiliaryIO39 3862;
BA_ "SPN" SG_ 2561146622 AuxiliaryIO38 3861;
BA_ "SPN" SG_ 2561146622 AuxiliaryIO37 3860;
BA_ "SPN" SG_ 2561146622 AuxiliaryIO44 3867;
BA_ "SPN" SG_ 2561146622 AuxiliaryIO43 3866;
BA_ "SPN" SG_ 2561146622 AuxiliaryIO42 3865;
BA_ "SPN" SG_ 2561146622 AuxiliaryIO41 3864;
BA_ "SPN" SG_ 2561146622 AuxiliaryIO48 3871;
BA_ "SPN" SG_ 2561146622 AuxiliaryIO47 3870;
BA_ "SPN" SG_ 2561146622 AuxiliaryIO46 3869;
BA_ "SPN" SG_ 2561146622 AuxiliaryIO45 3868;
BA_ "SPN" SG_ 2561212158 TextDisplayInstructions 3613;
BA_ "SPN" SG_ 2561212158 TextDisplayIndex 3614;
BA_ "SPN" SG_ 2561212158 TextDisplayCharacter 3615;
BA_ "SPN" SG_ 2561277694 LaneDepartureWarningEnableCmd 3564;
BA_ "SPN" SG_ 2561277694 CurrentRegion 8133;
BA_ "SPN" SG_ 2561277694 CurrentSubRegion 8134;
BA_ "SPN" SG_ 2561605374 TireLocation 3192;
BA_ "SPN" SG_ 2561605374 ReferenceTirePressureSetting 3193;
BA_ "SPN" SG_ 2562850558 DistTravelledWhileMILIsActvtd 3069;
BA_ "SPN" SG_ 2562850558 DistSinceDiagTroubleCodesClred 3294;
BA_ "SPN" SG_ 2562850558 MinutesAccmltdWhileMILActivated 3295;
BA_ "SPN" SG_ 2562850558 TimeSinceDiagTroubleCodesClred 3296;
BA_ "SPN" SG_ 2562916094 EngineIgnitionCycleCounter 3048;
BA_ "SPN" SG_ 2562916094 OBDMonitoringConditionsEnCntred 3049;
BA_ "SPN" SG_ 2562916094 SPNOfApplicableSystemMonitor 3066;
BA_ "SPN" SG_ 2562916094 ApplicableSystemMonitorNumerator 3067;
BA_ "SPN" SG_ 2562916094 ApplicableSysMonitorDenominator 3068;
BA_ "SPN" SG_ 2562981630 DM22CtrlBytIndivDTCClrRstCtrlByt 3034;
BA_ "SPN" SG_ 2562981630 DM22CtrlBytSpcIndictrIndivDTCClr 3035;
BA_ "SPN" SG_ 2562981630 DM22SPN 3036;
BA_ "SPN" SG_ 2562981630 DM22FMI 3037;
BA_ "SPN" SG_ 2563374846 ParameterGroupNumber 2574;
BA_ "SPN" SG_ 2563374846 UseTransferMode 2575;
BA_ "SPN" SG_ 2563440382 PGNOfRequestedInformation 2552;
BA_ "SPN" SG_ 2563440382 LengthOfDataForTheReportedPGN 2553;
BA_ "SPN" SG_ 2563440382 ControllerApplicationIdentity 2554;
BA_ "SPN" SG_ 2563768062 EngSpeedLimitRequestMinimumCntns 1784;
BA_ "SPN" SG_ 2563768062 EngSpeedLimitRequestMaximumCntns 1785;
BA_ "SPN" SG_ 2563768062 EngTorqueLmtRequestMinimumCntns 1786;
BA_ "SPN" SG_ 2563768062 EngTorqueLmtRequestMaximumCntns 1787;
BA_ "SPN" SG_ 2563768062 MinCntnsRetarderSpeedLmtRequest 1788;
BA_ "SPN" SG_ 2563768062 MaxCntnsRetarderSpeedLmtRequest 1789;
BA_ "SPN" SG_ 2563768062 MinCntnsRetarderTorqueLmtRequest 1790;
BA_ "SPN" SG_ 2563768062 MaxCntnsRetarderTorqueLmtRequest 1791;
BA_ "SPN" SG_ 2563833598 IlluminationBrightnessPercent 1487;
BA_ "SPN" SG_ 2563833598 SwBcklghtIllmntnBRghtnessPrcnt 5532;
BA_ "SPN" SG_ 2563833598 SwIndiIllmntnBRghtnessPrcnt 6820;
BA_ "SPN" SG_ 2362572542 LevelPresetFrontAxleLeft 1732;
BA_ "SPN" SG_ 2362572542 LevelPresetFrontAxleRight 1757;
BA_ "SPN" SG_ 2362572542 LevelPresetRearAxleLeft 1758;
BA_ "SPN" SG_ 2362572542 LevelPresetRearAxleRight 1735;
BA_ "SPN" SG_ 2362638078 AutomaticTractionHelp 2984;
BA_ "SPN" SG_ 2362638078 KneelingRequestLeftSide 1749;
BA_ "SPN" SG_ 2362638078 KneelingRequestRightSide 1748;
BA_ "SPN" SG_ 2362638078 KneelingControlModeRequest 1747;
BA_ "SPN" SG_ 2362638078 NominalLevelRequestFrontAxle 1751;
BA_ "SPN" SG_ 2362638078 NominalLevelRequestRearAxle 1750;
BA_ "SPN" SG_ 2362638078 LevelControlModeRequest 1753;
BA_ "SPN" SG_ 2362638078 LiftAxle1PositionCommand 1752;
BA_ "SPN" SG_ 2362638078 LiftAxle2PositionCommand 1828;
BA_ "SPN" SG_ 2362638078 DamperStiffnessRequestFrontAxle 1718;
BA_ "SPN" SG_ 2362638078 DamperStiffnessRequestRearAxle 1719;
BA_ "SPN" SG_ 2362638078 DamperStiffnessRequestLiftTagAxl 1720;
BA_ "SPN" SG_ 2362638078 KneelingCommandFrontAxle 1830;
BA_ "SPN" SG_ 2362638078 KneelingCommandRearAxle 1829;
BA_ "SPN" SG_ 2362638078 ProhibitAirSuspensionControl 3215;
BA_ "SPN" SG_ 2362638078 AllowLevelControlDuringBrkngCmd 5293;
BA_ "SPN" SG_ 2362638078 SpeedDependentLevelCtrlRequest 5295;
BA_ "SPN" SG_ 2362638078 ProhibitAutoAirSuspensionControl 5274;
BA_ "SPN" SG_ 2362638078 MemoryLevelRequest 5433;
BA_ "SPN" SG_ 2564030206 CalibrationVerificationNumber 1634;
BA_ "SPN" SG_ 2564030206 CalibrationIdentification 1635;
BA_ "SPN" SG_ 2564095742 SecurityEntityLength 1596;
BA_ "SPN" SG_ 2564095742 SecurityEntityType 1479;
BA_ "SPN" SG_ 2564095742 DataSecurityParameter 1597;
BA_ "SPN" SG_ 2564161278 AdjustSeconds 1603;
BA_ "SPN" SG_ 2564161278 AdjustMinutes 1604;
BA_ "SPN" SG_ 2564161278 AdjustHours 1605;
BA_ "SPN" SG_ 2564161278 AdjustMonth 1606;
BA_ "SPN" SG_ 2564161278 AdjustDay 1607;
BA_ "SPN" SG_ 2564161278 AdjustYear 1608;
BA_ "SPN" SG_ 2564161278 AdjustLocalMinuteOffset 1609;
BA_ "SPN" SG_ 2564161278 AdjustLocalHourOffset 1610;
BA_ "SPN" SG_ 2564292350 NoOfOccurrencesOfRawBinaryDat 1650;
BA_ "SPN" SG_ 2564357886 LengthNumberAllowed 1649;
BA_ "SPN" SG_ 2564357886 Status 1646;
BA_ "SPN" SG_ 2564357886 ErrorIndicatorEDCParameter 1648;
BA_ "SPN" SG_ 2564357886 EDCPExtension 1647;
BA_ "SPN" SG_ 2564357886 Seed 1599;
BA_ "SPN" SG_ 2564423422 LengthNumberRequested 1640;
BA_ "SPN" SG_ 2564423422 Command 1642;
BA_ "SPN" SG_ 2564423422 PointerType 1641;
BA_ "SPN" SG_ 2564423422 Pointer 1644;
BA_ "SPN" SG_ 2564423422 PointerExtension 1643;
BA_ "SPN" SG_ 2564423422 KeyUser_Level 1645;
BA_ "SPN" SG_ 2631728894 AntithftEncryptnSeedPrsntIndictr 1194;
BA_ "SPN" SG_ 2631728894 AntiTheftPasswordValidIndicator 1195;
BA_ "SPN" SG_ 2631728894 AntiTheftComponentStatusStates 1196;
BA_ "SPN" SG_ 2631728894 AntiTheftModifyPasswordStates 1197;
BA_ "SPN" SG_ 2631728894 AntiTheftRandomNumber 1198;
BA_ "SPN" SG_ 2631794430 AntithftEncryptnIndicatorStates 1199;
BA_ "SPN" SG_ 2631794430 AntiTheftDesiredExitModeStates 1200;
BA_ "SPN" SG_ 2631794430 AntiTheftCommandStates 1201;
BA_ "SPN" SG_ 2631794430 AntiTheftPasswordRepresentation 1202;
BA_ "SPN" SG_ 2631859966 TripGroup1 988;
BA_ "SPN" SG_ 2631859966 TripGroup2Proprietary 989;
BA_ "SPN" SG_ 2631859966 ServiceComponentIdentification 1584;
BA_ "SPN" SG_ 2631859966 EngineBuildHoursReset 1211;
BA_ "SPN" SG_ 2631859966 SteeringStraightAheadPosReset 3600;
BA_ "SPN" SG_ 2631859966 EngSparkPlugSecVltgTrackingRst 6218;
BA_ "SPN" SG_ 2631859966 EngIgnitionCtrlMaintenanceHrsRst 6219;
BA_ "SPN" SG_ 2631859966 BinLiftCountReset 6898;
BA_ "SPN" SG_ 2631859966 TireConfigurationInformation 6985;
BA_ "SPN" SG_ 2631859966 TireSensorInformation 6986;
BA_ "SPN" SG_ 2564816638 J1939Network1_PrmryVhclNetwork 639;
BA_ "SPN" SG_ 2564816638 J1922 622;
BA_ "SPN" SG_ 2564816638 J1587 608;
BA_ "SPN" SG_ 2564816638 CurrentDataLink 1230;
BA_ "SPN" SG_ 2564816638 Other_ManufacturerSpecifiedPort 1234;
BA_ "SPN" SG_ 2564816638 J1850 1233;
BA_ "SPN" SG_ 2564816638 ISO9141 1232;
BA_ "SPN" SG_ 2564816638 J1939Network2 1231;
BA_ "SPN" SG_ 2564816638 J1939Network4 1668;
BA_ "SPN" SG_ 2564816638 ProprietaryNetwork2 5588;
BA_ "SPN" SG_ 2564816638 ProprietaryNetwork1 625;
BA_ "SPN" SG_ 2564816638 J1939Network3 1235;
BA_ "SPN" SG_ 2564816638 SuspendSignal 2618;
BA_ "SPN" SG_ 2564816638 HoldSignal 1236;
BA_ "SPN" SG_ 2564816638 SuspendDuration 2619;
BA_ "SPN" SG_ 2564882174 EngineFan1RequestedPercentSpeed 986;
BA_ "SPN" SG_ 2564882174 CabInteriorTemperatureCommand 1691;
BA_ "SPN" SG_ 2564882174 AuxHeaterCoolantPumpRequest 1684;
BA_ "SPN" SG_ 2564882174 BatteryMainSwitchHoldRequest 1682;
BA_ "SPN" SG_ 2564882174 OperatorSeatDirectionSwitch 1714;
BA_ "SPN" SG_ 2564882174 SeatBeltSwitch 1856;
BA_ "SPN" SG_ 2564882174 ParkBrakeCommand 5630;
BA_ "SPN" SG_ 2564882174 VehicleLmtngSpdGvrnrDecrementSw 1655;
BA_ "SPN" SG_ 2564882174 VehicleLmtngSpdGvrnrIncrementSw 1654;
BA_ "SPN" SG_ 2564882174 VehicleLmtngSpeedGvrnrEnblSwitch 1653;
BA_ "SPN" SG_ 2564882174 AftrtrtmntRegenInhbtSwitch 3695;
BA_ "SPN" SG_ 2564882174 AftrtrtmntRegenForceSwitch 3696;
BA_ "SPN" SG_ 2564882174 AutoGearShiftingEnableSwitch 1666;
BA_ "SPN" SG_ 2564882174 EngineAutomaticStartEnableSwitch 1656;
BA_ "SPN" SG_ 2564882174 AuxiliaryHeaterModeRequest 1683;
BA_ "SPN" SG_ 2564882174 RequestEngineZoneHeating 1685;
BA_ "SPN" SG_ 2564882174 RequestCabZoneHeating 1686;
BA_ "SPN" SG_ 2564882174 SelectedMaximumVehicleSpeedLimit 2596;
BA_ "SPN" SG_ 2565078782 TestIdentifier 1224;
BA_ "SPN" SG_ 2565078782 SPNIdentifyingComponentSystem 4148;
BA_ "SPN" SG_ 2565078782 FMIIdentifyingComponentSyspcTest 4149;
BA_ "SPN" SG_ 2565406462 GroupFunctionValue0 2542;
BA_ "SPN" SG_ 2565406462 ParameterGroupNumber0 2543;
BA_ "SPN" SG_ 2565406462 GroupFunctionValue1 2544;
BA_ "SPN" SG_ 2565406462 ParameterGroupNumber1 2545;
BA_ "SPN" SG_ 2565406462 GroupFunctionValue2 2546;
BA_ "SPN" SG_ 2565406462 ParameterGroupNumber2 2547;
BA_ "SPN" SG_ 2565406462 GroupFunctionValue3 2548;
BA_ "SPN" SG_ 2565406462 ParameterGroupNumber3 2549;
BA_ "SPN" SG_ 2565537534 ParameterGroupNumber 2540;
BA_ "SPN" SG_ 2565603070 SequenceNumber 2572;
BA_ "SPN" SG_ 2565603070 PacketizedData 2573;
BA_ "SPN" SG_ 2565668606 TotalMessageSize16 2557;
BA_ "SPN" SG_ 2565668606 TotalNumberOfPackets16 2558;
BA_ "SPN" SG_ 2565668606 MaximumNumberOfPackets 2559;
BA_ "SPN" SG_ 2565668606 PGNOfThePacketedMessage16 2560;
BA_ "SPN" SG_ 2565668606 NumberOfPacketsThatCanBeSent 2561;
BA_ "SPN" SG_ 2565668606 NextPacketNumberToBeSent 2562;
BA_ "SPN" SG_ 2565668606 PGNOfThePacketedMessage17 2563;
BA_ "SPN" SG_ 2565668606 TotalMessageSize19 2564;
BA_ "SPN" SG_ 2565668606 TotalNumberOfPackets19 2565;
BA_ "SPN" SG_ 2565668606 PGNOfThePacketedMessage19 2566;
BA_ "SPN" SG_ 2565668606 TotalMessageSize32 2567;
BA_ "SPN" SG_ 2565668606 TotalNumberOfPackets32 2568;
BA_ "SPN" SG_ 2565668606 PGNOfThePacketedMessage32 2569;
BA_ "SPN" SG_ 2565668606 ConnectionAbortReason 2570;
BA_ "SPN" SG_ 2565668606 ParameterGrpNoOfPacketedMessage 2571;
BA_ "SPN" SG_ 2565799678 NAMEOfControllerApplication 2848;
BA_ "SPN" SG_ 2565865726 RetarderTorqueMode 900;
BA_ "SPN" SG_ 2565865726 RetarderEnableBrakeAssistSwitch 571;
BA_ "SPN" SG_ 2565865726 RetarderEnableShiftAssistSwitch 572;
BA_ "SPN" SG_ 2565865726 ActualRetarderPercentTorque 520;
BA_ "SPN" SG_ 2565865726 IntendedRetarderPercentTorque 1085;
BA_ "SPN" SG_ 2565865726 EngineCoolantLoadIncrease 1082;
BA_ "SPN" SG_ 2565865726 RetarderRequestingBrakeLight 1667;
BA_ "SPN" SG_ 2565865726 RetarderRoadSpeedLimitSwitch 4233;
BA_ "SPN" SG_ 2565865726 RetarderRoadSpeedExceededStatus 4234;
BA_ "SPN" SG_ 2565865726 SrcAddrOfCtrllingDevForRtrdrCtrl 1480;
BA_ "SPN" SG_ 2565865726 DriversDmndRetarderPercentTorque 1715;
BA_ "SPN" SG_ 2565865726 RetarderSelection_NonEngine 1716;
BA_ "SPN" SG_ 2565865726 ActlMaxAvailRetarderPrcntTorque 1717;
BA_ "SPN" SG_ 2565865982 ASREngineControlActive 561;
BA_ "SPN" SG_ 2565865982 ASRBrakeControlActive 562;
BA_ "SPN" SG_ 2565865982 AntiLockBrakingActive 563;
BA_ "SPN" SG_ 2565865982 EBSBrakeSwitch 1121;
BA_ "SPN" SG_ 2565865982 BrakePedalPosition 521;
BA_ "SPN" SG_ 2565865982 ABSOffRoadSwitch 575;
BA_ "SPN" SG_ 2565865982 ASROffRoadSwitch 576;
BA_ "SPN" SG_ 2565865982 ASRHillHolderSwitch 577;
BA_ "SPN" SG_ 2565865982 TractionControlOverrideSwitch 1238;
BA_ "SPN" SG_ 2565865982 AcceleratorInterlockSwitch 972;
BA_ "SPN" SG_ 2565865982 EngineDerateSwitch 971;
BA_ "SPN" SG_ 2565865982 EngineAuxiliaryShutdownSwitch 970;
BA_ "SPN" SG_ 2565865982 RemoteAcceleratorEnableSwitch 969;
BA_ "SPN" SG_ 2565865982 EngineRetarderSelection 973;
BA_ "SPN" SG_ 2565865982 ABSFullyOperational 1243;
BA_ "SPN" SG_ 2565865982 EBSRedWarningSignal 1439;
BA_ "SPN" SG_ 2565865982 ABSEBSAmberWarningSignal 1438;
BA_ "SPN" SG_ 2565865982 ATCASRInformationSignal 1793;
BA_ "SPN" SG_ 2565865982 SrcAddrOfCtrllingDevForBrkCtrl 1481;
BA_ "SPN" SG_ 2565865982 RailroadModeSwitch 7941;
BA_ "SPN" SG_ 2565865982 HaltBrakeSwitch 2911;
BA_ "SPN" SG_ 2565865982 TrailerABSStatus 1836;
BA_ "SPN" SG_ 2565865982 TractorMntdTrailerABSWarningSig 1792;
BA_ "SPN" SG_ 2364539646 TransmissionDrivelineEngaged 560;
BA_ "SPN" SG_ 2364539646 TransmissionTrqCnvLockupEngaged 573;
BA_ "SPN" SG_ 2364539646 TransmissionShiftInProcess 574;
BA_ "SPN" SG_ 2364539646 TrnsmTrqCnvLockupTrnstionInPrcss 4816;
BA_ "SPN" SG_ 2364539646 TransmissionOutputShaftSpeed 191;
BA_ "SPN" SG_ 2364539646 PercentClutchSlip 522;
BA_ "SPN" SG_ 2364539646 EngineMomentaryOverspeedEnable 606;
BA_ "SPN" SG_ 2364539646 ProgressiveShiftDisable 607;
BA_ "SPN" SG_ 2364539646 MomentaryEngineMaximumPowerEnbl 5015;
BA_ "SPN" SG_ 2364539646 TransmissionInputShaftSpeed 161;
BA_ "SPN" SG_ 2364539646 SrcAddrOfCtrllingDevForTrnsmCtrl 1482;
BA_ "SPN" SG_ 2364539902 AcceleratorPedal1LowIdleSwitch 558;
BA_ "SPN" SG_ 2364539902 AcceleratorPedalKickdownSwitch 559;
BA_ "SPN" SG_ 2364539902 RoadSpeedLimitStatus 1437;
BA_ "SPN" SG_ 2364539902 AcceleratorPedal2LowIdleSwitch 2970;
BA_ "SPN" SG_ 2364539902 AcceleratorPedalPosition1 91;
BA_ "SPN" SG_ 2364539902 EnginePercentLoadAtCurrentSpeed 92;
BA_ "SPN" SG_ 2364539902 RemoteAcceleratorPedalPosition 974;
BA_ "SPN" SG_ 2364539902 AcceleratorPedalPosition2 29;
BA_ "SPN" SG_ 2364539902 VehicleAccltnRateLimitStatus 2979;
BA_ "SPN" SG_ 2364539902 MomentaryEngMaxPowerEnblFdbck 5021;
BA_ "SPN" SG_ 2364539902 DPFThermalManagementActive 5399;
BA_ "SPN" SG_ 2364539902 SCRThermalManagementActive 5400;
BA_ "SPN" SG_ 2364539902 ActlMaximumAvailEngPercentTorque 3357;
BA_ "SPN" SG_ 2364539902 EstimatedPumpingPercentTorque 5398;
BA_ "SPN" SG_ 2364540158 EngineTorqueMode 899;
BA_ "SPN" SG_ 2364540158 ActualEnginePercentTorqueFract 4154;
BA_ "SPN" SG_ 2364540158 DriversDemandEnginePercentTorque 512;
BA_ "SPN" SG_ 2364540158 ActualEnginePercentTorque 513;
BA_ "SPN" SG_ 2364540158 EngineSpeed 190;
BA_ "SPN" SG_ 2364540158 SrcAddrOfCtrllingDevForEngCtrl 1483;
BA_ "SPN" SG_ 2364540158 EngineStarterMode 1675;
BA_ "SPN" SG_ 2364540158 EngineDemandPercentTorque 2432;
BA_ "SPN" SG_ 2565867006 TransmissionSelectedGear 524;
BA_ "SPN" SG_ 2565867006 TransmissionActualGearRatio 526;
BA_ "SPN" SG_ 2565867006 TransmissionCurrentGear 523;
BA_ "SPN" SG_ 2565867006 TransmissionRequestedRange 162;
BA_ "SPN" SG_ 2565867006 TransmissionCurrentRange 163;
BA_ "SPN" SG_ 2565867262 Location 927;
BA_ "SPN" SG_ 2565867262 DifferentialLockStateFrontAxle1 567;
BA_ "SPN" SG_ 2565867262 DifferentialLockStateFrontAxle2 568;
BA_ "SPN" SG_ 2565867262 DifferentialLockStateRearAxle1 569;
BA_ "SPN" SG_ 2565867262 DifferentialLockStateRearAxle2 570;
BA_ "SPN" SG_ 2565867262 DifferentialLockStateCentral 564;
BA_ "SPN" SG_ 2565867262 DiffLockStateCentralFront 565;
BA_ "SPN" SG_ 2565867262 DifferentialLockStateCentralRear 566;
BA_ "SPN" SG_ 2565867262 DifferentialLockStateRearAxle3 7716;
BA_ "SPN" SG_ 2565867262 FrontAxleGroupEngagementStatus 3819;
BA_ "SPN" SG_ 2565867262 RearAxleGroupEngagementStatus 3820;
BA_ "SPN" SG_ 2431649790 LaneDepartureLeft 3565;
BA_ "SPN" SG_ 2431649790 LaneDepartureRight 3566;
BA_ "SPN" SG_ 2431649790 LaneDepartureImminent_RightSide 1701;
BA_ "SPN" SG_ 2431649790 LaneDepartureImminent_LeftSide 1700;
BA_ "SPN" SG_ 2431649790 DriverAlertnessWarning 7473;
BA_ "SPN" SG_ 2431649790 RghtSdeLaneDepartrOptclWrngCmd 8135;
BA_ "SPN" SG_ 2431649790 LftSdeLaneDepartrOptclWarningCmd 8136;
BA_ "SPN" SG_ 2431649790 RghtSdeLaneDepartrAcstclWrngCmd 8137;
BA_ "SPN" SG_ 2431649790 LftSdeLaneDepartrAcstclWrngCmd 8138;
BA_ "SPN" SG_ 2565867774 HydraulicPressure 1762;
BA_ "SPN" SG_ 2565867774 EngHydrPressureGvrnrModeIndictr 1763;
BA_ "SPN" SG_ 2565867774 EngHydraulicPressureGvrnrSwitch 1764;
BA_ "SPN" SG_ 2565867774 FireApparatusPumpEngagement 2599;
BA_ "SPN" SG_ 2565867774 FireApparatusOkayToPumpInterlock 6702;
BA_ "SPN" SG_ 2565867774 HydraulicIntakePressure 6707;
BA_ "SPN" SG_ 2565867774 HydrDischargePressureSetPoint 6708;
BA_ "SPN" SG_ 2565867774 HydraulicPressureGvrnrIdleSwitch 6705;
BA_ "SPN" SG_ 2565867774 HydrPressureGvrnrDecreaseSwitch 6704;
BA_ "SPN" SG_ 2565867774 HydrPressureGvrnrIncreaseSwitch 6703;
BA_ "SPN" SG_ 2565867774 HydrPressureGvrnrPresetSwitch 6706;
BA_ "SPN" SG_ 2565868030 SteeringWheelAngle 1807;
BA_ "SPN" SG_ 2565868030 SteeringWheelTurnCounter 1811;
BA_ "SPN" SG_ 2565868030 SteeringWheelAngleSensorType 1812;
BA_ "SPN" SG_ 2565868030 YawRate 1808;
BA_ "SPN" SG_ 2565868030 LateralAcceleration 1809;
BA_ "SPN" SG_ 2565868030 LongitudinalAcceleration 1810;
BA_ "SPN" SG_ 2364541694 EngExhstGasRecirc1MassFlwRate 2659;
BA_ "SPN" SG_ 2364541694 EngineIntakeAirMassFlowRate 132;
BA_ "SPN" SG_ 2364541694 EngExhstGasRecirc2MassFlwRate 5257;
BA_ "SPN" SG_ 2565868542 ActualInnerWheelSteeringAngle 2927;
BA_ "SPN" SG_ 2565868542 AxleLocation 2928;
BA_ "SPN" SG_ 2565868542 StatusOfSteeringAxle 2923;
BA_ "SPN" SG_ 2565868542 SteerableLiftAxleLoweringInhibit 2922;
BA_ "SPN" SG_ 2565868542 SteeringType 2924;
BA_ "SPN" SG_ 2565868542 TypeOfSteeringForces 2925;
BA_ "SPN" SG_ 2565868542 TypeOfSteeringTransmission 2926;
BA_ "SPN" SG_ 2364542206 TransmissionTorqueConverterRatio 3030;
BA_ "SPN" SG_ 2364542206 TransmissionCltchCnvInputSpeed 5052;
BA_ "SPN" SG_ 2364542462 BladeControlModeSwitch 3156;
BA_ "SPN" SG_ 2364542462 DesiredGradeOffsetSwitch 3157;
BA_ "SPN" SG_ 2364542462 BladeAutoModeCommand 3158;
BA_ "SPN" SG_ 2364542462 LeftBldCtrlModeOperatorControl 3334;
BA_ "SPN" SG_ 2364542462 RightBldCtrlModeOperatorControl 3335;
BA_ "SPN" SG_ 2364542462 LeftDesiredBldOffsetOperatorCtrl 3336;
BA_ "SPN" SG_ 2364542462 RightDsrdBldOffsetOperatorCtrl 3337;
BA_ "SPN" SG_ 2364542462 SideShiftBldCtrlModeOperatorCtrl 3338;
BA_ "SPN" SG_ 2364542462 SideShiftDsrdBldOffstOprtrCtrl 3339;
BA_ "SPN" SG_ 2364542462 SetElevationSensor1RefElevation 5405;
BA_ "SPN" SG_ 2364542462 SetElevationSensor2RefElevation 5406;
BA_ "SPN" SG_ 2565869310 Aft1SlctiveCtlytcRedIntkNOx 3216;
BA_ "SPN" SG_ 2565869310 Aftertreatment1IntakePercentO2 3217;
BA_ "SPN" SG_ 2565869310 Aftrtrtmnt1IntkGasSensorPwrInRng 3218;
BA_ "SPN" SG_ 2565869310 Aftrtrtmnt1IntkGasSnsrAtTemp 3219;
BA_ "SPN" SG_ 2565869310 Aft1SlctiveCtlytcRedIntkNOxRdngS 3220;
BA_ "SPN" SG_ 2565869310 Aft1IntkWdRngPrcntO2RdngStable 3221;
BA_ "SPN" SG_ 2565869310 Aft1IntkGasSnsrHtrPrelimFMI 3222;
BA_ "SPN" SG_ 2565869310 Aftrtrtmnt1IntkGasSensorHtrCtrl 3223;
BA_ "SPN" SG_ 2565869310 Aft1SlctiveCtlytcRedIntkNOxSnsrP 3224;
BA_ "SPN" SG_ 2565869310 Aft1IntkNOxSnsrSelfDiagnssStat 5714;
BA_ "SPN" SG_ 2565869310 Aftrtrtmnt1IntkO2SensorPrelimFMI 3225;

BA_ "SigType" SG_ 2558525182 TireSensorIdentificationNumber 3;
BA_ "SigType" SG_ 2561212158 TextDisplayCharacter 3;
BA_ "SigType" SG_ 2561277694 CurrentRegion 3;
BA_ "SigType" SG_ 2561277694 CurrentSubRegion 3;
BA_ "SigType" SG_ 2564030206 CalibrationIdentification 3;
BA_ "SigType" SG_ 2631728894 AntiTheftRandomNumber 3;
BA_ "SigType" SG_ 2631794430 AntiTheftPasswordRepresentation 3;
BA_ "SigType" SG_ 2565867006 TransmissionRequestedRange 3;
BA_ "SigType" SG_ 2565867006 TransmissionCurrentRange 3;

VAL_ 2565406462 ACKM_Mux 0 "ACK" 1 "NACK" 2 "NACK_AD" 3 "NACK_Busy" ;
VAL_ 2565668606 TPCM_Mux 16 "RTS" 17 "CTS" 19 "EoM_ACK" 32 "BAM" 255 "ConnAbort" ;
VAL_ 2348875518 EngineOverrideControlMode 0 "Override disabled" 1 "Speed control" 2 "Torque control" 3 "Speed/torque limit control" ;
VAL_ 2348875518 EngRequestedSpeedCtrlConditions 0 "Transient Optimized for driveline disengaged and non-lockup conditions" 1 "Stability Optimized for driveline disengaged and non-lockup conditions" 2 "Stability Optimized for driveline engaged and/or in lockup condition 1 " 3 "Stability Optimized for driveline engaged and/or in lockup condition 2" ;
VAL_ 2348875518 OverrideControlModePriority 0 "Highest priority" 1 "High priority" 2 "Medium priority" 3 "Low priority" ;
VAL_ 2348875518 TSC1TransmissionRate 0 "1000 ms transmission rate" 1 "750 ms transmission rate" 2 "500 ms transmission rate" 3 "250 ms transmission rate" 4 "100 ms transmission rate" 5 "50 ms transmission rate" 6 "20 ms transmission rate" 7 "Use standard" ;
VAL_ 2348875518 TSC1ControlPurpose 0 "P1 : Accelerator Pedal/Operator Selection" 1 "P2 : Cruise Control" 2 "P3 : PTO Governor" 3 "P4 : Road Speed Governor" 4 "P5 : Engine Protection" 31 "P32 : Temporary Power Train Control" ;
VAL_ 2348875518 EngineRequestedTorque 0 "+0.000%" 1 "+0.125%" 2 "+0.250%" 3 "+0.375%" 4 "+0.500%" 5 "+0.625%" 6 "+0.750%" 7 "+0.875%" ;
VAL_ 2348941054 TransmissionGearShiftInhbtRq 0 "Gear shifts are allowed" 1 "Gear shifts are inhibited" 2 "Reserved" 3 "Take no action" ;
VAL_ 2348941054 TrnsmTrqCnvLockupDisableRq 0 "Allow torque converter lockup" 1 "Disable torque converter lockup" 2 "Request torque converter lockup" 3 "Take no action" ;
VAL_ 2348941054 DisengageDrivelineRequest 0 "Allow driveline engagement" 1 "Disengage driveline" 2 "Reserved" 3 "Take no action" ;
VAL_ 2348941054 TrnsmReverseGearShftInhbtRq 0 "Allow shifts into Reverse gear" 1 "Inhibit shifts into Reverse gear" 2 "Reserved " 3 "Take no action" ;
VAL_ 2348941054 TransmissionRequestedGear 253 "Hold current gear" 252 "Forward Drive Position" 251 "'Park' position" 250 "Forward 'Low' position" 249 "Upshift 1 gear from current position" 248 "Upshift 2 gears from current position" 247 "Downshift 1 gear from current position" 246 "Downshift 2 gears from current position" 245 "D-1: 1st forward selector position" 244 "D-2: 2nd forward selector position" 243 "D-3: 3rd forward selector position" 242 "D-4: 4th forward selector position" 241 "D-5: 5th forward selector position" 240 "D-6: 6th forward selector position" 239 "D-7: 7th forward selector position" 238 "Between two shift selector positions" 237 "Between two reverse shift selector positions" 236 "Between two forward shift selector positions" 235 "Between D-7 and D-6 shift selector positions" 234 "Between D-6 and D-5 shift selector positions" 233 "Between D-5 and D-4 shift selector positions" 232 "Between D-4 and D-3 shift selector positions" 231 "Between D-3 and D-2 shift selector positions" 230 "Between D-2 and D-1 shift selector positions" 229 "Between D-1 and 'Drive' shift selector positions"
228 "Between 'Drive' and 'Neutral' shift selector positions" 227 "Between 'Neutral' and 'Reverse' shift selector positions" 226 "Between 'Reverse' and 'Park' shift selector positions" 225 "Press of momentary button to reselect current position" 224 "Position unknown and/or no buttons pressed" 223 "Reverse Selector Position" 60 "Reserved" ;
VAL_ 2348941054 DisengiffLockRequestFrontAxl1 0 "Engage differential lock" 1 "Disengage differential lock" 2 "Reserved" 3 "Take no action" ;
VAL_ 2348941054 DisengiffLockRequestFrontAxl2 0 "Engage differential lock" 1 "Disengage differential lock" 2 "Reserved" 3 "Take no action" ;
VAL_ 2348941054 DisengageDiffLockRequestRearAxl1 0 "Engage differential lock" 1 "Disengage differential lock" 2 "Reserved" 3 "Take no action" ;
VAL_ 2348941054 DisengageDiffLockRequestRearAxl2 0 "Engage differential lock" 1 "Disengage differential lock" 2 "Reserved" 3 "Take no action" ;
VAL_ 2348941054 DisengageDiffLockRequestCentral 0 "Engage differential lock" 1 "Disengage differential lock" 2 "Reserved" 3 "Take no action" ;
VAL_ 2348941054 DisengiffLockRequestCentralFront 0 "Engage differential lock" 1 "Disengage differential lock" 2 "Reserved" 3 "Take no action" ;
VAL_ 2348941054 DisengiffLockRequestCentralRear 0 "Engage differential lock" 1 "Disengage differential lock" 2 "Reserved" 3 "Take no action" ;
VAL_ 2348941054 TransmissionLoadRedInhbtRequest 0 "Allow or resume transmission" 1 "Inhibit or abort transmission" 2 "Reserved" 3 "Don't care/take no action" ;
VAL_ 2348941054 TransmissionMode1 0 "Disable" 1 "Enable" 2 "Reserved" 3 "Take no action" ;
VAL_ 2348941054 TransmissionMode2 0 "Disable" 1 "Enable" 2 "Reserved" 3 "Take no action" ;
VAL_ 2348941054 TransmissionMode3 0 "Disable" 1 "Enable" 2 "Reserved" 3 "Take no action" ;
VAL_ 2348941054 TransmissionMode4 0 "Disable" 1 "Enable" 2 "Reserved" 3 "Take no action" ;
VAL_ 2348941054 TransmissionAutoNeutralRequest 0 "No request to shift to Auto-Neutral state" 1 "Request to shift to Auto-Neutral state" 2 "Reserved" 3 "Don't Care / Take No Action" ;
VAL_ 2348941054 TransmissionRequestedLaunchGear 0 "No specific launch gear requested" 1 "Launch the vehicle in 1st gear" 2 "Launch the vehicle in 2nd gear" 3 "Launch the vehicle in 3rd gear" 4 "Launch the vehicle in 4th gear" 5 "Launch the vehicle in 5th gear" 6 "Launch the vehicle in 6th gear" 7 "Launch the vehicle in 7th gear" 8 "Launch the vehicle in 8th gear" 9 "Launch the vehicle in Reverse 1" 10 "Launch the vehicle in Reverse 2" 11 "Launch the vehicle in Reverse 3" 12 "Launch the vehicle in Reverse 4 " 13 "Allow transmission to select the optimum launch gear" 14 "Error" 15 "Not Available" ;
VAL_ 2348941054 TrnsmShftSlctorDisplayMdeSw 0 "Off" 1 "One" 2 "Error" 3 "Not available" ;
VAL_ 2348941054 TransmissionMode5 0 "Disable" 1 "Enable" 2 "Reserved" 3 "Take no action" ;
VAL_ 2348941054 TransmissionMode6 0 "Disable" 1 "Enable" 2 "Reserved" 3 "Take no action" ;
VAL_ 2348941054 TransmissionMode7 0 "Disable" 1 "Enable" 2 "Reserved" 3 "Take no action" ;
VAL_ 2348941054 TransmissionMode8 0 "Disable" 1 "Enable" 2 "Reserved" 3 "Take no action" ;
VAL_ 2349137662 XBREBIMode 0 "No Endurance Brake Integration allowed" 1 "Only Endurance Brakes allowed" 2 "Endurance Brake Integration allowed" 3 "Not defined" ;
VAL_ 2349137662 XBRPriority 0 "Highest priority" 1 "High priority" 2 "Medium priority" 3 "Low priority" ;
VAL_ 2349137662 XBRControlMode 0 "Override disabled" 1 "Acceleration control with addition mode" 2 "Acceleration control with maximum mode" 3 "Not defined" ;
VAL_ 2349465342 StaticRollAngleStatus 0 "Sensor Busy" 1 "Sensor OK" 2 "Sensor Defect" 3 "Sensor Reboots" 4 "Angle Data Invalid" 5 "Reserved" 6 "Error" 7 "Not available" ;
VAL_ 2349530878 CruiseControlDisableCommand 0 "Cruise Control is allowed" 1 "Cruise Control is not allowed" 2 "Reserved" 3 "Don't care/take no action" ;
VAL_ 2349530878 CruiseControlResumeCommand 0 "Cruise Control Resume not Requested" 1 "Cruise Control Resume Requested" 2 "Reserved" 3 "Don't Care/take no action" ;
VAL_ 2349530878 CruiseControlPauseCommand 0 "Cruise Control is allowed" 1 "Cruise Control is not allowed" 2 "Reserved" 3 "Don't care/take no action" ;
VAL_ 2349530878 IdleControlEnableState 0 "Conditions are not met for idle speed request" 1 "Conditions for idle speed request have been met" 2 "Error" 3 "Not available" ;
VAL_ 2349530878 IdleControlRequestActivation 0 "Idle speed request is not active" 1 "Idle speed request is active" 2 "Error" 3 "Not available" ;
VAL_ 2349596414 DrvrActtnDmndAdvEmrgncyBrkngSys 0 "deactivation of system" 1 "no deactivation of system" 2 "reserved" 3 "don't care / take no action" ;
VAL_ 2550988542 ReadyForClutchEngagementStatus 0 "Engine Not Ready For Clutch Engagement" 1 "Engine is Ready For Clutch Engagement" 2 "Error" 3 "Not available" ;
VAL_ 2550988542 EngineClutchEngageRequestStatus 0 "Engine does not have an external request" 1 "Engine has an external request" 2 "Error" 3 "Not available" ;
VAL_ 2349727486 TransmissionMode9 0 "Disable" 1 "Enable" 2 "Reserved" 3 "Take no action" ;
VAL_ 2349727486 TransmissionMode10 0 "Disable" 1 "Enable" 2 "Reserved" 3 "Take no action" ;
VAL_ 2350644990 HVES1HighVoltageBusConnectCmd 0 "Open Contactor" 1 "Close Contactor" 2 "Emergency contactor closure request" 3 "Don't care/Take no action" ;
VAL_ 2350644990 HVES1PowerDownCommand 0 "Power-down not requested" 1 "Execute normal power-down" 2 "Execute emergency power-down" 3 "Don't care/Take no action" ;
VAL_ 2350644990 HVES1HghVltgBusActIsolatnTestCmd 0 "Active Isolation Test not requested" 1 "Active Isolation Test request" 2 "Reserved" 3 "Don't care/Take no action" ;
VAL_ 2350644990 HVES1HiVltgBusPassIsolatnTestCmd 0 "Passive Isolation Test not requested" 1 "Passive Isolation Test request" 2 "Reserved" 3 "Don't care/Take no action" ;
VAL_ 2350644990 HVES1CellBalancingCommand 0 "Cell Balancing not requested" 1 "Cell Balancing requested" 2 "Reserved" 3 "Don't care/Take no action" ;
VAL_ 2350644990 HVES1EnableInternalChrgrCommand 0 "Disable charging" 1 "Enable charging" 2 "Reserved" 3 "Not Supported" ;
VAL_ 2350644990 HVES1OperationConsent 0 "Consent revoked" 1 "Consent given" 2 "Error" 3 "Not Available" ;
VAL_ 2350644990 HVES1HiVltgBusHiSdeResistCnnctRq 0 "Connection not Requested" 1 "Connection Requested" 2 "Reserved" 3 "Don't care/take no action" ;
VAL_ 2350644990 HVES1HiVltgBusLoSdeResistCnnctRq 0 "Connection not Requested" 1 "Connection Requested" 2 "Reserved" 3 "Don't care/take no action" ;
VAL_ 2350710526 TransmissionOverrideControlMode 0 "Override disabled" 1 "Speed control" 2 "Torque control" 3 "Speed/torque limit control" ;
VAL_ 2350710526 TrnsmOverrdCtrlMdePriority 0 "Highest priority" 1 "High priority" 2 "Medium priority" 3 "Low priority" ;
VAL_ 2557345534 WellStimuPmpPlungerFiringOrder 0 "Firing order 1-2-3" 1 "Firing order 1-5-2-3-4" 15 "Don't Care / Take no action" ;
VAL_ 2624519934 ReceiveSPNsCommandedPort 0 "Current port" 1 "Port 1" 2 "Port 2" 3 "Port 3" 4 "Port 4" 5 "Port 5" 6 "Port 6" 7 "Port 7" 8 "Port 8" 9 "Port 9" 10 "Port 10" ;
VAL_ 2624519934 ReceiveSPNsTransactionMode 0 "Request Port Transmit Status" 1 "Configure Port Receive State" 2 "Cancel Pending Changes" 3 "Global Revert to Default" 4 "Partial Revert to Default" ;
VAL_ 2624519934 CmdedReceiveSPNRequestedState 0 "SPN reception shall be disabled" 1 "SPN reception shall be enabled" 2 "SAE Reserved" 3 "Not Available" ;
VAL_ 2624716542 TransmitPGNsCommandedPort 0 "Current port" 1 "Port 1" 2 "Port 2" 3 "Port 3" 4 "Port 4" 5 "Port 5" 6 "Port 6" 7 "Port 7" 8 "Port 8" 9 "Port 9" 10 "Port 10" ;
VAL_ 2624716542 TransmitPGNsTransactionMode 0 "Request Port Transmit Status" 1 "Configure Port Transmit State" 2 "Cancel Pending Changes" 3 "Global Revert to Default " 4 "Partial Revert to Default" ;
VAL_ 2624716542 CmdedTransmitPGNRequestedState 0 "PGN shall be disabled for transmit" 1 "PGN shall be enabled for transmit" 2 "SAE Reserved" 3 "Not Available" ;
VAL_ 2557738750 PropulsionMotorCoolntFan3EnblCmd 0 "Accessory Motor Off" 1 "Accessory Motor On Normal/Default Direction" 2 "Accessory Motor On Reverse Direction" 3 "Don't Care/Take no action" ;
VAL_ 2557738750 PropulsionMtrCoolntFn3PowerHold 0 "Power Hold Disabled" 1 "Power Hold Enabled" 2 "Reserved" 3 "Don't Care/Take no action" ;
VAL_ 2557804286 PropulsionMotorCoolntFan2EnblCmd 0 "Accessory Motor Off" 1 "Accessory Motor On Normal/Default Direction" 2 "Accessory Motor On Reverse Direction" 3 "Don't Care/Take no action" ;
VAL_ 2557804286 PropulsionMtrCoolntFn2PowerHold 0 "Power Hold Disabled" 1 "Power Hold Enabled" 2 "Reserved" 3 "Don't Care/Take no action" ;
VAL_ 2557869822 PropulsionMotorCoolntFan1EnblCmd 0 "Accessory Motor Off" 1 "Accessory Motor On Normal/Default Direction" 2 "Accessory Motor On Reverse Direction" 3 "Don't Care/Take no action" ;
VAL_ 2557869822 PropulsionMtrCoolntFn1PowerHold 0 "Power Hold Disabled" 1 "Power Hold Enabled" 2 "Reserved" 3 "Don't Care/Take no action" ;
VAL_ 2557935358 PowerElctrncsCoolntFan3EnableCmd 0 "Accessory Motor Off" 1 "Accessory Motor On Normal/Default Direction" 2 "Accessory Motor On Reverse Direction" 3 "Don't Care/Take no action" ;
VAL_ 2557935358 PowerElctrncsCoolntFan3PowerHold 0 "Power Hold Disabled" 1 "Power Hold Enabled" 2 "Reserved" 3 "Don't Care/Take no action" ;
VAL_ 2558000894 PowerElctrncsCoolntFan2EnableCmd 0 "Accessory Motor Off" 1 "Accessory Motor On Normal/Default Direction" 2 "Accessory Motor On Reverse Direction" 3 "Don't Care/Take no action" ;
VAL_ 2558000894 PowerElctrncsCoolntFan2PowerHold 0 "Power Hold Disabled" 1 "Power Hold Enabled" 2 "Reserved" 3 "Don't Care/Take no action" ;
VAL_ 2558066430 PowerElctrncsCoolntFan1EnableCmd 0 "Accessory Motor Off" 1 "Accessory Motor On Normal/Default Direction" 2 "Accessory Motor On Reverse Direction" 3 "Don't Care/Take no action" ;
VAL_ 2558066430 PowerElctrncsCoolntFan1PowerHold 0 "Power Hold Disabled" 1 "Power Hold Enabled" 2 "Reserved" 3 "Don't Care/Take no action" ;
VAL_ 2558131966 PropulsionMotorOilPumpEnableCmd 0 "Accessory Motor Off" 1 "Accessory Motor On Normal/Default Direction" 2 "Accessory Motor On Reverse Direction" 3 "Don't Care/Take no action" ;
VAL_ 2558131966 PropulsionMotorOilPumpPowerHold 0 "Power Hold Disabled" 1 "Power Hold Enabled" 2 "Reserved" 3 "Don't Care/Take no action" ;
VAL_ 2558197502 PropulsionMotorCoolntPumpEnblCmd 0 "Accessory Motor Off" 1 "Accessory Motor On Normal/Default Direction" 2 "Accessory Motor On Reverse Direction" 3 "Don't Care/Take no action" ;
VAL_ 2558197502 PropulsionMtrCoolntPumpPowerHold 0 "Power Hold Disabled" 1 "Power Hold Enabled" 2 "Reserved" 3 "Don't Care/Take no action" ;
VAL_ 2558263038 PowerElctrncsCoolntPumpEnableCmd 0 "Accessory Motor Off" 1 "Accessory Motor On Normal/Default Direction" 2 "Accessory Motor On Reverse Direction" 3 "Don't Care/Take no action" ;
VAL_ 2558263038 PowerElctrncsCoolntPumpPowerHold 0 "Power Hold Disabled" 1 "Power Hold Enabled" 2 "Reserved" 3 "Don't Care/Take no action" ;
VAL_ 2558394110 ElectrifiedAccssryMotorEnableCmd 0 "Accessory Motor Off" 1 "Accessory Motor On Normal/Default Direction" 2 "Accessory Motor On Reverse Direction" 3 "Don't Care/Take no action" ;
VAL_ 2558394110 ElectrifiedAccssryMotorPowerHold 0 "Power Hold Disabled" 1 "Power Hold Enabled" 2 "Reserved" 3 "Don't Care/Take no action" ;
VAL_ 2558394110 ElectrifiedAccssryMotorInstance1 0 "Command applied to this Accessory Motor Instance" 1 "No Command applied to this Accessory Motor Instance" ;
VAL_ 2558394110 ElectrifiedAccssryMotorInstance2 0 "Command applied to this Accessory Motor Instance" 1 "No Command applied to this Accessory Motor Instance" ;
VAL_ 2558394110 ElectrifiedAccssryMotorInstance3 0 "Command applied to this Accessory Motor Instance" 1 "No Command applied to this Accessory Motor Instance" ;
VAL_ 2558394110 ElectrifiedAccssryMotorInstance4 0 "Command applied to this Accessory Motor Instance" 1 "No Command applied to this Accessory Motor Instance" ;
VAL_ 2558394110 ElectrifiedAccssryMotorInstance5 0 "Command applied to this Accessory Motor Instance" 1 "No Command applied to this Accessory Motor Instance" ;
VAL_ 2558394110 ElectrifiedAccssryMotorInstance6 0 "Command applied to this Accessory Motor Instance" 1 "No Command applied to this Accessory Motor Instance" ;
VAL_ 2558394110 ElectrifiedAccssryMotorInstance7 0 "Command applied to this Accessory Motor Instance" 1 "No Command applied to this Accessory Motor Instance" ;
VAL_ 2558394110 ElectrifiedAccssryMotorInstance8 0 "Command applied to this Accessory Motor Instance" 1 "No Command applied to this Accessory Motor Instance" ;
VAL_ 2558394110 ElectrifiedAccssryMotorInstance9 0 "Command applied to this Accessory Motor Instance" 1 "No Command applied to this Accessory Motor Instance" ;
VAL_ 2558394110 ElectrfdAccssryMotorInstance10 0 "Command applied to this Accessory Motor Instance" 1 "No Command applied to this Accessory Motor Instance" ;
VAL_ 2558394110 ElectrfdAccssryMotorInstance11 0 "Command applied to this Accessory Motor Instance" 1 "No Command applied to this Accessory Motor Instance" ;
VAL_ 2558394110 ElectrfdAccssryMotorInstance12 0 "Command applied to this Accessory Motor Instance" 1 "No Command applied to this Accessory Motor Instance" ;
VAL_ 2558394110 ElectrfdAccssryMotorInstance13 0 "Command applied to this Accessory Motor Instance" 1 "No Command applied to this Accessory Motor Instance" ;
VAL_ 2558394110 ElectrfdAccssryMotorInstance14 0 "Command applied to this Accessory Motor Instance" 1 "No Command applied to this Accessory Motor Instance" ;
VAL_ 2558394110 ElectrfdAccssryMotorInstance15 0 "Command applied to this Accessory Motor Instance" 1 "No Command applied to this Accessory Motor Instance" ;
VAL_ 2558590718 HybridSystemPrtctnOverrdRequest 0 "Not active" 1 "Active" 2 "Reserved" 3 "Don't care / take no action" ;
VAL_ 2558590718 HybridSystemProplsnDisablRequest 0 "Off" 1 "On" 2 "Reserved" 3 "Don't Care / Take No Action" ;
VAL_ 2558590718 HybridSysRegativeBrkngDisablRq 0 "Regenerative braking disable request is not active" 1 "Regenerative braking disable request is active" 2 "Reserved" 3 "Don't care / take no action" ;
VAL_ 2558590718 HybridSystemShutdownCommand 0 "Off" 1 "On" 2 "Reserved" 3 "Don't Care / Take No Action" ;
VAL_ 2558590718 OperatorVehicleModeRequest 0 "Off" 1 "Low Voltage Accessory" 2 "Stored Energy Source Active" 3 "Propulsion Active" 14 "Error" 15 "Not Available" ;
VAL_ 2558590718 HybridPropulsionModeRequest 0 "No mode requested" 1 "Stored Energy Source Sustaining" 2 "Stored Energy Source Increasing" 3 "Stored Energy Source Depleting" 4 "Stored Energy Source Offline" 5 "Stored Energy Source Only" 14 "Error" 15 "Not Available" ;
VAL_ 2558590718 ExternalEnergySourceConnectnDmnd 0 "No Connection" 1 "Perform Connection 1 Verification" 2 "Energy Drain or Source Connection 1" 3 "Energy Source Connection 1" 4 "Energy Drain Connection 1" 5 "Perform Connection 2 Verification" 6 "Energy Drain or Source Connection 2" 7 "Energy Source Connection 2" 8 "Energy Drain Connection 2" 14 "Disconnect Request" 15 "No Request/Take no action" ;
VAL_ 2558656254 AftrtrtmntThermalMangmntInhbtRq 0 "Do not inhibit" 1 "Inhibit" 2 "Reserved for SAE assignment" 3 "Not Available" ;
VAL_ 2558656254 RqToPermitDEFHydrStiffnessChk 0 "no request" 1 "request to permit DEF hydraulic stiffness check" 2 "reserved" 3 "don't care" ;
VAL_ 2558656254 RequestToPermitDEFDsngTestInject 0 "no request" 1 "request to permit DEF Dosing Test Injection" 2 "urgent request to permit DEF Dosing Test Injection" 7 "don't care" ;
VAL_ 2558656254 AftertreatmentSystemEnableStatus 0 "Aftertreatment System is Disabled" 1 "Aftertreatment System is Enabled" 2 "Error" 3 "Not available" ;
VAL_ 2558656254 AftDslExhstFldDoserRdyStat 0 "Aftertreatment Not Ready to Dose" 1 "Aftertreatment Ready to Dose" 2 "Error" 3 "Not available" ;
VAL_ 2558721790 TireSensorEnableSetting 0 "Off / Isolate / Disable" 1 "On / Enable" 2 "Reserved / Not Defined" 3 "Don't Care / Take No Action" ;
VAL_ 2558787326 PayloadClbrtnSetPointCommand 0 "Zero Point" 1 "Calibration Reference Point 1" 2 "Calibration Reference Point 2" 3 "Calibration Reference Point 3" 4 "Calibration Reference Point 4" 5 "Calibration Reference Point 5" 6 "Calibration Reference Point 6" 7 "Calibration Reference Point 7" 8 "Calibration Reference Point 8" 9 "Calibration Reference Point 9" 10 "End Point" 11 "Correction Point" 12 "Reset Calibration" 13 "Reserved" 14 "Error" 15 "Not Available" ;
VAL_ 2558852862 Aft1PrticulateSnsrShtdwnRq 0 "Shutdown request not active" 1 "Shutdown request active" 2 "SAE reserved" 3 "Not available" ;
VAL_ 2558852862 Aftrtrtmnt1PrticulateSnsrRegenRq 0 "Regeneration not requested" 1 "Regeneration requested" 2 "SAE reserved" 3 "Not available" ;
VAL_ 2558852862 Aft1PrticulateSnsrDewpoint 0 "Dewpoint has not been reached" 1 "Dewpoint has been reached" 2 "SAE reserved" 3 "Not available" ;
VAL_ 2558918398 PerformanceBiasSelection 0 "Functionality is biased toward fuel economy as much as possible." 20 "Functionality is biased toward neither fuel economy or performance." 8 "Functionality is biased toward performance as much as possible." ;
VAL_ 2558918398 SCROperatorIndcmntOverrideSwitch 0 "Off" 1 "On" 2 "Error" 3 "Not available" ;
VAL_ 2558918398 HeatExchngrDebrisPurgeInhbtSw 0 "not active" 1 "active" 2 "error" 3 "not available" ;
VAL_ 2558918398 HeatExchngrDebrisPurgeForceSw 0 "not active" 1 "active" 2 "error" 3 "not available" ;
VAL_ 2558918398 PredictiveCruiseCtrlEnableSwitch 0 "Predictive cruise control is not enabled" 1 "Predictive cruise control is enabled" 2 "Error" 3 "Not available" ;
VAL_ 2558918398 PredictCrsCtrlDeactivationRq 0 "Predictive cruise control is not requested to be deactived" 1 "Predictive cruise control is requested to be deactived" 2 "Error" 3 "Not available" ;
VAL_ 2558918398 EngineStopStartDisableCommand 0 "Automatic engine stop-start may be allowed" 1 "Automatic engine stop-start shall be disabled" 2 "Reserved" 3 "Don't care/Take no action" ;
VAL_ 2558918398 ElevatedEngineSpeedAllowedSwitch 0 "Not allowed to elevate engine speed" 1 "Allowed to elevate engine speed" 2 "Error" 3 "Not Available" ;
VAL_ 2558918398 AftrtrtmntRegenEngSpdAllwdSwitch 0 "Aftertreatment regeneration is not allowed" 1 "Aftertreatment regeneration is allowed" 2 "Error" 3 "Not Available" ;
VAL_ 2558918398 TransmissionAutoNtrlEnblSwitch 0 "Off" 1 "On" 2 "Error" 3 "Not Available" ;
VAL_ 2558918398 AftrtrtmntSystemEnableCommand 0 "De-activate Aftertreatment System" 1 "Activate Aftertreatment System" 2 "Reserved" 3 "Don't care/Take no Action" ;
VAL_ 2558918398 ActiveShiftConsoleRequest 0 "Use Primary Shift Console" 1 "Use Secondary Shift Console" 2 "Reserved" 3 "Don't Care / Take No Action" ;
VAL_ 2558983934 SwitchedPowerOutput4Command 0 "Output off" 1 "Output on" 2 "Reserved" 3 "Take no action" ;
VAL_ 2558983934 SwitchedPowerOutput3Command 0 "Output off" 1 "Output on" 2 "Reserved" 3 "Take no action" ;
VAL_ 2558983934 SwitchedPowerOutput2Command 0 "Output off" 1 "Output on" 2 "Reserved" 3 "Take no action" ;
VAL_ 2558983934 SwitchedPowerOutput1Command 0 "Output off" 1 "Output on" 2 "Reserved" 3 "Take no action" ;
VAL_ 2558983934 SwitchedPowerOutput8Command 0 "Output off" 1 "Output on" 2 "Reserved" 3 "Take no action" ;
VAL_ 2558983934 SwitchedPowerOutput7Command 0 "Output off" 1 "Output on" 2 "Reserved" 3 "Take no action" ;
VAL_ 2558983934 SwitchedPowerOutput6Command 0 "Output off" 1 "Output on" 2 "Reserved" 3 "Take no action" ;
VAL_ 2558983934 SwitchedPowerOutput5Command 0 "Output off" 1 "Output on" 2 "Reserved" 3 "Take no action" ;
VAL_ 2558983934 SwitchedPowerOutput12Command 0 "Output off" 1 "Output on" 2 "Reserved" 3 "Take no action" ;
VAL_ 2558983934 SwitchedPowerOutput11Command 0 "Output off" 1 "Output on" 2 "Reserved" 3 "Take no action" ;
VAL_ 2558983934 SwitchedPowerOutput10Command 0 "Output off" 1 "Output on" 2 "Reserved" 3 "Take no action" ;
VAL_ 2558983934 SwitchedPowerOutput9Command 0 "Output off" 1 "Output on" 2 "Reserved" 3 "Take no action" ;
VAL_ 2558983934 SwitchedPowerOutput16Command 0 "Output off" 1 "Output on" 2 "Reserved" 3 "Take no action" ;
VAL_ 2558983934 SwitchedPowerOutput15Command 0 "Output off" 1 "Output on" 2 "Reserved" 3 "Take no action" ;
VAL_ 2558983934 SwitchedPowerOutput14Command 0 "Output off" 1 "Output on" 2 "Reserved" 3 "Take no action" ;
VAL_ 2558983934 SwitchedPowerOutput13Command 0 "Output off" 1 "Output on" 2 "Reserved" 3 "Take no action" ;
VAL_ 2558983934 SwitchedPowerOutput20Command 0 "Output off" 1 "Output on" 2 "Reserved" 3 "Take no action" ;
VAL_ 2558983934 SwitchedPowerOutput19Command 0 "Output off" 1 "Output on" 2 "Reserved" 3 "Take no action" ;
VAL_ 2558983934 SwitchedPowerOutput18Command 0 "Output off" 1 "Output on" 2 "Reserved" 3 "Take no action" ;
VAL_ 2558983934 SwitchedPowerOutput17Command 0 "Output off" 1 "Output on" 2 "Reserved" 3 "Take no action" ;
VAL_ 2558983934 SwitchedPowerOutput24Command 0 "Output off" 1 "Output on" 2 "Reserved" 3 "Take no action" ;
VAL_ 2558983934 SwitchedPowerOutput23Command 0 "Output off" 1 "Output on" 2 "Reserved" 3 "Take no action" ;
VAL_ 2558983934 SwitchedPowerOutput22Command 0 "Output off" 1 "Output on" 2 "Reserved" 3 "Take no action" ;
VAL_ 2558983934 SwitchedPowerOutput21Command 0 "Output off" 1 "Output on" 2 "Reserved" 3 "Take no action" ;
VAL_ 2558983934 SwitchedPowerOutput28Command 0 "Output off" 1 "Output on" 2 "Reserved" 3 "Take no action" ;
VAL_ 2558983934 SwitchedPowerOutput27Command 0 "Output off" 1 "Output on" 2 "Reserved" 3 "Take no action" ;
VAL_ 2558983934 SwitchedPowerOutput26Command 0 "Output off" 1 "Output on" 2 "Reserved" 3 "Take no action" ;
VAL_ 2558983934 SwitchedPowerOutput25Command 0 "Output off" 1 "Output on" 2 "Reserved" 3 "Take no action" ;
VAL_ 2558983934 SwitchedPowerOutput32Command 0 "Output off" 1 "Output on" 2 "Reserved" 3 "Take no action" ;
VAL_ 2558983934 SwitchedPowerOutput31Command 0 "Output off" 1 "Output on" 2 "Reserved" 3 "Take no action" ;
VAL_ 2558983934 SwitchedPowerOutput30Command 0 "Output off" 1 "Output on" 2 "Reserved" 3 "Take no action" ;
VAL_ 2558983934 SwitchedPowerOutput29Command 0 "Output off" 1 "Output on" 2 "Reserved" 3 "Take no action" ;
VAL_ 2559049470 DesiredEngineFuelingState 0 "Fueling not desired" 1 "Fueling desired" 2 "Parameter supported, but no request" 3 "Don't care / Take no action" ;
VAL_ 2559049470 EngineGaseousFuelUsageInhibited 0 "Gaseous Fuel Usage Not Inhibited" 1 "Gaseous Fuel Usage Inhibited" 2 "Error" 3 "Not available" ;
VAL_ 2559049470 RequestedFuelType 0 "NONE" 1 "GAS" 2 "METH" 3 "ETH" 4 "DSL" 5 "LPG" 6 "CNG" 7 "PROP" 23 "NG" 24 "Reserved for use in SPN 5837" 254 "Reserved for use in SPN 5837" 255 "Not supported" ;
VAL_ 2559049470 EngineFuelingDesiredReason 0 "Desired Engine Fueling State from this device does not equal 01" 1 "Lubrication distribution in device is incomplete" 2 "Engine exhaust is needed as a heat source" 3 "Engine coolant is needed as a heat source" 4 "Engine is needed for cooling system operation" 5 "Engine is needed for charging the SLI batteries" 6 "Engine is needed for charging the hybrid stored energy source" 7 "Device protection is active" 8 "Device preparation for engine shutdown is in progress" 9 "Service Override is active" 10 "Device has detected one or more fault conditions" 11 "Engine is needed for engine driven accessory operation" 12 "Engine is needed for PTO operation" 13 "Engine is needed for DEF dosing system operation" 14 "Engine is needed for DEF dosing system component protection" 15 "Engine is needed for DEF dosing system diagnosis" 16 "Engine is needed for the Diesel Particulate Filter diagnosis" 250 "Engine operation is needed to perform normal device functions not specifically listed" 255 "Not supported" ;
VAL_ 2559049470 TransmissionIdlGvrnrFuelngInhbt 0 "Transmission Idle Governor Fueling Inhibit' is not currently desired." 1 "Transmission is currently commanding the Engine to inhibit idle governor fueling." 2 "Reserved for future SAE use." 3 "Don't care/take no action." ;
VAL_ 2559049470 EngineShutdownCommand 0 "No command to shut down the engine" 1 "Shut down the engine" 2 "SAE Reserved" 3 "Not Available" ;
VAL_ 2559049470 EngineFuelingNotDesiredReason 0 "Desired Engine Fueling State from this device does not equal 00 " 1 "Idle Shutdown Timer has expired" 2 "External power source has been connected" 3 "Body builder" 4 "Engine Stop-Start" 250 "Fueling is not desired due to unspecified reason" 255 "Not supported" ;
VAL_ 2559115006 RadioBeaconDirection 0 "Beacon Request" 1 "Beacon Received Acknowledgement" 2 "Reserved" 3 "Don't Care" ;
VAL_ 2559573758 CoolntLvlEngPrtctnShtdwnOvrrdCmd 0 "Disable engine protection shutdown" 1 "Enable engine protection shutdown" 2 "Reserved" 3 "Don't care/take no action" ;
VAL_ 2559639294 SupplementalFanEnableCommand 0 "Disable " 1 "Enable" 2 "Reserved " 3 "Don't Care/Take no action" ;
VAL_ 2559639294 SupplementalFanDirectionCommand 0 "Forward" 1 "Reverse" 2 "Reserved" 3 "Don't care/take no action" ;
VAL_ 2559639294 SupplementalFanPowerHold 0 "Disable" 1 "Enable" 2 "Reserved" 3 "Don't Care/Take no action" ;
VAL_ 2559704830 LubricationCycleModeLockCommand 0 "Not Locked" 1 "Locked" 2 "Reserved" 3 "No action" ;
VAL_ 2559704830 LubricationCycleSetCommand 0 "Cycle mode # 1" 1 "Cycle mode # 2" 2 "Cycle mode # 3" 3 "to 110" 7 "No action" ;
VAL_ 2559704830 LubricationOperationModeSetCmd 0 "Automatic Mode" 1 "Manual Service Mode" 2 "Test Mode # 1" 3 "Test Mode # 2" 4 "Test Mode # 3" 7 "Take no action" ;
VAL_ 2559704830 LubricationPumpEnableCommand 0 "No action (Normal pump operation)" 1 "Reset pump operation  " 2 "Reserved" 3 "Take no action" ;
VAL_ 2559704830 LubricationTimingCycleCommand 0 "Pause" 1 "Enable" 2 "Reserved " 3 "Take no action" ;
VAL_ 2559770366 HCDoserStatus 0 "HC doser disabled" 1 "HC doser active" 2 "SAE reserved" 3 "HC doser enabled, waiting for regeneration" 4 "SAE reserved" 5 "SAE reserved" 6 "Error" 7 "Not available" ;
VAL_ 2559770366 HCDoserInjectingStatus 0 "Injecting not active" 1 "Injecting active" 2 "Error" 3 "Not available" ;
VAL_ 2559770366 DiagnosticStatusOfHCDoser 0 "System test has executed and passed" 1 "Internal system test is in process" 6 "Error  --  System test has failed" 7 "Not available" ;
VAL_ 2559770366 HydrocarbonDoserPurgingRequired 0 "Purging not required" 1 "Purging required" 2 "Purging required" 3 "Not available" ;
VAL_ 2559835902 NAMEChecksumErrorCode 0 "Security not satisfied" 1 "Item(s) not allowed to change" 2 "Item conflict" 3 "Checksum does not match" 4 "Other" 23 "Not Available" ;
VAL_ 2559835902 ManufacturerCodeQualifierFlag 0 "Manufacturer Code is to be changed" 1 "Manufacturer Code shall not be changed" ;
VAL_ 2559835902 ECUInstanceQualifierFlag 0 "ECU Instance is to be changed" 1 "ECU Instance shall not be changed" ;
VAL_ 2559835902 FunctionInstanceQualifierFlag 0 "Function Instance is to be changed" 1 "Function Instance shall not be changed" ;
VAL_ 2559835902 FunctionQualifierFlag 0 "Function is to be changed" 1 "Function shall not be changed" ;
VAL_ 2559835902 VehicleSystemQualifierFlag 0 "Vehicle System is to be changed" 1 "Vehicle System shall not be changed" ;
VAL_ 2559835902 VehicleSystemInstanceQulfrFlg 0 "Vehicle System Instance is to be changed" 1 "Vehicle System Instance shall not be changed" ;
VAL_ 2559835902 IndustryGroupQualifierFlag 0 "Industry Group is to be changed" 1 "Industry Group shall not be changed" ;
VAL_ 2559835902 ArbtrryAddrCapableQualifierFlag 0 "Arbitrary Address Capable is to be changed" 1 "Arbitrary Address Capable shall not be changed" ;
VAL_ 2559835902 NMControlModeIndicator 0 "Set Pending NAME" 1 "Pending NAME" 2 "Current NAME" 3 "NAME ACK" 4 "NAME NACK" 5 "Request Pending NAME" 6 "Request Current NAME " 7 "Adopt Pending NAME" 8 "Request NAME Address Claim" ;
VAL_ 2560032510 LowVoltageDiscnnctDsrdOprtngMde 0 "Automatic" 4 "Manual Disconnect" 5 "Manual Connect" 15 "No change" ;
VAL_ 2560098046 CabNoiseControlStatus 0 "Cab Noise Control System ON-Line" 1 "Cab Noise Control System OFF-Line" 2 "Error Indicator" 3 "Not Available/Not Requested" ;
VAL_ 2560098046 CabNoiseControlTuningStatus 0 "Manual Tuning Mode" 1 "Manual Tuning Mode - Command Complete" 2 "Manual Tuning Mode - Saving Data" 3 "Reserved" 4 "Reserved " 5 "Reserved" 6 "Reserved" 7 "Manual Tuning Denied - Requires Security Verification" 8 "Automatic Tuning Mode" 9 "Automatic Tuning Mode - Command Complete" 10 "Automatic Tuning Mode - Saving Data" 11 "Reserved " 12 "Reserved" 13 "Reserved" 14 "Tuning Mode - Error" 15 "Not Available/Not Tuning/Not Requested" ;
VAL_ 2560163582 CabNoiseControlCommand 0 "Take Cab Noise Control System Off Line" 1 "Bring Cab Noise Control System On Line" 2 "Reserved" 3 "Don't Care/Not Commanded" ;
VAL_ 2560163582 CabNoiseControlTuningCommand 0 "Activate Manual Tuning" 1 "Activate Automatic Tuning" 2 "Activate Automatic Tuning State" 3 "Remain In Tuning" 4 "Exit Tuning" 5 "Exit Tuning" 6 "Reserved" 7 "Don't Care" ;
VAL_ 2358902526 Joystick1Lamp1Command 0 "Off" 1 "On" 2 "Blinking" 3 "Don't care / Take no action" ;
VAL_ 2358902526 Joystick1Lamp2Command 0 "Off" 1 "On" 2 "Blinking" 3 "Don't care / Take no action" ;
VAL_ 2358902526 Joystick1Lamp3Command 0 "Off" 1 "On" 2 "Blinking" 3 "Don't care / Take no action" ;
VAL_ 2358902526 Joystick1Lamp4Command 0 "Off" 1 "On" 2 "Blinking" 3 "Don't care / Take no action" ;
VAL_ 2358902526 Joystick1Lamp5Command 0 "Off" 1 "On" 2 "Blinking" 3 "Don't care / Take no action" ;
VAL_ 2358902526 Joystick1Lamp6Command 0 "Off" 1 "On" 2 "Blinking" 3 "Don't care / Take no action" ;
VAL_ 2358902526 Joystick1Lamp7Command 0 "Off" 1 "On" 2 "Blinking" 3 "Don't care / Take no action" ;
VAL_ 2358902526 Joystick1Lamp8Command 0 "Off" 1 "On" 2 "Blinking" 3 "Don't care / Take no action" ;
VAL_ 2358902526 Joystick1Lamp9Command 0 "Off" 1 "On" 2 "Blinking" 3 "Don't care / Take no action" ;
VAL_ 2358902526 Joystick1Lamp10Command 0 "Off" 1 "On" 2 "Blinking" 3 "Don't care / Take no action" ;
VAL_ 2358902526 Joystick2Lamp1Command 0 "Off" 1 "On" 2 "Blinking" 3 "Don't care / Take no action" ;
VAL_ 2358902526 Joystick2Lamp2Command 0 "Off" 1 "On" 2 "Blinking" 3 "Don't care / Take no action" ;
VAL_ 2358902526 Joystick2Lamp3Command 0 "Off" 1 "On" 2 "Blinking" 3 "Don't care / Take no action" ;
VAL_ 2358902526 Joystick2Lamp4Command 0 "Off" 1 "On" 2 "Blinking" 3 "Don't care / Take no action" ;
VAL_ 2358902526 Joystick2Lamp5Command 0 "Off" 1 "On" 2 "Blinking" 3 "Don't care / Take no action" ;
VAL_ 2358902526 Joystick2Lamp6Command 0 "Off" 1 "On" 2 "Blinking" 3 "Don't care / Take no action" ;
VAL_ 2358902526 Joystick2Lamp7Command 0 "Off" 1 "On" 2 "Blinking" 3 "Don't care / Take no action" ;
VAL_ 2358902526 Joystick2Lamp8Command 0 "Off" 1 "On" 2 "Blinking" 3 "Don't care / Take no action" ;
VAL_ 2358902526 Joystick2Lamp9Command 0 "Off" 1 "On" 2 "Blinking" 3 "Don't care / Take no action" ;
VAL_ 2358902526 Joystick2Lamp10Command 0 "Off" 1 "On" 2 "Blinking" 3 "Don't care / Take no action" ;
VAL_ 2358902526 Joystick3Lamp1Command 0 "Off" 1 "On" 2 "Blinking" 3 "Don't care / Take no action" ;
VAL_ 2358902526 Joystick3Lamp2Command 0 "Off" 1 "On" 2 "Blinking" 3 "Don't care / Take no action" ;
VAL_ 2358902526 Joystick3Lamp3Command 0 "Off" 1 "On" 2 "Blinking" 3 "Don't care / Take no action" ;
VAL_ 2358902526 Joystick3Lamp4Command 0 "Off" 1 "On" 2 "Blinking" 3 "Don't care / Take no action" ;
VAL_ 2358902526 Joystick3Lamp5Command 0 "Off" 1 "On" 2 "Blinking" 3 "Don't care / Take no action" ;
VAL_ 2358902526 Joystick3Lamp6Command 0 "Off" 1 "On" 2 "Blinking" 3 "Don't care / Take no action" ;
VAL_ 2358902526 Joystick3Lamp7Command 0 "Off" 1 "On" 2 "Blinking" 3 "Don't care / Take no action" ;
VAL_ 2358902526 Joystick3Lamp8Command 0 "Off" 1 "On" 2 "Blinking" 3 "Don't care / Take no action" ;
VAL_ 2358902526 Joystick3Lamp9Command 0 "Off" 1 "On" 2 "Blinking" 3 "Don't care / Take no action" ;
VAL_ 2358902526 Joystick3Lamp10Command 0 "Off" 1 "On" 2 "Blinking" 3 "Don't care / Take no action" ;
VAL_ 2560622334 ProtectLamp 0 "Lamp Off" 1 "Lamp On" 2 "Reserved" 3 "Not available" ;
VAL_ 2560622334 AmberWarningLamp 0 "Lamp Off" 1 "Lamp On" 2 "Reserved" 3 "Not available" ;
VAL_ 2560622334 RedStopLamp 0 "Lamp Off" 1 "Lamp On" 2 "Reserved" 3 "Not available" ;
VAL_ 2560622334 MalfunctionIndicatorLamp 0 "Lamp Off" 1 "Lamp On" 2 "Short MIL for WWH OBD" 3 "Not available" ;
VAL_ 2560622334 FlashProtectLamp 0 "Slow Flash (1 Hz, 50 % duty cycle)" 1 "Fast Flash (2 Hz or faster, 50% duty cycle)" 2 "Reserved" 3 "Unavailable / Do Not Flash" ;
VAL_ 2560622334 FlashAmberWarningLamp 0 "Slow Flash (1 Hz, 50 % duty cycle)" 1 "Fast Flash (2 Hz or faster, 50% duty cycle)" 2 "Reserved" 3 "Unavailable / Do Not Flash" ;
VAL_ 2560622334 FlashRedStopLamp 0 "Slow Flash (1 Hz, 50 % duty cycle)" 1 "Fast Flash (2 Hz or faster, 50% duty cycle)" 2 "Reserved" 3 "Unavailable / Do Not Flash" ;
VAL_ 2560622334 FlashMalfunctionIndicatorLamp 0 "Slow Flash (1 Hz, 50 % duty cycle)" 1 "Fast Flash (2 Hz or faster, 50% duty cycle)" 2 "Class C DTC  " 3 "Unavailable / Do Not Flash" ;
VAL_ 2560622334 SPNConversionMethod 0 "Convert SPN per Version 4" 1 "Convert SPN per Version 1, 2 or 3" ;
VAL_ 2560687870 NOxNTEDeficiencyAreaStatus 0 "Outside Area" 1 "Inside Area" 2 "Reserved" 3 "Not available" ;
VAL_ 2560687870 ManfctSpcNOxNTELmtedTestRgnStat 0 "Outside Area" 1 "Inside Area" 2 "Reserved" 3 "Not available" ;
VAL_ 2560687870 NOxNTEControlAreaStatus 0 "Outside Control Area" 1 "Inside Control Area" 2 "Reserved" 3 "Not available" ;
VAL_ 2560687870 PMNTEDeficiencyAreaStatus 0 "Outside Area" 1 "Inside Area" 2 "Reserved" 3 "Not available" ;
VAL_ 2560687870 ManfctSpcPMNTELmtedTestRgnStat 0 "Outside Area" 1 "Inside Area" 2 "Reserved" 3 "Not available" ;
VAL_ 2560687870 PMNTEControlAreaStatus 0 "Outside Control Area" 1 "Inside Control Area" 2 "Reserved" 3 "Not available" ;
VAL_ 2560884478 SPNConversionMethod 0 "Convert SPN per Version 4" 1 "Convert SPN per Version 1, 2 or 3" ;
VAL_ 2560884478 DTCxProtectLampSupportStatus 0 "Lamp Off" 1 "Lamp On" 2 "Reserved" 3 "Not available" ;
VAL_ 2560884478 DTCxAmberWarningLampSupportStat 0 "Lamp Off" 1 "Lamp On" 2 "Reserved" 3 "Not available" ;
VAL_ 2560884478 DTCxRedStopLampSupportStatus 0 "Lamp Off" 1 "Lamp On" 2 "Reserved" 3 "Not available" ;
VAL_ 2560884478 DTCxMalfnctnIndictrLampSuppStat 0 "Lamp Off" 1 "Lamp On" 2 "Short MIL for WWH OBD" 3 "Not available" ;
VAL_ 2560884478 DTCxFlashProtectLampSupportStat 0 "Slow Flash (1 Hz, 50 % duty cycle)" 1 "Fast Flash (2 Hz or faster, 50% duty cycle)" 2 "Reserved" 3 "Unavailable / Do Not Flash" ;
VAL_ 2560884478 DTCxFlashAmberWrngLampSuppStat 0 "Slow Flash (1 Hz, 50 % duty cycle)" 1 "Fast Flash (2 Hz or faster, 50% duty cycle)" 2 "Reserved" 3 "Unavailable / Do Not Flash" ;
VAL_ 2560884478 DTCxFlashRedStopLampSupportStat 0 "Slow Flash (1 Hz, 50 % duty cycle)" 1 "Fast Flash (2 Hz or faster, 50% duty cycle)" 2 "Reserved" 3 "Unavailable / Do Not Flash" ;
VAL_ 2560884478 DTCxFlashMalfctIndictrLampSuppSt 0 "Slow Flash (1 Hz, 50 % duty cycle)" 1 "Fast Flash (2 Hz or faster, 50% duty cycle)" 2 "Class C DTC  " 3 "Unavailable / Do Not Flash" ;
VAL_ 2560950014 TestIdentifier 0 "Reserved for SAE Assignment" 245 "Reserved for 'Return Data Value'" 246 "Return all scaled test results for all SPNs" 247 "Return all scaled test results for one SPN" 248 "Command Manufacturer Specific Test" 249 "Command Standard Test" 250 "Return Last Measured Scaled Results" ;
VAL_ 2561015550 AuxiliaryIO84 0 "Auxiliary channel off" 1 "Auxiliary channel on" 2 "Error Indicator or Not Used" 3 "Not Available or Take No Action" ;
VAL_ 2561015550 AuxiliaryIO83 0 "Auxiliary channel off" 1 "Auxiliary channel on" 2 "Error Indicator or Not Used" 3 "Not Available or Take No Action" ;
VAL_ 2561015550 AuxiliaryIO82 0 "Auxiliary channel off" 1 "Auxiliary channel on" 2 "Error Indicator or Not Used" 3 "Not Available or Take No Action" ;
VAL_ 2561015550 AuxiliaryIO81 0 "Auxiliary channel off" 1 "Auxiliary channel on" 2 "Error Indicator or Not Used" 3 "Not Available or Take No Action" ;
VAL_ 2561015550 AuxiliaryIO88 0 "Auxiliary channel off" 1 "Auxiliary channel on" 2 "Error Indicator or Not Used" 3 "Not Available or Take No Action" ;
VAL_ 2561015550 AuxiliaryIO87 0 "Auxiliary channel off" 1 "Auxiliary channel on" 2 "Error Indicator or Not Used" 3 "Not Available or Take No Action" ;
VAL_ 2561015550 AuxiliaryIO86 0 "Auxiliary channel off" 1 "Auxiliary channel on" 2 "Error Indicator or Not Used" 3 "Not Available or Take No Action" ;
VAL_ 2561015550 AuxiliaryIO85 0 "Auxiliary channel off" 1 "Auxiliary channel on" 2 "Error Indicator or Not Used" 3 "Not Available or Take No Action" ;
VAL_ 2561015550 AuxiliaryIO92 0 "Auxiliary channel off" 1 "Auxiliary channel on" 2 "Error Indicator or Not Used" 3 "Not Available or Take No Action" ;
VAL_ 2561015550 AuxiliaryIO91 0 "Auxiliary channel off" 1 "Auxiliary channel on" 2 "Error Indicator or Not Used" 3 "Not Available or Take No Action" ;
VAL_ 2561015550 AuxiliaryIO90 0 "Auxiliary channel off" 1 "Auxiliary channel on" 2 "Error Indicator or Not Used" 3 "Not Available or Take No Action" ;
VAL_ 2561015550 AuxiliaryIO89 0 "Auxiliary channel off" 1 "Auxiliary channel on" 2 "Error Indicator or Not Used" 3 "Not Available or Take No Action" ;
VAL_ 2561015550 AuxiliaryIO96 0 "Auxiliary channel off" 1 "Auxiliary channel on" 2 "Error Indicator or Not Used" 3 "Not Available or Take No Action" ;
VAL_ 2561015550 AuxiliaryIO95 0 "Auxiliary channel off" 1 "Auxiliary channel on" 2 "Error Indicator or Not Used" 3 "Not Available or Take No Action" ;
VAL_ 2561015550 AuxiliaryIO94 0 "Auxiliary channel off" 1 "Auxiliary channel on" 2 "Error Indicator or Not Used" 3 "Not Available or Take No Action" ;
VAL_ 2561015550 AuxiliaryIO93 0 "Auxiliary channel off" 1 "Auxiliary channel on" 2 "Error Indicator or Not Used" 3 "Not Available or Take No Action" ;
VAL_ 2561015550 AuxiliaryIO100 0 "Auxiliary channel off" 1 "Auxiliary channel on" 2 "Error Indicator or Not Used" 3 "Not Available or Take No Action" ;
VAL_ 2561015550 AuxiliaryIO99 0 "Auxiliary channel off" 1 "Auxiliary channel on" 2 "Error Indicator or Not Used" 3 "Not Available or Take No Action" ;
VAL_ 2561015550 AuxiliaryIO98 0 "Auxiliary channel off" 1 "Auxiliary channel on" 2 "Error Indicator or Not Used" 3 "Not Available or Take No Action" ;
VAL_ 2561015550 AuxiliaryIO97 0 "Auxiliary channel off" 1 "Auxiliary channel on" 2 "Error Indicator or Not Used" 3 "Not Available or Take No Action" ;
VAL_ 2561015550 AuxiliaryIO104 0 "Auxiliary channel off" 1 "Auxiliary channel on" 2 "Error Indicator or Not Used" 3 "Not Available or Take No Action" ;
VAL_ 2561015550 AuxiliaryIO103 0 "Auxiliary channel off" 1 "Auxiliary channel on" 2 "Error Indicator or Not Used" 3 "Not Available or Take No Action" ;
VAL_ 2561015550 AuxiliaryIO102 0 "Auxiliary channel off" 1 "Auxiliary channel on" 2 "Error Indicator or Not Used" 3 "Not Available or Take No Action" ;
VAL_ 2561015550 AuxiliaryIO101 0 "Auxiliary channel off" 1 "Auxiliary channel on" 2 "Error Indicator or Not Used" 3 "Not Available or Take No Action" ;
VAL_ 2561015550 AuxiliaryIO108 0 "Auxiliary channel off" 1 "Auxiliary channel on" 2 "Error Indicator or Not Used" 3 "Not Available or Take No Action" ;
VAL_ 2561015550 AuxiliaryIO107 0 "Auxiliary channel off" 1 "Auxiliary channel on" 2 "Error Indicator or Not Used" 3 "Not Available or Take No Action" ;
VAL_ 2561015550 AuxiliaryIO106 0 "Auxiliary channel off" 1 "Auxiliary channel on" 2 "Error Indicator or Not Used" 3 "Not Available or Take No Action" ;
VAL_ 2561015550 AuxiliaryIO105 0 "Auxiliary channel off" 1 "Auxiliary channel on" 2 "Error Indicator or Not Used" 3 "Not Available or Take No Action" ;
VAL_ 2561015550 AuxiliaryIO112 0 "Auxiliary channel off" 1 "Auxiliary channel on" 2 "Error Indicator or Not Used" 3 "Not Available or Take No Action" ;
VAL_ 2561015550 AuxiliaryIO111 0 "Auxiliary channel off" 1 "Auxiliary channel on" 2 "Error Indicator or Not Used" 3 "Not Available or Take No Action" ;
VAL_ 2561015550 AuxiliaryIO110 0 "Auxiliary channel off" 1 "Auxiliary channel on" 2 "Error Indicator or Not Used" 3 "Not Available or Take No Action" ;
VAL_ 2561015550 AuxiliaryIO109 0 "Auxiliary channel off" 1 "Auxiliary channel on" 2 "Error Indicator or Not Used" 3 "Not Available or Take No Action" ;
VAL_ 2561081086 AuxiliaryIO52 0 "Auxiliary channel off" 1 "Auxiliary channel on" 2 "Error Indicator or Not Used" 3 "Not Available or Take No Action" ;
VAL_ 2561081086 AuxiliaryIO51 0 "Auxiliary channel off" 1 "Auxiliary channel on" 2 "Error Indicator or Not Used" 3 "Not Available or Take No Action" ;
VAL_ 2561081086 AuxiliaryIO50 0 "Auxiliary channel off" 1 "Auxiliary channel on" 2 "Error Indicator or Not Used" 3 "Not Available or Take No Action" ;
VAL_ 2561081086 AuxiliaryIO49 0 "Auxiliary channel off" 1 "Auxiliary channel on" 2 "Error Indicator or Not Used" 3 "Not Available or Take No Action" ;
VAL_ 2561081086 AuxiliaryIO56 0 "Auxiliary channel off" 1 "Auxiliary channel on" 2 "Error Indicator or Not Used" 3 "Not Available or Take No Action" ;
VAL_ 2561081086 AuxiliaryIO55 0 "Auxiliary channel off" 1 "Auxiliary channel on" 2 "Error Indicator or Not Used" 3 "Not Available or Take No Action" ;
VAL_ 2561081086 AuxiliaryIO54 0 "Auxiliary channel off" 1 "Auxiliary channel on" 2 "Error Indicator or Not Used" 3 "Not Available or Take No Action" ;
VAL_ 2561081086 AuxiliaryIO53 0 "Auxiliary channel off" 1 "Auxiliary channel on" 2 "Error Indicator or Not Used" 3 "Not Available or Take No Action" ;
VAL_ 2561081086 AuxiliaryIO60 0 "Auxiliary channel off" 1 "Auxiliary channel on" 2 "Error Indicator or Not Used" 3 "Not Available or Take No Action" ;
VAL_ 2561081086 AuxiliaryIO59 0 "Auxiliary channel off" 1 "Auxiliary channel on" 2 "Error Indicator or Not Used" 3 "Not Available or Take No Action" ;
VAL_ 2561081086 AuxiliaryIO58 0 "Auxiliary channel off" 1 "Auxiliary channel on" 2 "Error Indicator or Not Used" 3 "Not Available or Take No Action" ;
VAL_ 2561081086 AuxiliaryIO57 0 "Auxiliary channel off" 1 "Auxiliary channel on" 2 "Error Indicator or Not Used" 3 "Not Available or Take No Action" ;
VAL_ 2561081086 AuxiliaryIO64 0 "Auxiliary channel off" 1 "Auxiliary channel on" 2 "Error Indicator or Not Used" 3 "Not Available or Take No Action" ;
VAL_ 2561081086 AuxiliaryIO63 0 "Auxiliary channel off" 1 "Auxiliary channel on" 2 "Error Indicator or Not Used" 3 "Not Available or Take No Action" ;
VAL_ 2561081086 AuxiliaryIO62 0 "Auxiliary channel off" 1 "Auxiliary channel on" 2 "Error Indicator or Not Used" 3 "Not Available or Take No Action" ;
VAL_ 2561081086 AuxiliaryIO61 0 "Auxiliary channel off" 1 "Auxiliary channel on" 2 "Error Indicator or Not Used" 3 "Not Available or Take No Action" ;
VAL_ 2561081086 AuxiliaryIO68 0 "Auxiliary channel off" 1 "Auxiliary channel on" 2 "Error Indicator or Not Used" 3 "Not Available or Take No Action" ;
VAL_ 2561081086 AuxiliaryIO67 0 "Auxiliary channel off" 1 "Auxiliary channel on" 2 "Error Indicator or Not Used" 3 "Not Available or Take No Action" ;
VAL_ 2561081086 AuxiliaryIO66 0 "Auxiliary channel off" 1 "Auxiliary channel on" 2 "Error Indicator or Not Used" 3 "Not Available or Take No Action" ;
VAL_ 2561081086 AuxiliaryIO65 0 "Auxiliary channel off" 1 "Auxiliary channel on" 2 "Error Indicator or Not Used" 3 "Not Available or Take No Action" ;
VAL_ 2561081086 AuxiliaryIO72 0 "Auxiliary channel off" 1 "Auxiliary channel on" 2 "Error Indicator or Not Used" 3 "Not Available or Take No Action" ;
VAL_ 2561081086 AuxiliaryIO71 0 "Auxiliary channel off" 1 "Auxiliary channel on" 2 "Error Indicator or Not Used" 3 "Not Available or Take No Action" ;
VAL_ 2561081086 AuxiliaryIO70 0 "Auxiliary channel off" 1 "Auxiliary channel on" 2 "Error Indicator or Not Used" 3 "Not Available or Take No Action" ;
VAL_ 2561081086 AuxiliaryIO69 0 "Auxiliary channel off" 1 "Auxiliary channel on" 2 "Error Indicator or Not Used" 3 "Not Available or Take No Action" ;
VAL_ 2561081086 AuxiliaryIO76 0 "Auxiliary channel off" 1 "Auxiliary channel on" 2 "Error Indicator or Not Used" 3 "Not Available or Take No Action" ;
VAL_ 2561081086 AuxiliaryIO75 0 "Auxiliary channel off" 1 "Auxiliary channel on" 2 "Error Indicator or Not Used" 3 "Not Available or Take No Action" ;
VAL_ 2561081086 AuxiliaryIO74 0 "Auxiliary channel off" 1 "Auxiliary channel on" 2 "Error Indicator or Not Used" 3 "Not Available or Take No Action" ;
VAL_ 2561081086 AuxiliaryIO73 0 "Auxiliary channel off" 1 "Auxiliary channel on" 2 "Error Indicator or Not Used" 3 "Not Available or Take No Action" ;
VAL_ 2561081086 AuxiliaryIO80 0 "Auxiliary channel off" 1 "Auxiliary channel on" 2 "Error Indicator or Not Used" 3 "Not Available or Take No Action" ;
VAL_ 2561081086 AuxiliaryIO79 0 "Auxiliary channel off" 1 "Auxiliary channel on" 2 "Error Indicator or Not Used" 3 "Not Available or Take No Action" ;
VAL_ 2561081086 AuxiliaryIO78 0 "Auxiliary channel off" 1 "Auxiliary channel on" 2 "Error Indicator or Not Used" 3 "Not Available or Take No Action" ;
VAL_ 2561081086 AuxiliaryIO77 0 "Auxiliary channel off" 1 "Auxiliary channel on" 2 "Error Indicator or Not Used" 3 "Not Available or Take No Action" ;
VAL_ 2561146622 AuxiliaryIO20 0 "Auxiliary channel off" 1 "Auxiliary channel on" 2 "Error Indicator or Not Used" 3 "Not Available or Take No Action" ;
VAL_ 2561146622 AuxiliaryIO19 0 "Auxiliary channel off" 1 "Auxiliary channel on" 2 "Error Indicator or Not Used" 3 "Not Available or Take No Action" ;
VAL_ 2561146622 AuxiliaryIO18 0 "Auxiliary channel off" 1 "Auxiliary channel on" 2 "Error Indicator or Not Used" 3 "Not Available or Take No Action" ;
VAL_ 2561146622 AuxiliaryIO17 0 "Auxiliary channel off" 1 "Auxiliary channel on" 2 "Error Indicator or Not Used" 3 "Not Available or Take No Action" ;
VAL_ 2561146622 AuxiliaryIO24 0 "Auxiliary channel off" 1 "Auxiliary channel on" 2 "Error Indicator or Not Used" 3 "Not Available or Take No Action" ;
VAL_ 2561146622 AuxiliaryIO23 0 "Auxiliary channel off" 1 "Auxiliary channel on" 2 "Error Indicator or Not Used" 3 "Not Available or Take No Action" ;
VAL_ 2561146622 AuxiliaryIO22 0 "Auxiliary channel off" 1 "Auxiliary channel on" 2 "Error Indicator or Not Used" 3 "Not Available or Take No Action" ;
VAL_ 2561146622 AuxiliaryIO21 0 "Auxiliary channel off" 1 "Auxiliary channel on" 2 "Error Indicator or Not Used" 3 "Not Available or Take No Action" ;
VAL_ 2561146622 AuxiliaryIO28 0 "Auxiliary channel off" 1 "Auxiliary channel on" 2 "Error Indicator or Not Used" 3 "Not Available or Take No Action" ;
VAL_ 2561146622 AuxiliaryIO27 0 "Auxiliary channel off" 1 "Auxiliary channel on" 2 "Error Indicator or Not Used" 3 "Not Available or Take No Action" ;
VAL_ 2561146622 AuxiliaryIO26 0 "Auxiliary channel off" 1 "Auxiliary channel on" 2 "Error Indicator or Not Used" 3 "Not Available or Take No Action" ;
VAL_ 2561146622 AuxiliaryIO25 0 "Auxiliary channel off" 1 "Auxiliary channel on" 2 "Error Indicator or Not Used" 3 "Not Available or Take No Action" ;
VAL_ 2561146622 AuxiliaryIO32 0 "Auxiliary channel off" 1 "Auxiliary channel on" 2 "Error Indicator or Not Used" 3 "Not Available or Take No Action" ;
VAL_ 2561146622 AuxiliaryIO31 0 "Auxiliary channel off" 1 "Auxiliary channel on" 2 "Error Indicator or Not Used" 3 "Not Available or Take No Action" ;
VAL_ 2561146622 AuxiliaryIO30 0 "Auxiliary channel off" 1 "Auxiliary channel on" 2 "Error Indicator or Not Used" 3 "Not Available or Take No Action" ;
VAL_ 2561146622 AuxiliaryIO29 0 "Auxiliary channel off" 1 "Auxiliary channel on" 2 "Error Indicator or Not Used" 3 "Not Available or Take No Action" ;
VAL_ 2561146622 AuxiliaryIO36 0 "Auxiliary channel off" 1 "Auxiliary channel on" 2 "Error Indicator or Not Used" 3 "Not Available or Take No Action" ;
VAL_ 2561146622 AuxiliaryIO35 0 "Auxiliary channel off" 1 "Auxiliary channel on" 2 "Error Indicator or Not Used" 3 "Not Available or Take No Action" ;
VAL_ 2561146622 AuxiliaryIO34 0 "Auxiliary channel off" 1 "Auxiliary channel on" 2 "Error Indicator or Not Used" 3 "Not Available or Take No Action" ;
VAL_ 2561146622 AuxiliaryIO33 0 "Auxiliary channel off" 1 "Auxiliary channel on" 2 "Error Indicator or Not Used" 3 "Not Available or Take No Action" ;
VAL_ 2561146622 AuxiliaryIO40 0 "Auxiliary channel off" 1 "Auxiliary channel on" 2 "Error Indicator or Not Used" 3 "Not Available or Take No Action" ;
VAL_ 2561146622 AuxiliaryIO39 0 "Auxiliary channel off" 1 "Auxiliary channel on" 2 "Error Indicator or Not Used" 3 "Not Available or Take No Action" ;
VAL_ 2561146622 AuxiliaryIO38 0 "Auxiliary channel off" 1 "Auxiliary channel on" 2 "Error Indicator or Not Used" 3 "Not Available or Take No Action" ;
VAL_ 2561146622 AuxiliaryIO37 0 "Auxiliary channel off" 1 "Auxiliary channel on" 2 "Error Indicator or Not Used" 3 "Not Available or Take No Action" ;
VAL_ 2561146622 AuxiliaryIO44 0 "Auxiliary channel off" 1 "Auxiliary channel on" 2 "Error Indicator or Not Used" 3 "Not Available or Take No Action" ;
VAL_ 2561146622 AuxiliaryIO43 0 "Auxiliary channel off" 1 "Auxiliary channel on" 2 "Error Indicator or Not Used" 3 "Not Available or Take No Action" ;
VAL_ 2561146622 AuxiliaryIO42 0 "Auxiliary channel off" 1 "Auxiliary channel on" 2 "Error Indicator or Not Used" 3 "Not Available or Take No Action" ;
VAL_ 2561146622 AuxiliaryIO41 0 "Auxiliary channel off" 1 "Auxiliary channel on" 2 "Error Indicator or Not Used" 3 "Not Available or Take No Action" ;
VAL_ 2561146622 AuxiliaryIO48 0 "Auxiliary channel off" 1 "Auxiliary channel on" 2 "Error Indicator or Not Used" 3 "Not Available or Take No Action" ;
VAL_ 2561146622 AuxiliaryIO47 0 "Auxiliary channel off" 1 "Auxiliary channel on" 2 "Error Indicator or Not Used" 3 "Not Available or Take No Action" ;
VAL_ 2561146622 AuxiliaryIO46 0 "Auxiliary channel off" 1 "Auxiliary channel on" 2 "Error Indicator or Not Used" 3 "Not Available or Take No Action" ;
VAL_ 2561146622 AuxiliaryIO45 0 "Auxiliary channel off" 1 "Auxiliary channel on" 2 "Error Indicator or Not Used" 3 "Not Available or Take No Action" ;
VAL_ 2561212158 TextDisplayInstructions 0 "Clear display" 1 "Hold display" 2 "Append at end of display" 3 "Overwrite display" 4 "Overwrite substring" 5 "Highlight substring" 6 "Blink substring" 15 "Not applicable" ;
VAL_ 2561277694 LaneDepartureWarningEnableCmd 0 "Disable Lane Departure Warning" 1 "Enable Lane Departure Warning" 2 "Reserved" 3 "Don`t care" ;
VAL_ 2562981630 DM22CtrlBytIndivDTCClrRstCtrlByt 0 "Reserved for SAE Assignment" 1 "Request to Clear/Reset" 2 "Positive Acknowledge" 3 "Negative Acknowledge" 17 "Request to Clear/Reset" 18 "Positive Acknowledge" 19 "Negative Acknowledge" 255 "Not Available" ;
VAL_ 2562981630 DM22CtrlBytSpcIndictrIndivDTCClr 0 "General Negative Acknowledge" 1 "Access Denied (Security Denied Access)" 2 "Diagnostic Trouble Code unknown/does not exist" 3 "Diagnostic Trouble Code no longer Previously Active" 4 "Diagnostic Trouble Code no longer Active" 255 "Not Available" ;
VAL_ 2563374846 UseTransferMode 0 "No" 1 "Yes" 2 "Undefined" 3 "NA" ;
VAL_ 2362638078 AutomaticTractionHelp 0 "Disable automatic traction help" 1 "Enable automatic traction help " 2 "Reserved" 3 "Don't care" ;
VAL_ 2362638078 KneelingRequestLeftSide 0 "No kneeling request" 1 "Kneeling request" 2 "Reserved" 3 "Don't care/take no action" ;
VAL_ 2362638078 KneelingRequestRightSide 0 "No kneeling request" 1 "Kneeling request" 2 "Reserved" 3 "Don't care/take no action" ;
VAL_ 2362638078 KneelingControlModeRequest 0 "No kneeling request" 1 "Kneeling request" 2 "Reserved" 3 "Don't care/take no action" ;
VAL_ 2362638078 NominalLevelRequestFrontAxle 0 "No level request" 1 "Normal Level 1" 2 "Normal Level 2" 3 "Normal Level 3" 4 "Preset Level" 5 "Customer Level" 6 "Upper Level" 7 "Lower Level" 8 "Stop level change" 9 "Raise Request" 10 "Lower Request" 14 "Reserved" 15 "Don't care/take no action" ;
VAL_ 2362638078 NominalLevelRequestRearAxle 0 "No level request" 1 "Normal Level 1" 2 "Normal Level 2" 3 "Normal Level 3" 4 "Preset Level" 5 "Customer Level" 6 "Upper Level" 7 "Lower Level" 8 "Stop level change" 9 "Raise Request" 10 "Lower Request" 14 "Reserved" 15 "Don't care/take no action" ;
VAL_ 2362638078 LevelControlModeRequest 0 "Normal operation" 1 "Traction help (load transfer)" 2 "Load fixing" 3 "Pressure ratio 1" 4 "Pressure ratio 2" 5 "Optimum traction 1" 6 "Optimum traction 2" 7 "Traction help - load reduce" 8 "Exhaust bellows" 9 "Force to bumper level" 14 "Reserved" 15 "Don't care/take no action" ;
VAL_ 2362638078 LiftAxle1PositionCommand 0 "Lift axle position down / tag axle laden" 1 "Lift axle position up / tag axle unladen" 2 "Reserved" 3 "Don't care/take no action" ;
VAL_ 2362638078 LiftAxle2PositionCommand 0 "Lift axle position down / tag axle laden" 1 "Lift axle position up / tag axle unladen" 2 "Reserved" 3 "Don't care/take no action" ;
VAL_ 2362638078 KneelingCommandFrontAxle 0 "Deactivate kneeling" 1 "Activate kneeling" 2 "Reserved" 3 "Don't care/take no action" ;
VAL_ 2362638078 KneelingCommandRearAxle 0 "Deactivate kneeling" 1 "Activate kneeling" 2 "Reserved" 3 "Don't care/take no action" ;
VAL_ 2362638078 ProhibitAirSuspensionControl 0 "No request" 1 "Request prohibit air suspension control" 2 "Error indicator" 3 "Not available" ;
VAL_ 2362638078 AllowLevelControlDuringBrkngCmd 0 "Disallow level control during braking" 1 "Allow level control during braking" 2 "Reserved" 3 "Don't care/take no action" ;
VAL_ 2362638078 SpeedDependentLevelCtrlRequest 0 "Deactivate" 1 "Activate" 2 "Reserved" 3 "Don't care/take no action" ;
VAL_ 2362638078 ProhibitAutoAirSuspensionControl 0 "No request " 1 "Request prohibit automatic air suspension control " 2 "Error indicator " 3 "Not available" ;
VAL_ 2362638078 MemoryLevelRequest 0 "No memory level request" 1 "Memory level 1 request" 2 "Memory level 2 request" 3 "Memory level 3 request" 4 "Memory level 4 request" 5 "Memory level 5 request" 9 "Store Memory level  1" 10 "Store Memory level  2" 11 "Store Memory level  3" 12 "Store Memory level  4" 13 "Store Memory level  5" 14 "Reserved" 15 "Don't care" ;
VAL_ 2564095742 SecurityEntityType 0 "Data is Long Seed" 1 "Data is Long Key" 2 "Data is Session Key" 3 "Data is Certificate" ;
VAL_ 2564357886 EDCPExtension 0 "Completed" 1 "Reserved for SAE assignment" 2 "More - Concatenate As Higher" 3 "More - Concatenate As Lower" 6 "EDC Data Error" 7 "EDC Data Error and Data Seed expected" 255 "No Error" ;
VAL_ 2564423422 PointerType 0 "Direct Memory Addressing" 1 "Direct Spatial Addressing" ;
VAL_ 2631728894 AntithftEncryptnSeedPrsntIndictr 0 "Random number is not present" 1 "Random number is present" 2 "Error" 3 "Not available" ;
VAL_ 2631728894 AntiTheftPasswordValidIndicator 0 "Password is not a validated password" 1 "Password is a validated password" 2 "Error" 3 "Not available" ;
VAL_ 2631728894 AntiTheftComponentStatusStates 0 "Unlocked" 1 "Locked" 2 "Blocked" 3 "Not defined" ;
VAL_ 2631728894 AntiTheftModifyPasswordStates 0 "Ok" 1 "Full_of_Passwords" 2 "Empty_of_Passwords" 3 "Not_valid" ;
VAL_ 2631794430 AntithftEncryptnIndicatorStates 0 "Encryption_Seed_Request" 1 "Encrypted_Code_Present" 2 "Not defined" 3 "Not_Available" ;
VAL_ 2631794430 AntiTheftDesiredExitModeStates 0 "Lock_Upon_Operator_Request" 1 "Lock_When_Key_Off" 2 "Not defined" 3 "Not_Available" ;
VAL_ 2631794430 AntiTheftCommandStates 0 "Add_Password" 1 "Delete_Password" 2 "Change_Password" 3 "Lock_or_Unlock" 4 "Check_Status" 5 "Login" ;
VAL_ 2631859966 TripGroup1 0 "Take no action" 1 "Reset" 2 "Reserved" 3 "Not applicable" ;
VAL_ 2631859966 TripGroup2Proprietary 0 "Take no action" 1 "Reset" 2 "Reserved" 3 "Not applicable" ;
VAL_ 2631859966 EngineBuildHoursReset 0 "Do not reset" 1 "Reset" 2 "Reserved" 3 "Take no action" ;
VAL_ 2631859966 SteeringStraightAheadPosReset 0 "Take no action - Do not Reset" 1 "Reset" 2 "Reserved, take no action" 3 "Not applicable" ;
VAL_ 2631859966 EngSparkPlugSecVltgTrackingRst 0 "Do not reset" 1 "Reset" 2 "Reserved" 3 "Take no action" ;
VAL_ 2631859966 EngIgnitionCtrlMaintenanceHrsRst 0 "Do not reset" 1 "Reset" 2 "Reserved" 3 "Take no action" ;
VAL_ 2631859966 BinLiftCountReset 0 "Do not reset" 1 "Reset" 2 "Reserved" 3 "Take no action" ;
VAL_ 2631859966 TireConfigurationInformation 0 "Take no action" 1 "Reset" 2 "Reserved" 3 "Not applicable" ;
VAL_ 2631859966 TireSensorInformation 0 "Take no action" 1 "Reset" 2 "Reserved" 3 "Not applicable" ;
VAL_ 2564816638 J1939Network1_PrmryVhclNetwork 0 "Stop Broadcast" 1 "Start Broadcast" 2 "Reserved" 3 "Don't Care/take no action (leave as is)" ;
VAL_ 2564816638 J1922 0 "Stop Broadcast" 1 "Start Broadcast" 2 "Reserved" 3 "Don't Care/take no action (leave as is)" ;
VAL_ 2564816638 J1587 0 "Stop Broadcast" 1 "Start Broadcast" 2 "Reserved" 3 "Don't Care/take no action (leave as is)" ;
VAL_ 2564816638 CurrentDataLink 0 "Stop Broadcast" 1 "Start Broadcast" 2 "Reserved" 3 "Don't Care/take no action (leave as is)" ;
VAL_ 2564816638 Other_ManufacturerSpecifiedPort 0 "Stop Broadcast" 1 "Start Broadcast" 2 "Reserved" 3 "Don't Care/take no action (leave as is)" ;
VAL_ 2564816638 J1850 0 "Stop Broadcast" 1 "Start Broadcast" 2 "Reserved" 3 "Don't Care/take no action (leave as is)" ;
VAL_ 2564816638 ISO9141 0 "Stop Broadcast" 1 "Start Broadcast" 2 "Reserved" 3 "Don't Care/take no action (leave as is)" ;
VAL_ 2564816638 J1939Network2 0 "Stop Broadcast" 1 "Start Broadcast" 2 "Reserved" 3 "Don't Care/take no action (leave as is)" ;
VAL_ 2564816638 J1939Network4 0 "Stop Broadcast" 1 "Start Broadcast" 2 "Reserved" 3 "Don't Care/take no action (leave as is)" ;
VAL_ 2564816638 ProprietaryNetwork2 0 "Stop Broadcast" 1 "Start Broadcast" 2 "Reserved" 3 "Don't Care/take no action (leave as is)" ;
VAL_ 2564816638 ProprietaryNetwork1 0 "Stop Broadcast" 1 "Start Broadcast" 2 "Reserved" 3 "Don't Care/take no action (leave as is)" ;
VAL_ 2564816638 J1939Network3 0 "Stop Broadcast" 1 "Start Broadcast" 2 "Reserved" 3 "Don't Care/take no action (leave as is)" ;
VAL_ 2564816638 SuspendSignal 0 "Indefinite suspension of all broadcasts" 1 "Indefinite suspension of some messages" 2 "Temporary suspension of all broadcasts" 3 "Temporary suspension of some messages" 14 "Resuming normal broadcast pattern" 15 "Not Available" ;
VAL_ 2564816638 HoldSignal 0 "All Devices" 1 "Devices whose broadcast state has been modified" 15 "Not Available" ;
VAL_ 2564882174 AuxHeaterCoolantPumpRequest 0 "Deactivate water pump" 1 "Activate water pump" 2 "Reserved" 3 "Don't care/take no action" ;
VAL_ 2564882174 BatteryMainSwitchHoldRequest 0 "Release Battery Main Switch" 1 "Hold Battery Main Switch" 2 "undefined" 3 "Don't care/take no action" ;
VAL_ 2564882174 OperatorSeatDirectionSwitch 0 "Operator seat not facing forward" 1 "Operator seat is facing forward" 2 "Error" 3 "Not Available" ;
VAL_ 2564882174 SeatBeltSwitch 0 "NOT Buckled" 1 "OK - Seat Belt is buckled" 2 "Error - Switch state cannot be determined" 3 "Not Available" ;
VAL_ 2564882174 ParkBrakeCommand 0 "Park Brake apply not requested" 1 "Park Brake apply requested" 2 "SAE Reserved  " 3 "Don't care/Take no action" ;
VAL_ 2564882174 VehicleLmtngSpdGvrnrDecrementSw 0 "Switch in the off state" 1 "Switch in the on state - decrease" 2 "Error" 3 "Not available" ;
VAL_ 2564882174 VehicleLmtngSpdGvrnrIncrementSw 0 "Switch in the off state" 1 "Switch in the on state - increase" 2 "Error" 3 "Not available" ;
VAL_ 2564882174 VehicleLmtngSpeedGvrnrEnblSwitch 0 "Switch disabled" 1 "Switched enabled" 2 "Error" 3 "Not available" ;
VAL_ 2564882174 AftrtrtmntRegenInhbtSwitch 0 "not active" 1 "active" 2 "error" 3 "not available" ;
VAL_ 2564882174 AftrtrtmntRegenForceSwitch 0 "not active" 1 "active" 2 "error" 3 "not available" ;
VAL_ 2564882174 AutoGearShiftingEnableSwitch 0 "Automated Gear Shifting is disabled" 1 "Automated Gear Shifting is enabled" 2 "error" 3 "Not available" ;
VAL_ 2564882174 EngineAutomaticStartEnableSwitch 0 "Switch in the off state" 1 "Switch in the on state" 2 "Error" 3 "Not available" ;
VAL_ 2564882174 AuxiliaryHeaterModeRequest 0 "De-activate auxiliary heater" 1 "Off due to ADR" 2 "Economy mode" 3 "Normal mode" 4 "Heater pump up-keep" 14 "Reserved" 15 "Don't care/take no action" ;
VAL_ 2564882174 RequestEngineZoneHeating 0 "Do not heat engine zone" 1 "Heat engine zone" 2 "Reserved" 3 "Don't care/take no action" ;
VAL_ 2564882174 RequestCabZoneHeating 0 "Do not heat cab engine zone" 1 "Heat cab zone" 2 "Reserved" 3 "Don't care/take no action" ;
VAL_ 2565668606 ConnectionAbortReason 1 "Already connected" 2 "System resources needed" 3 "Timeout occurred" 251 "Per J1939-71 definitions" ;
VAL_ 2565865726 RetarderTorqueMode 0 "No request" ;
VAL_ 2565865726 RetarderEnableBrakeAssistSwitch 0 "Retarder - brake assist disabled" 1 "Retarder - brake assist enabled" 2 "Error" 3 "Not available" ;
VAL_ 2565865726 RetarderEnableShiftAssistSwitch 0 "Retarder - shift assist disabled" 1 "Retarder - shift assist enabled" 2 "Error" 3 "Not available" ;
VAL_ 2565865726 EngineCoolantLoadIncrease 0 "No coolant load increase" 1 "Coolant load increase possible" 2 "Error" 3 "Not available" ;
VAL_ 2565865726 RetarderRequestingBrakeLight 0 "Retarder is not requesting" 1 "Retarder is requesting" 2 "Reserved" 3 "Not available" ;
VAL_ 2565865726 RetarderRoadSpeedLimitSwitch 0 "Road speed limiting by retarder is disabled" 1 "Road speed limiting by retarder is enabled" 2 "Error Indicator" 3 "Not Available" ;
VAL_ 2565865726 RetarderRoadSpeedExceededStatus 0 "Road speed is below threshold " 1 "Road speed is above threshold and retarder is allowed to be activated" 2 "Reserved" 3 "Don't care/Take no action" ;
VAL_ 2565865982 ASREngineControlActive 0 "ASR engine control passive but installed" 1 "ASR engine control active" 2 "Reserved" 3 "Not available" ;
VAL_ 2565865982 ASRBrakeControlActive 0 "ASR brake control passive but installed" 1 "ASR brake control active" 2 "Reserved" 3 "Not available" ;
VAL_ 2565865982 AntiLockBrakingActive 0 "ABS passive but installed" 1 "ABS active" 2 "Reserved" 3 "Not available" ;
VAL_ 2565865982 EBSBrakeSwitch 0 "Brake pedal is not being pressed" 1 "Brake pedal is being pressed" 2 "Error" 3 "Not available" ;
VAL_ 2565865982 ABSOffRoadSwitch 0 "ABS off-road switch passive" 1 "ABS off-road switch active" 2 "Error" 3 "Not available" ;
VAL_ 2565865982 ASROffRoadSwitch 0 "ASR off-road switch passive" 1 "ASR off-road switch active" 2 "Error" 3 "Not available" ;
VAL_ 2565865982 ASRHillHolderSwitch 0 "ASR 'hill holder' switch passive" 1 "ASR 'hill holder' switch active" 2 "Error" 3 "Not available" ;
VAL_ 2565865982 TractionControlOverrideSwitch 0 "Off" 1 "On" 2 "Error" 3 "Not available or not installed" ;
VAL_ 2565865982 AcceleratorInterlockSwitch 0 "Off" 1 "On" 2 "Error" 3 "Not available" ;
VAL_ 2565865982 EngineDerateSwitch 0 "Off" 1 "On" 2 "Error" 3 "Not available" ;
VAL_ 2565865982 EngineAuxiliaryShutdownSwitch 0 "Off" 1 "On" 2 "Error" 3 "Not available" ;
VAL_ 2565865982 RemoteAcceleratorEnableSwitch 0 "Off" 1 "On" 2 "Error" 3 "Not available" ;
VAL_ 2565865982 ABSFullyOperational 0 "Not Fully Operational" 1 "Fully Operational" 2 "Reserved" 3 "Not available" ;
VAL_ 2565865982 EBSRedWarningSignal 0 "Off" 1 "On" 2 "Reserved" 3 "Take no action" ;
VAL_ 2565865982 ABSEBSAmberWarningSignal 0 "Off" 1 "On" 2 "Reserved" 3 "Take no action" ;
VAL_ 2565865982 ATCASRInformationSignal 0 "Off" 1 "On" 2 "Reserved" 3 "Take no action" ;
VAL_ 2565865982 RailroadModeSwitch 0 "Railroad mode switch passive" 1 "Railroad mode switch active" 2 "Error" 3 "Not available" ;
VAL_ 2565865982 HaltBrakeSwitch 0 "Halt brake switch passive" 1 "Halt brake switch active" 2 "Error" 3 "Not available" ;
VAL_ 2565865982 TrailerABSStatus 0 "Information Available Not Active" 1 "Active" 2 "Reserved" 3 "Information Not Available" ;
VAL_ 2565865982 TractorMntdTrailerABSWarningSig 0 "Off" 1 "On" 2 "Reserved" 3 "Take no action" ;
VAL_ 2364539646 TransmissionDrivelineEngaged 0 "Driveline disengaged" 1 "Driveline engaged" 2 "Error" 3 "Not available" ;
VAL_ 2364539646 TransmissionTrqCnvLockupEngaged 0 "Torque converter lockup disengaged" 1 "Torque converter lockup engaged" 2 "Error" 3 "Not available" ;
VAL_ 2364539646 TransmissionShiftInProcess 0 "Shift is not in process " 1 "Shift in process" 2 "Error" 3 "Not available" ;
VAL_ 2364539646 TrnsmTrqCnvLockupTrnstionInPrcss 0 "Transition is not in process" 1 "Transition is in process" 2 "Error" 3 "Not available" ;
VAL_ 2364539646 EngineMomentaryOverspeedEnable 0 "Momentary engine overspeed is disabled" 1 "Momentary engine overspeed is enabled" 2 "Reserved" 3 "Take no action" ;
VAL_ 2364539646 ProgressiveShiftDisable 0 "Progressive shift is not disabled" 1 "Progressive shift is disabled" 2 " Reserved" 3 "Take no action" ;
VAL_ 2364539646 MomentaryEngineMaximumPowerEnbl 0 "not requesting maximum power available" 1 "momentarily requesting maximum power available" 2 "fault" 3 "not available" ;
VAL_ 2364539902 AcceleratorPedal1LowIdleSwitch 0 "Accelerator pedal 1 not in low idle condition" 1 "Accelerator pedal 1 in low idle condition" 2 "Error" 3 "Not available" ;
VAL_ 2364539902 AcceleratorPedalKickdownSwitch 0 "Kickdown passive" 1 "Kickdown active" 2 "Error" 3 "Not available" ;
VAL_ 2364539902 RoadSpeedLimitStatus 0 "Active" 1 "Not Active" 2 "Error" 3 "Not available" ;
VAL_ 2364539902 AcceleratorPedal2LowIdleSwitch 0 "Accelerator pedal 2 not in low idle condition" 1 "Accelerator pedal 2 in low idle condition" 2 "Error" 3 "Not available" ;
VAL_ 2364539902 VehicleAccltnRateLimitStatus 0 "Limit not active" 1 "Limit active" 2 "Reserved" 3 "Not available" ;
VAL_ 2364539902 MomentaryEngMaxPowerEnblFdbck 0 "disabled" 1 "supported " 2 "reserved" 3 "don't care" ;
VAL_ 2364539902 DPFThermalManagementActive 0 "DPF Thermal Management is not active" 1 "DPF Thermal Management is active" 2 "Reserved" 3 "Don't care" ;
VAL_ 2364539902 SCRThermalManagementActive 0 "SCR Thermal Management is not active" 1 "SCR Thermal Management is active" 2 "Reserved" 3 "Don't care" ;
VAL_ 2364540158 ActualEnginePercentTorqueFract 0 "+0.000%" 1 "+0.125%" 2 "+0.250%" 3 "+0.375%" 4 "+0.500%" 5 "+0.625%" 6 "+0.750%" 7 "+0.875%" 8 "not available" ;
VAL_ 2364540158 EngineStarterMode 0 "start not requested" 1 "starter active: gear not engaged" 2 "starter active: gear engaged" 3 "start finished: starter not active" 4 "starter inhibited: engine running" 5 "starter inhibited: engine not ready for start" 6 "starter inhibited: driveline engaged" 7 "starter inhibited: active immobilizer" 8 "starter inhibited: starter over-temp" 9 "starter inhibited: intake air shutoff valve" 10 "starter inhibited: active SCR" 11 "Reserved" 12 "starter inhibited: reason unknown" 13 "error (legacy implementation only, use 1110)" 14 "error" 15 "not available" ;
VAL_ 2565867262 DifferentialLockStateFrontAxle1 0 "Differential lock disengaged" 1 "Differential lock engaged" 2 "Error" 3 "Not available" ;
VAL_ 2565867262 DifferentialLockStateFrontAxle2 0 "Differential lock disengaged" 1 "Differential lock engaged" 2 "Error" 3 "Not available" ;
VAL_ 2565867262 DifferentialLockStateRearAxle1 0 "Differential lock disengaged" 1 "Differential lock engaged" 2 "Error" 3 "Not available" ;
VAL_ 2565867262 DifferentialLockStateRearAxle2 0 "Differential lock disengaged" 1 "Differential lock engaged" 2 "Error" 3 "Not available" ;
VAL_ 2565867262 DifferentialLockStateCentral 0 "Differential lock disengaged" 1 "Differential lock engaged" 2 "Error" 3 "Not available" ;
VAL_ 2565867262 DiffLockStateCentralFront 0 "Differential lock disengaged" 1 "Differential lock engaged" 2 "Error" 3 "Not available" ;
VAL_ 2565867262 DifferentialLockStateCentralRear 0 "Differential lock disengaged" 1 "Differential lock engaged" 2 "Error" 3 "Not available" ;
VAL_ 2565867262 DifferentialLockStateRearAxle3 0 "Differential lock disengaged" 1 "Differential lock engaged" 2 "Error" 3 "Not available" ;
VAL_ 2565867262 FrontAxleGroupEngagementStatus 0 "front axle group disengaged" 1 "front axle group engaged" 2 "error" 3 "not available" ;
VAL_ 2565867262 RearAxleGroupEngagementStatus 0 "rear axle group disengaged" 1 "rear axle group engaged" 2 "error" 3 "not available" ;
VAL_ 2431649790 LaneDepartureLeft 0 "Middle of the vehicle not depart" 1 "Middle of the vehicle departs" 2 "Reserved" 3 "Take no action" ;
VAL_ 2431649790 LaneDepartureRight 0 "Middle of the vehicle not depart" 1 "Middle of the vehicle departs" 2 "Reserved" 3 "Take no action" ;
VAL_ 2431649790 LaneDepartureImminent_RightSide 0 "Not imminent" 1 "Imminent" 2 "Reserved" 3 "Not Used" ;
VAL_ 2431649790 LaneDepartureImminent_LeftSide 0 "Not imminent" 1 "Imminent" 2 "Reserved" 3 "Not Used" ;
VAL_ 2431649790 DriverAlertnessWarning 0 "No distracted driving condition detected" 1 "Level 1" 2 "Level 2" 3 "Level 3" 7 "Not Available" ;
VAL_ 2431649790 RghtSdeLaneDepartrOptclWrngCmd 0 "No optical warning on the right side" 1 "Active optical warning on the right side" 2 "Reserved" 3 "Not available" ;
VAL_ 2431649790 LftSdeLaneDepartrOptclWarningCmd 0 "No optical warning on the left side" 1 "Active optical warning on the left side" 2 "Reserved" 3 "Not available" ;
VAL_ 2431649790 RghtSdeLaneDepartrAcstclWrngCmd 0 "No acoustical warning on the right side" 1 "Active acoustical warning on the right side" 2 "Reserved" 3 "Not available" ;
VAL_ 2431649790 LftSdeLaneDepartrAcstclWrngCmd 0 "No acoustical warning on the left side" 1 "Active acoustical warning on the left side" 2 "Reserved" 3 "Not available" ;
VAL_ 2565867774 EngHydrPressureGvrnrModeIndictr 0 "Disabled" 1 "Enabled" 2 "Error Indicator" 3 "Not Available" ;
VAL_ 2565867774 EngHydraulicPressureGvrnrSwitch 0 "Pressure Mode Inactive" 1 "Pressure Mode Active" 2 "Error Indicator" 3 "Not Available" ;
VAL_ 2565867774 FireApparatusPumpEngagement 0 "Pump not engaged" 1 "Pump engaged" 2 "Error" 3 "Not available or not installed" ;
VAL_ 2565867774 FireApparatusOkayToPumpInterlock 0 "Okay to Pump Interlock Inactive" 1 "Okay to Pump Interlock Active" 2 "Error" 3 "Not Available" ;
VAL_ 2565867774 HydraulicPressureGvrnrIdleSwitch 0 "Idle Switch Inactive" 1 "Idle Switch Active" 2 "Error" 3 "Not available" ;
VAL_ 2565867774 HydrPressureGvrnrDecreaseSwitch 0 "Decrease Switch Inactive" 1 "Decrease Switch Active" 2 "Error" 3 "Not available" ;
VAL_ 2565867774 HydrPressureGvrnrIncreaseSwitch 0 "Increase Switch Inactive" 1 "Increase Switch Active" 2 "Error" 3 "Not available" ;
VAL_ 2565867774 HydrPressureGvrnrPresetSwitch 0 "Preset Switch Inactive" 1 "Preset Switch Active" 2 "Error" 3 "Not available" ;
VAL_ 2565868030 SteeringWheelAngleSensorType 0 "Relative measuring principle" 1 "Absolute measuring principle" 2 "Reserved" 3 "Not Available" ;
VAL_ 2565868542 StatusOfSteeringAxle 0 "Axle steering not active" 1 "Axle steering active" 2 "Axle centered" 3 "Axle centered, because of an error" 4 "Axle not active because of an error" 5 "Axle steering in special mode" 15 "Not available" ;
VAL_ 2565868542 SteerableLiftAxleLoweringInhibit 0 "Lowering allowed" 1 "Lowering inhibited" 2 "Reserved" 3 "Not available" ;
VAL_ 2565868542 SteeringType 0 "Main steering system" 1 "Auxiliary steering equipment" 15 "Not Available" ;
VAL_ 2565868542 TypeOfSteeringForces 0 "Manual steering equipment" 1 "Power assisted steering equipment" 2 "Full power steering equipment" 3 "Self tracking steering equipment" 15 "Not Available" ;
VAL_ 2565868542 TypeOfSteeringTransmission 0 "Purely mechanical steering transmission" 1 "Purely hydraulic steering transmission" 2 "Purely electric steering transmission" 3 "Hybrid steering transmission" 15 "Not available" ;
VAL_ 2364542462 BladeControlModeSwitch 0 "No button pressed" 1 "Mode button pressed" 2 "Manual button pressed" 3 "Automatic button pressed" 14 "Error Indicator" 15 "Not Installed" ;
VAL_ 2364542462 DesiredGradeOffsetSwitch 0 "No button pressed" 1 "Increment button pressed" 2 "Decrement button pressed" 14 "Error Indicator" 15 "Not installed" ;
VAL_ 2364542462 LeftBldCtrlModeOperatorControl 0 "No Change" 1 "Momentary Operator Control Request" 2 "Manual Operator Control Request" 3 "Automatic Operator Control Request" 14 "Error Indicator" 15 "Not Installed" ;
VAL_ 2364542462 RightBldCtrlModeOperatorControl 0 "No Change" 1 "Momentary Operator Control Request" 2 "Manual Operator Control Request" 3 "Automatic Operator Control Request" 14 "Error Indicator" 15 "Not Installed" ;
VAL_ 2364542462 LeftDesiredBldOffsetOperatorCtrl 0 "No Operator Control Request" 1 "Increment Operator Control Request" 2 "Decrement Operator Control Request" 14 "Error Indicator" 15 "Not installed" ;
VAL_ 2364542462 RightDsrdBldOffsetOperatorCtrl 0 "No Operator Control Request" 1 "Increment Operator Control Request" 2 "Decrement Operator Control Request" 14 "Error Indicator" 15 "Not installed" ;
VAL_ 2364542462 SideShiftBldCtrlModeOperatorCtrl 0 "No Operator Control Request" 1 "Increment Operator Control Request" 2 "Decrement Operator Control Request" 14 "Error Indicator" 15 "Not installed" ;
VAL_ 2364542462 SideShiftDsrdBldOffstOprtrCtrl 0 "No Operator Control Request" 1 "Momentary Operator Control Request" 2 "Manual Operator Control Request" 3 "Automatic Operator Control Request" 14 "Error Indicator" 15 "Not Installed" ;
VAL_ 2364542462 SetElevationSensor1RefElevation 0 "Do not Set Reference Elevation" 1 "Set Reference Elevation" 2 "Reserved" 3 "Don't Care / Take No Action" ;
VAL_ 2364542462 SetElevationSensor2RefElevation 0 "Do not Set Reference Elevation" 1 "Set Reference Elevation" 2 "Reserved" 3 "Don't Care / Take No Action" ;
VAL_ 2565869310 Aftrtrtmnt1IntkGasSensorPwrInRng 0 "Not in range" 1 "In range" 2 "Error" 3 "Not available" ;
VAL_ 2565869310 Aftrtrtmnt1IntkGasSnsrAtTemp 0 "Not in range" 1 "In range" 2 "Error" 3 "Not available" ;
VAL_ 2565869310 Aft1SlctiveCtlytcRedIntkNOxRdngS 0 "Not stable" 1 "Stable" 2 "Error" 3 "Not available" ;
VAL_ 2565869310 Aft1IntkWdRngPrcntO2RdngStable 0 "Not stable" 1 "Stable" 2 "Error" 3 "Not available" ;
VAL_ 2565869310 Aftrtrtmnt1IntkGasSensorHtrCtrl 0 "Automatic" 1 "Preheat 2" 2 "Preheat 1" 3 "Heater off" ;
VAL_ 2565869310 Aft1IntkNOxSnsrSelfDiagnssStat 0 "Diagnosis not active" 1 "NOx Sensor ATI1 Self Diagnosis active flag" 2 "NOx Sensor ATI1 Self Diagnosis Result Complete" 3 "NOx Sensor ATI1 Self Diagnosis aborted" 4 "NOx Sensor ATI1 Self Diagnosis not possible" 7 "Not Supported" ;
